VERSION "12.2.7"

NS_ :

BS_:

BU_: BMS_Tester EDS_F EDS_R EPS2 FCAM_PT GS IDB_PT POD RCU_PT VCU_PT XGW_PT

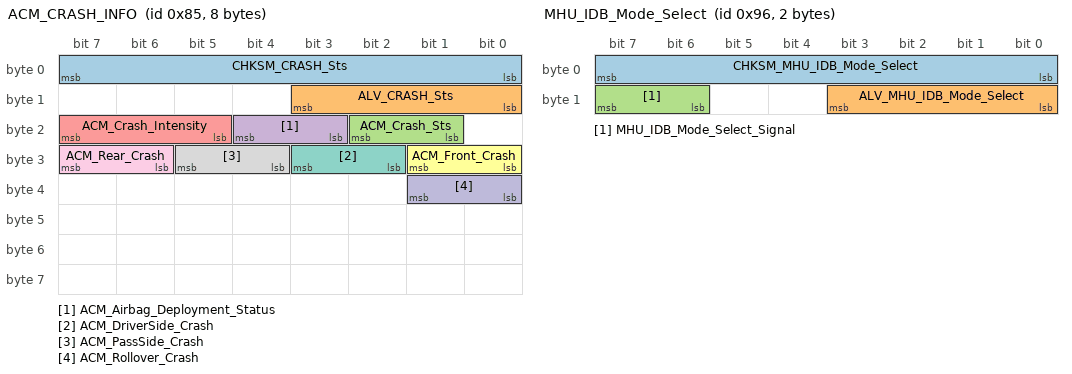
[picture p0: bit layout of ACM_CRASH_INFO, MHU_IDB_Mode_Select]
BO_ 133 ACM_CRASH_INFO: 8 XGW_PT
 SG_ CHKSM_CRASH_Sts : 7|8@0+ (1,0) [0|255] ""  EDS_F,EDS_R,IDB_PT,VCU_PT
 SG_ ALV_CRASH_Sts : 11|4@0+ (1,0) [0|14] ""  EDS_F,EDS_R,IDB_PT,VCU_PT
 SG_ ACM_Crash_Sts : 18|2@0+ (1,0) [0|3] ""  EDS_F,EDS_R,IDB_PT,VCU_PT
 SG_ ACM_Airbag_Deployment_Status : 20|2@0+ (1,0) [0|3] "-"  IDB_PT,VCU_PT
 SG_ ACM_Crash_Intensity : 23|3@0+ (1,0) [0|7] ""  IDB_PT,VCU_PT
 SG_ ACM_Front_Crash : 25|2@0+ (1,0) [0|3] "-"  IDB_PT,VCU_PT
 SG_ ACM_DriverSide_Crash : 27|2@0+ (1,0) [0|3] ""  IDB_PT,VCU_PT
 SG_ ACM_PassSide_Crash : 29|2@0+ (1,0) [0|3] "-"  IDB_PT,VCU_PT
 SG_ ACM_Rear_Crash : 31|2@0+ (1,0) [0|3] "-"  IDB_PT,VCU_PT
 SG_ ACM_Rollover_Crash : 33|2@0+ (1,0) [0|3] "-"  IDB_PT,VCU_PT

BO_ 147 IDB_MILEAGE: 4 IDB_PT
 SG_ CHKSM_MILEAGE : 7|8@0+ (1,0) [0|255] ""  FCAM_PT,XGW_PT
 SG_ ALIVE_MILEAGE : 11|4@0+ (1,0) [0|14] ""  FCAM_PT,XGW_PT
 SG_ Mileage : 23|16@0+ (1,0) [0|65535] "cm"  FCAM_PT,XGW_PT

BO_ 148 VCU_PUMP_STATUS: 8 VCU_PT
 SG_ VCU_Pump_3_Stt : 7|3@0+ (1,0) [0|3] ""  POD
 SG_ VCU_Pump_3_Flowrate : 15|8@0+ (0.1,0) [0|25.4] "l/min"  POD

BO_ 149 IDB_FUNCTION: 8 IDB_PT
 SG_ CHKSM_IDB_FUNCTION : 7|8@0+ (1,0) [0|255] ""  EDS_F,EDS_R,FCAM_PT,VCU_PT,XGW_PT
 SG_ ALV_IDB_FUNCTION : 11|4@0+ (1,0) [0|14] ""  EDS_F,EDS_R,FCAM_PT,VCU_PT,XGW_PT
 SG_ STAT_ABS : 13|2@0+ (1,0) [0|3] ""  VCU_PT,XGW_PT
 SG_ ABS_Active : 15|2@0+ (1,0) [0|3] ""  EDS_F,EDS_R,FCAM_PT,VCU_PT,XGW_PT
 SG_ AYC_Active : 17|2@0+ (1,0) [0|3] "Bit"  FCAM_PT,VCU_PT,XGW_PT
 SG_ ASR_Active : 19|2@0+ (1,0) [0|3] "-"  EDS_F,EDS_R,FCAM_PT,VCU_PT,XGW_PT
 SG_ STAT_DSC : 21|2@0+ (1,0) [0|3] "-"  FCAM_PT,VCU_PT,XGW_PT
 SG_ DSC_Active : 23|2@0+ (1,0) [0|3] ""  FCAM_PT,VCU_PT,XGW_PT
 SG_ HBA_ActiveSignal : 25|2@0+ (1,0) [0|3] ""  FCAM_PT,VCU_PT,XGW_PT
 SG_ ARM_ActiveSignal : 27|2@0+ (1,0) [0|3] "-"  VCU_PT,XGW_PT
 SG_ STAT_AutoHazardBlinking : 29|2@0+ (1,0) [0|3] "Bit"  VCU_PT,XGW_PT
 SG_ MSR_Active : 31|2@0+ (1,0) [0|3] "-"  FCAM_PT,VCU_PT,XGW_PT
 SG_ HSA_ActiveSignal : 33|2@0+ (1,0) [0|3] ""  FCAM_PT,VCU_PT,XGW_PT
 SG_ EPBi_ECD_ActiveSignal : 35|2@0+ (1,0) [0|3] ""  FCAM_PT,VCU_PT,XGW_PT
 SG_ TSM_Active : 37|2@0+ (1,0) [0|3] "-"  FCAM_PT,VCU_PT,XGW_PT
 SG_ HAS_Available : 41|2@0+ (1,0) [0|3] ""  FCAM_PT,VCU_PT,XGW_PT
 SG_ STAT_EBD : 43|2@0+ (1,0) [0|3] ""  VCU_PT,XGW_PT
 SG_ EBD_Active : 45|2@0+ (1,0) [0|3] ""  FCAM_PT,VCU_PT,XGW_PT
 SG_ ST_BRG_MSA : 55|4@0+ (1,0) [0|15] ""  VCU_PT,XGW_PT

BO_ 150 MHU_IDB_Mode_Select: 2 XGW_PT
 SG_ CHKSM_MHU_IDB_Mode_Select : 7|8@0+ (1,0) [0|255] ""  IDB_PT
 SG_ ALV_MHU_IDB_Mode_Select : 11|4@0+ (1,0) [0|14] ""  IDB_PT
 SG_ MHU_IDB_Mode_Select_Signal : 15|2@0+ (1,0) [0|3] ""  IDB_PT

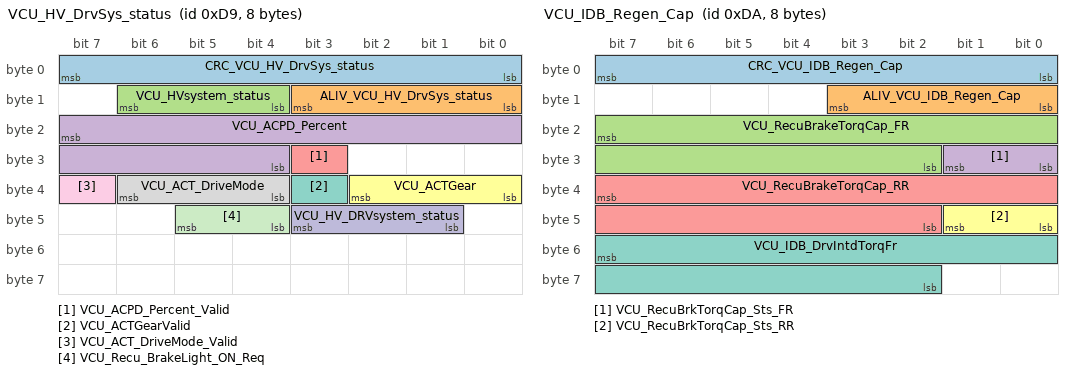
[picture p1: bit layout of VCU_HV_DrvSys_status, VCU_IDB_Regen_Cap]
BO_ 217 VCU_HV_DrvSys_status: 8 VCU_PT
 SG_ CRC_VCU_HV_DrvSys_status : 7|8@0+ (1,0) [0|255] ""  EDS_F,EDS_R,EPS2,FCAM_PT,GS,IDB_PT,RCU_PT,XGW_PT
 SG_ ALIV_VCU_HV_DrvSys_status : 11|4@0+ (1,0) [0|14] ""  EDS_F,EDS_R,EPS2,FCAM_PT,GS,IDB_PT,RCU_PT,XGW_PT
 SG_ VCU_HVsystem_status : 14|3@0+ (1,0) [0|7] "-"  EDS_F,EDS_R,EPS2,FCAM_PT,IDB_PT,XGW_PT
 SG_ VCU_ACPD_Percent : 23|12@0+ (0.0625,0) [0|100] "%"  FCAM_PT,IDB_PT,RCU_PT,XGW_PT
 SG_ VCU_ACPD_Percent_Valid : 27|1@0+ (1,0) [0|1] ""  FCAM_PT,IDB_PT,RCU_PT,XGW_PT
 SG_ VCU_ACTGear : 34|3@0+ (1,0) [0|7] ""  FCAM_PT,EPS2,GS,IDB_PT,RCU_PT,XGW_PT
 SG_ VCU_ACTGearValid : 35|1@0+ (1,0) [0|1] ""  FCAM_PT,EPS2,GS,IDB_PT,XGW_PT
 SG_ VCU_ACT_DriveMode : 38|3@0+ (1,0) [0|7] ""  FCAM_PT,XGW_PT
 SG_ VCU_ACT_DriveMode_Valid : 39|1@0+ (1,0) [0|1] "-"  XGW_PT
 SG_ VCU_HV_DRVsystem_status : 43|3@0+ (1,0) [0|7] ""  FCAM_PT,XGW_PT
 SG_ VCU_Recu_BrakeLight_ON_Req : 45|2@0+ (1,0) [0|3] "-"  XGW_PT

BO_ 218 VCU_IDB_Regen_Cap: 8 VCU_PT
 SG_ CRC_VCU_IDB_Regen_Cap : 7|8@0+ (1,0) [0|255] ""  IDB_PT
 SG_ ALIV_VCU_IDB_Regen_Cap : 11|4@0+ (1,0) [0|14] ""  IDB_PT
 SG_ VCU_RecuBrakeTorqCap_FR : 23|14@0- (1,0) [-8000|8000] "Nm"  IDB_PT
 SG_ VCU_RecuBrkTorqCap_Sts_FR : 25|2@0+ (1,0) [0|3] ""  IDB_PT
 SG_ VCU_RecuBrakeTorqCap_RR : 39|14@0- (1,0) [-8000|8000] "Nm"  IDB_PT
 SG_ VCU_RecuBrkTorqCap_Sts_RR : 41|2@0+ (1,0) [0|3] ""  IDB_PT
 SG_ VCU_IDB_DrvIntdTorqFr : 55|14@0- (1,0) [-8000|8000] "Nm"  IDB_PT

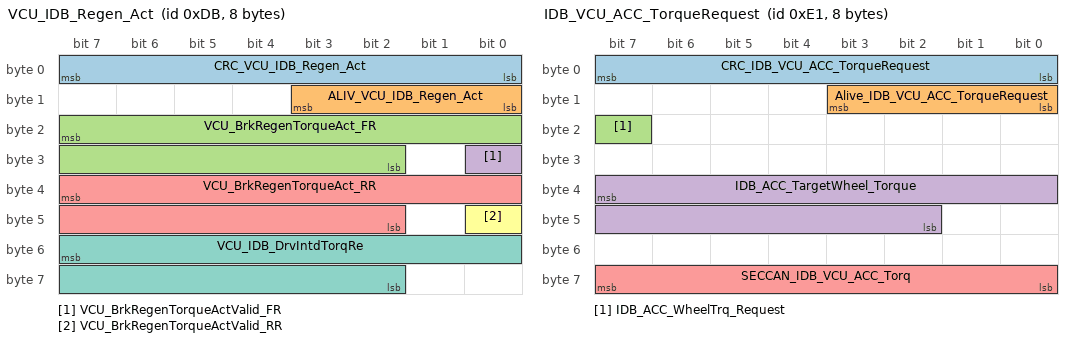
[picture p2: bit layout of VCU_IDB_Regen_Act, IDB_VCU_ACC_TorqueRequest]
BO_ 219 VCU_IDB_Regen_Act: 8 VCU_PT
 SG_ CRC_VCU_IDB_Regen_Act : 7|8@0+ (1,0) [0|255] ""  IDB_PT
 SG_ ALIV_VCU_IDB_Regen_Act : 11|4@0+ (1,0) [0|14] ""  IDB_PT
 SG_ VCU_BrkRegenTorqueAct_FR : 23|14@0- (1,0) [-8000|8000] "Nm"  IDB_PT
 SG_ VCU_BrkRegenTorqueActValid_FR : 24|1@0+ (1,0) [0|1] ""  IDB_PT
 SG_ VCU_BrkRegenTorqueAct_RR : 39|14@0- (1,0) [-8000|8000] "Nm"  IDB_PT
 SG_ VCU_BrkRegenTorqueActValid_RR : 40|1@0+ (1,0) [0|1] ""  IDB_PT
 SG_ VCU_IDB_DrvIntdTorqRe : 55|14@0- (1,0) [-8000|8000] "Nm"  IDB_PT

BO_ 225 IDB_VCU_ACC_TorqueRequest: 8 IDB_PT
 SG_ CRC_IDB_VCU_ACC_TorqueRequest : 7|8@0+ (1,0) [0|255] ""  VCU_PT
 SG_ Alive_IDB_VCU_ACC_TorqueRequest : 11|4@0+ (1,0) [0|14] ""  VCU_PT
 SG_ IDB_ACC_WheelTrq_Request : 23|1@0+ (1,0) [0|1] ""  VCU_PT
 SG_ IDB_ACC_TargetWheel_Torque : 39|14@0- (1,0) [-8000|8000] "Nm"  VCU_PT
 SG_ SECCAN_IDB_VCU_ACC_Torq : 63|8@0+ (1,0) [0|255] ""  VCU_PT

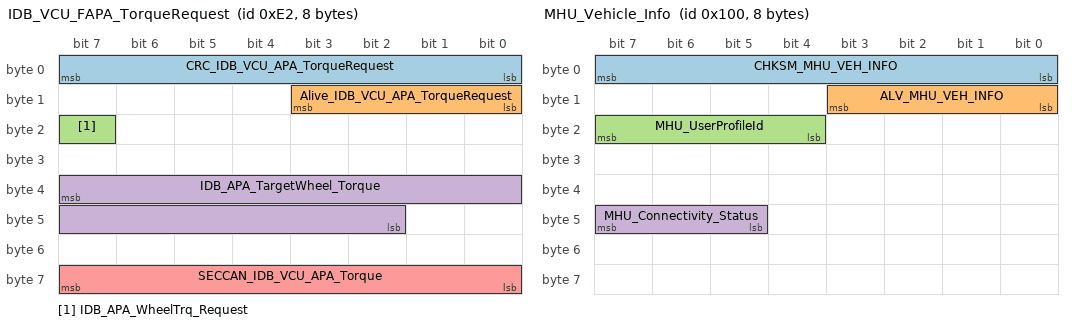
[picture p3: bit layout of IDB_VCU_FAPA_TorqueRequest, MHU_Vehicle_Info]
BO_ 226 IDB_VCU_FAPA_TorqueRequest: 8 IDB_PT
 SG_ CRC_IDB_VCU_APA_TorqueRequest : 7|8@0+ (1,0) [0|255] ""  VCU_PT
 SG_ Alive_IDB_VCU_APA_TorqueRequest : 11|4@0+ (1,0) [0|14] ""  VCU_PT
 SG_ IDB_APA_WheelTrq_Request : 23|1@0+ (1,0) [0|1] ""  VCU_PT
 SG_ IDB_APA_TargetWheel_Torque : 39|14@0- (1,0) [-8000|8000] "Nm"  VCU_PT
 SG_ SECCAN_IDB_VCU_APA_Torque : 63|8@0+ (1,0) [0|255] ""  VCU_PT

BO_ 256 MHU_Vehicle_Info: 8 XGW_PT
 SG_ CHKSM_MHU_VEH_INFO : 7|8@0+ (1,0) [0|255] ""  VCU_PT
 SG_ ALV_MHU_VEH_INFO : 11|4@0+ (1,0) [0|14] ""  VCU_PT
 SG_ MHU_UserProfileId : 23|4@0+ (1,0) [0|15] "-"  VCU_PT
 SG_ MHU_Connectivity_Status : 47|3@0+ (1,0) [0|7] ""  VCU_PT

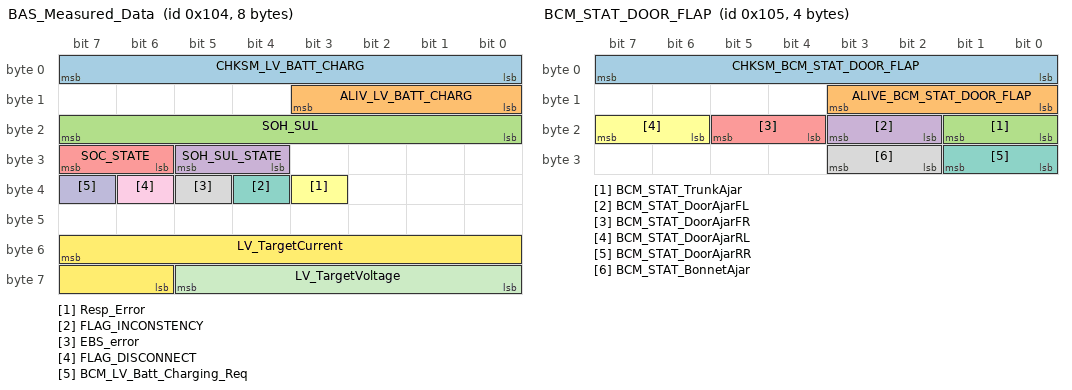
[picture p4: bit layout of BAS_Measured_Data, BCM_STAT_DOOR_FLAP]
BO_ 260 BAS_Measured_Data: 8 XGW_PT
 SG_ CHKSM_LV_BATT_CHARG : 7|8@0+ (1,0) [0|255] ""  VCU_PT
 SG_ ALIV_LV_BATT_CHARG : 11|4@0+ (1,0) [0|14] ""  VCU_PT
 SG_ SOH_SUL : 23|8@0+ (1,0) [0|100] "%"  VCU_PT
 SG_ SOH_SUL_STATE : 29|2@0+ (1,0) [0|3] ""  VCU_PT
 SG_ SOC_STATE : 31|2@0+ (1,0) [0|3] "%"  VCU_PT
 SG_ Resp_Error : 35|1@0+ (1,0) [0|1] ""  VCU_PT
 SG_ FLAG_INCONSTENCY : 36|1@0+ (1,0) [0|1] "%"  VCU_PT
 SG_ EBS_error : 37|1@0+ (1,0) [0|1] ""  VCU_PT
 SG_ FLAG_DISCONNECT : 38|1@0+ (1,0) [0|1] ""  VCU_PT
 SG_ BCM_LV_Batt_Charging_Req : 39|1@0+ (1,0) [0|1] ""  VCU_PT
 SG_ LV_TargetVoltage : 61|6@0+ (0.112903,9) [9|16] "V"  VCU_PT
 SG_ LV_TargetCurrent : 55|10@0+ (0.25,-128) [-128|127] "A"  VCU_PT

BO_ 261 BCM_STAT_DOOR_FLAP: 4 XGW_PT
 SG_ CHKSM_BCM_STAT_DOOR_FLAP : 7|8@0+ (1,0) [0|255] ""  IDB_PT,RCU_PT,VCU_PT
 SG_ ALIVE_BCM_STAT_DOOR_FLAP : 11|4@0+ (1,0) [0|14] ""  IDB_PT,RCU_PT,VCU_PT
 SG_ BCM_STAT_TrunkAjar : 17|2@0+ (1,0) [0|3] "Bit"  IDB_PT,VCU_PT
 SG_ BCM_STAT_DoorAjarFL : 19|2@0+ (1,0) [0|3] "Bit"  IDB_PT,RCU_PT,VCU_PT
 SG_ BCM_STAT_DoorAjarFR : 21|2@0+ (1,0) [0|3] "Bit"  IDB_PT,VCU_PT
 SG_ BCM_STAT_DoorAjarRL : 23|2@0+ (1,0) [0|3] "Bit"  IDB_PT,VCU_PT
 SG_ BCM_STAT_DoorAjarRR : 25|2@0+ (1,0) [0|3] "Bit"  IDB_PT,VCU_PT
 SG_ BCM_STAT_BonnetAjar : 27|2@0+ (1,0) [0|3] "Bit"  IDB_PT,VCU_PT

BO_ 264 GS_DriveReq: 3 GS
 SG_ CHKSM_GS_DriveReq : 7|8@0+ (1,0) [0|255] ""  VCU_PT
 SG_ ALIVE_GS_DriveReq : 11|4@0+ (1,0) [0|14] ""  VCU_PT
 SG_ GS_TargetGearReq : 23|3@0+ (1,0) [0|7] ""  VCU_PT

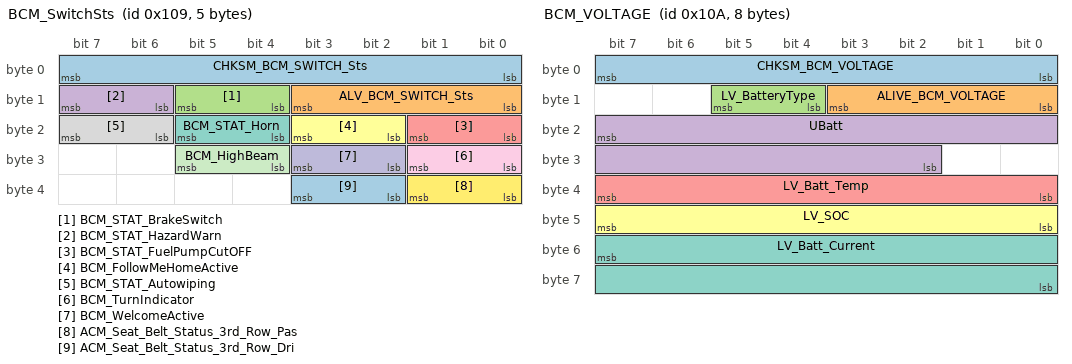
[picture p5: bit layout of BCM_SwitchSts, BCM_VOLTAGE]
BO_ 265 BCM_SwitchSts: 5 XGW_PT
 SG_ CHKSM_BCM_SWITCH_Sts : 7|8@0+ (1,0) [0|255] ""  IDB_PT,RCU_PT,VCU_PT
 SG_ ALV_BCM_SWITCH_Sts : 11|4@0+ (1,0) [0|14] ""  IDB_PT,RCU_PT,VCU_PT
 SG_ BCM_STAT_BrakeSwitch : 13|2@0+ (1,0) [0|3] ""  IDB_PT,RCU_PT,VCU_PT
 SG_ BCM_STAT_HazardWarn : 15|2@0+ (1,0) [0|3] "-"  VCU_PT
 SG_ BCM_STAT_FuelPumpCutOFF : 17|2@0+ (1,0) [0|3] ""  VCU_PT
 SG_ BCM_FollowMeHomeActive : 19|2@0+ (1,0) [0|3] ""  VCU_PT
 SG_ BCM_STAT_Horn : 21|2@0+ (1,0) [0|3] "-"  VCU_PT
 SG_ BCM_STAT_Autowiping : 23|2@0+ (1,0) [0|3] ""  IDB_PT,VCU_PT
 SG_ BCM_TurnIndicator : 25|2@0+ (1,0) [0|3] ""  VCU_PT
 SG_ BCM_WelcomeActive : 27|2@0+ (1,0) [0|3] "-"  VCU_PT
 SG_ BCM_HighBeam : 29|2@0+ (1,0) [0|3] ""  VCU_PT
 SG_ ACM_Seat_Belt_Status_3rd_Row_Pas : 33|2@0+ (1,0) [0|3] ""  VCU_PT
 SG_ ACM_Seat_Belt_Status_3rd_Row_Dri : 35|2@0+ (1,0) [0|3] "-"  VCU_PT

BO_ 266 BCM_VOLTAGE: 8 XGW_PT
 SG_ CHKSM_BCM_VOLTAGE : 7|8@0+ (1,0) [0|255] ""  EDS_F,EDS_R,EPS2,GS,IDB_PT,POD,RCU_PT,VCU_PT
 SG_ ALIVE_BCM_VOLTAGE : 11|4@0+ (1,0) [0|14] ""  EDS_F,EDS_R,EPS2,GS,IDB_PT,POD,RCU_PT,VCU_PT
 SG_ LV_BatteryType : 13|2@0+ (1,0) [0|3] "Number"  VCU_PT
 SG_ UBatt : 23|14@0+ (0.0009777,3) [3|18] "V"  EDS_F,EDS_R,EPS2,GS,IDB_PT,POD,RCU_PT,VCU_PT
 SG_ LV_Batt_Temp : 39|8@0+ (1,-40) [-40|105] "Degree C"  EDS_F,EDS_R,EPS2,GS,IDB_PT,POD,RCU_PT,VCU_PT
 SG_ LV_SOC : 47|8@0+ (1,0) [0|100] "%"  EDS_F,EDS_R,EPS2,GS,IDB_PT,POD,RCU_PT,VCU_PT
 SG_ LV_Batt_Current : 55|16@0+ (0.03125,-1536) [-1536|511.90625] "A"  EDS_F,EDS_R,EPS2,GS,IDB_PT,POD,RCU_PT,VCU_PT

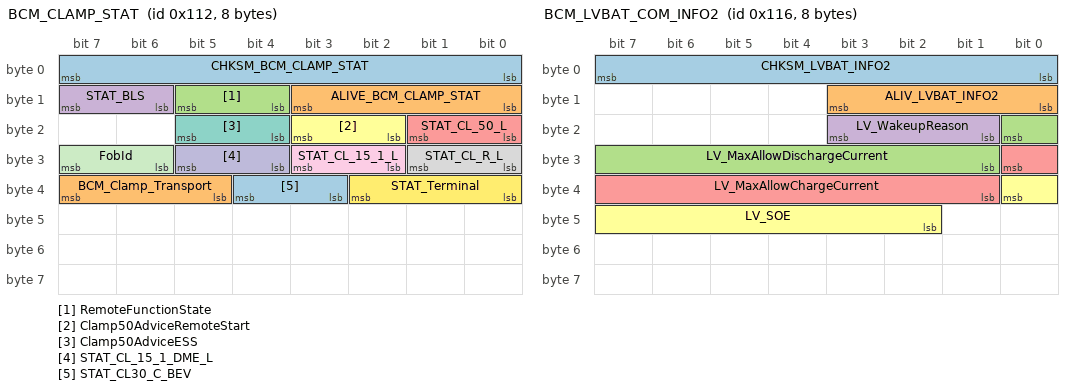
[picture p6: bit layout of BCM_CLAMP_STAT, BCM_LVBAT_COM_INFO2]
BO_ 274 BCM_CLAMP_STAT: 8 XGW_PT
 SG_ CHKSM_BCM_CLAMP_STAT : 7|8@0+ (1,0) [0|255] ""  EDS_F,EDS_R,EPS2,FCAM_PT,GS,IDB_PT,POD,RCU_PT,VCU_PT
 SG_ ALIVE_BCM_CLAMP_STAT : 11|4@0+ (1,0) [0|14] ""  EDS_F,EDS_R,EPS2,FCAM_PT,GS,IDB_PT,POD,RCU_PT,VCU_PT
 SG_ RemoteFunctionState : 13|2@0+ (1,0) [0|3] ""  EDS_F,EDS_R,EPS2,FCAM_PT,GS,IDB_PT,POD,RCU_PT,VCU_PT
 SG_ STAT_BLS : 15|2@0+ (1,0) [0|3] "-"  EDS_F,EDS_R,EPS2,FCAM_PT,GS,IDB_PT,POD,RCU_PT,VCU_PT
 SG_ STAT_CL_50_L : 17|2@0+ (1,0) [0|3] ""  EDS_F,EDS_R,EPS2,FCAM_PT,GS,IDB_PT,POD,RCU_PT,VCU_PT
 SG_ Clamp50AdviceRemoteStart : 19|2@0+ (1,0) [0|3] "-"  EDS_F,EDS_R,EPS2,FCAM_PT,GS,IDB_PT,POD,RCU_PT,VCU_PT
 SG_ Clamp50AdviceESS : 21|2@0+ (1,0) [0|3] "-"  EDS_F,EDS_R,EPS2,FCAM_PT,GS,IDB_PT,POD,RCU_PT,VCU_PT
 SG_ STAT_CL_R_L : 25|2@0+ (1,0) [0|3] ""  EDS_F,EDS_R,EPS2,FCAM_PT,GS,IDB_PT,POD,RCU_PT,VCU_PT
 SG_ STAT_CL_15_1_L : 27|2@0+ (1,0) [0|3] "-"  EDS_F,EDS_R,EPS2,FCAM_PT,GS,IDB_PT,POD,RCU_PT,VCU_PT
 SG_ STAT_CL_15_1_DME_L : 29|2@0+ (1,0) [0|3] ""  EDS_F,EDS_R,EPS2,FCAM_PT,GS,IDB_PT,POD,RCU_PT,VCU_PT
 SG_ FobId : 31|2@0+ (1,0) [0|3] "Bit"  EDS_F,EDS_R,FCAM_PT,EPS2,GS,IDB_PT,POD,RCU_PT,VCU_PT
 SG_ STAT_Terminal : 34|3@0+ (1,0) [0|7] "Bit"  EDS_F,EDS_R,EPS2,FCAM_PT,GS,IDB_PT,POD,RCU_PT,VCU_PT
 SG_ STAT_CL30_C_BEV : 36|2@0+ (1,0) [0|3] "Bit"  EDS_F,EDS_R,EPS2,FCAM_PT,GS,IDB_PT,POD,RCU_PT,VCU_PT
 SG_ BCM_Clamp_Transport : 39|3@0+ (1,0) [0|7] ""  EDS_F,EDS_R,EPS2,FCAM_PT,GS,IDB_PT,POD,RCU_PT,VCU_PT

BO_ 278 BCM_LVBAT_COM_INFO2: 8 XGW_PT
 SG_ CHKSM_LVBAT_INFO2 : 7|8@0+ (1,0) [0|255] ""  VCU_PT
 SG_ ALIV_LVBAT_INFO2 : 11|4@0+ (1,0) [0|14] ""  VCU_PT
 SG_ LV_MaxAllowDischargeCurrent : 16|8@0+ (1,0) [0|253] "A"  VCU_PT
 SG_ LV_WakeupReason : 19|3@0+ (1,0) [0|7] "" Vector__XXX
 SG_ LV_MaxAllowChargeCurrent : 24|8@0+ (1,0) [0|253] "A"  VCU_PT
 SG_ LV_SOE : 32|7@0+ (1,0) [0|100] "%"  VCU_PT

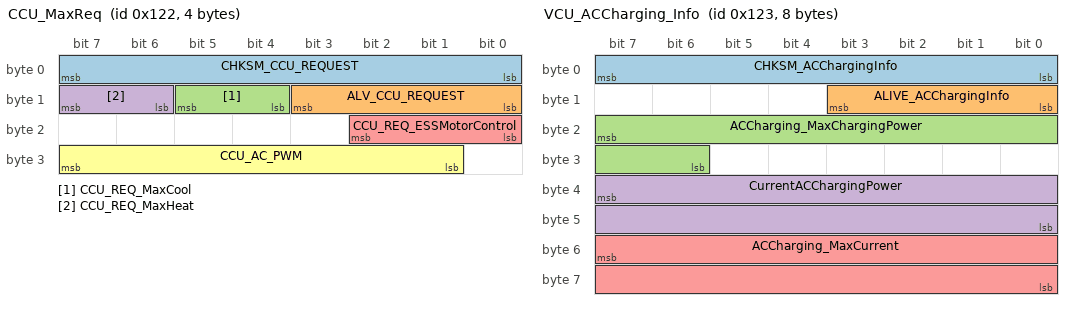
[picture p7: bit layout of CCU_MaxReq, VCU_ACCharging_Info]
BO_ 290 CCU_MaxReq: 4 XGW_PT
 SG_ CHKSM_CCU_REQUEST : 7|8@0+ (1,0) [0|255] ""  VCU_PT
 SG_ ALV_CCU_REQUEST : 11|4@0+ (1,0) [0|14] ""  VCU_PT
 SG_ CCU_REQ_MaxCool : 13|2@0+ (1,0) [0|3] ""  VCU_PT
 SG_ CCU_REQ_MaxHeat : 15|2@0+ (1,0) [0|3] ""  VCU_PT
 SG_ CCU_REQ_ESSMotorControl : 18|3@0+ (1,0) [0|7] "Bit"  VCU_PT
 SG_ CCU_AC_PWM : 31|7@0+ (1,0) [0|100] "%"  VCU_PT

BO_ 291 VCU_ACCharging_Info: 8 VCU_PT
 SG_ CHKSM_ACChargingInfo : 7|8@0+ (1,0) [0|255] ""  XGW_PT
 SG_ ALIVE_ACChargingInfo : 11|4@0+ (1,0) [0|14] ""  XGW_PT
 SG_ ACCharging_MaxChargingPower : 23|10@0+ (0.1,0) [0|102.2] "kW"  XGW_PT
 SG_ CurrentACChargingPower : 39|16@0+ (0.1,0) [0|6553.5] "kW"  XGW_PT
 SG_ ACCharging_MaxCurrent : 55|16@0+ (0.1,0) [0|3276.7] "A"  XGW_PT

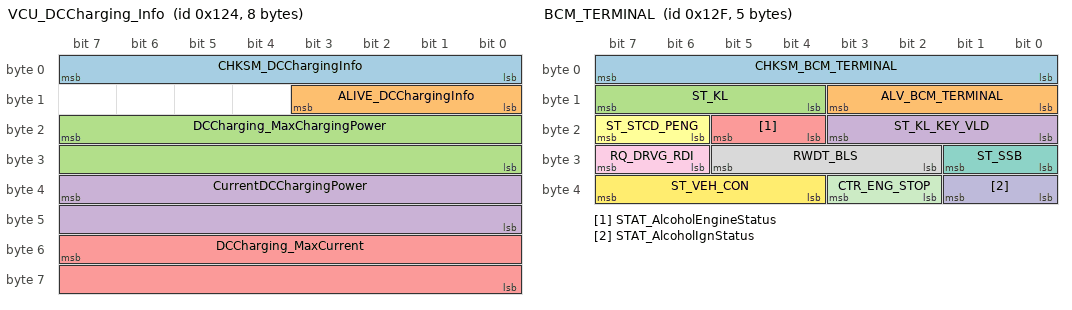
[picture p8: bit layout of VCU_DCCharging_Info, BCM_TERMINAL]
BO_ 292 VCU_DCCharging_Info: 8 VCU_PT
 SG_ CHKSM_DCChargingInfo : 7|8@0+ (1,0) [0|255] ""  XGW_PT
 SG_ ALIVE_DCChargingInfo : 11|4@0+ (1,0) [0|14] ""  XGW_PT
 SG_ DCCharging_MaxChargingPower : 23|16@0+ (0.1,0) [0|6553.5] "kW"  XGW_PT
 SG_ CurrentDCChargingPower : 39|16@0+ (0.1,0) [0|6553.5] "kW"  XGW_PT
 SG_ DCCharging_MaxCurrent : 55|16@0+ (0.1,0) [0|3276.7] "A"  XGW_PT

BO_ 303 BCM_TERMINAL: 5 XGW_PT
 SG_ CHKSM_BCM_TERMINAL : 7|8@0+ (1,0) [0|255] ""  GS,IDB_PT,POD,VCU_PT
 SG_ ALV_BCM_TERMINAL : 11|4@0+ (1,0) [0|14] ""  GS,IDB_PT,POD,VCU_PT
 SG_ ST_KL : 15|4@0+ (1,0) [0|15] "-"  GS,IDB_PT,POD,VCU_PT
 SG_ ST_KL_KEY_VLD : 19|4@0+ (1,0) [0|15] ""  POD,VCU_PT
 SG_ STAT_AlcoholEngineStatus : 21|2@0+ (1,0) [0|3] "" Vector__XXX
 SG_ ST_STCD_PENG : 23|2@0+ (1,0) [0|3] ""  POD,VCU_PT
 SG_ ST_SSB : 25|2@0+ (1,0) [0|3] "-"  POD,VCU_PT
 SG_ RWDT_BLS : 29|4@0+ (1,0) [0|15] "-"  IDB_PT,POD,VCU_PT
 SG_ RQ_DRVG_RDI : 31|2@0+ (1,0) [0|3] ""  POD,VCU_PT
 SG_ STAT_AlcoholIgnStatus : 33|2@0+ (1,0) [0|3] ""  VCU_PT
 SG_ CTR_ENG_STOP : 35|2@0+ (1,0) [0|3] "Bit"  GS,IDB_PT,POD,VCU_PT
 SG_ ST_VEH_CON : 39|4@0+ (1,0) [0|15] "-"  GS

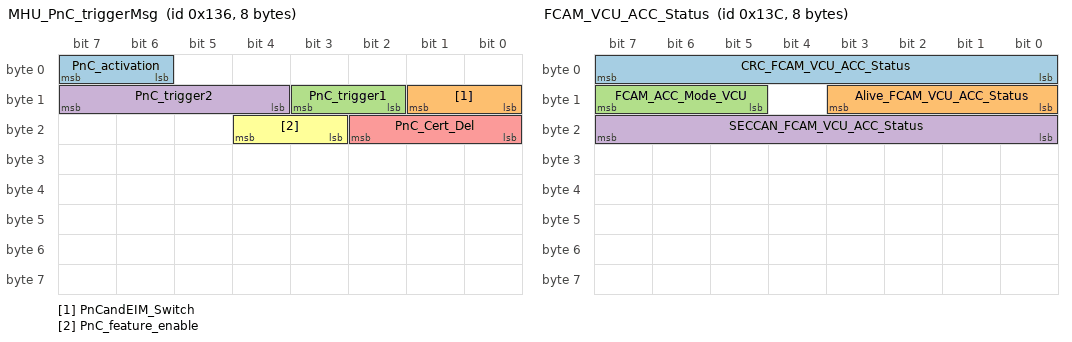
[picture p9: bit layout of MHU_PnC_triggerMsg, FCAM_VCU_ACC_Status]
BO_ 310 MHU_PnC_triggerMsg: 8 XGW_PT
 SG_ PnC_activation : 7|2@0+ (1,0) [0|3] ""  VCU_PT
 SG_ PnCandEIM_Switch : 9|2@0+ (1,0) [0|3] ""  VCU_PT
 SG_ PnC_trigger1 : 11|2@0+ (1,0) [0|3] ""  VCU_PT
 SG_ PnC_trigger2 : 15|4@0+ (1,0) [0|15] ""  VCU_PT
 SG_ PnC_Cert_Del : 18|3@0+ (1,0) [0|7] ""  VCU_PT
 SG_ PnC_feature_enable : 20|2@0+ (1,0) [0|3] ""  VCU_PT

BO_ 311 VCU_PnC_ErrorMsg: 8 VCU_PT
 SG_ OK_OldSessionJoined : 1|2@0+ (1,0) [0|3] ""  XGW_PT
 SG_ OK_NewSessionEstablished : 3|2@0+ (1,0) [0|3] ""  XGW_PT
 SG_ OK_CertificateExpireSoon : 5|2@0+ (1,0) [0|3] ""  XGW_PT
 SG_ PnC_OK : 7|2@0+ (1,0) [0|3] ""  XGW_PT
 SG_ Failed_CertificateNoAllowAtEVSE : 9|2@0+ (1,0) [0|3] ""  XGW_PT
 SG_ Failed_ContactorError : 11|2@0+ (1,0) [0|3] ""  XGW_PT
 SG_ Failed_NoChargeServiceSelectd : 13|2@0+ (1,0) [0|3] ""  XGW_PT
 SG_ PnC_Failed : 15|2@0+ (1,0) [0|3] ""  XGW_PT
 SG_ Failed_ServiceIDInvalid : 17|2@0+ (1,0) [0|3] ""  XGW_PT
 SG_ Falied_UnknownSession : 19|2@0+ (1,0) [0|3] ""  XGW_PT
 SG_ Failed_SignatureError : 21|2@0+ (1,0) [0|3] ""  XGW_PT
 SG_ Failed_SequenceError : 23|2@0+ (1,0) [0|3] ""  XGW_PT
 SG_ Failed_CertChainError : 25|2@0+ (1,0) [0|3] ""  XGW_PT
 SG_ Failed_NoCertificateAvailable : 27|2@0+ (1,0) [0|3] ""  XGW_PT
 SG_ Failed_CertificateRevoked : 29|2@0+ (1,0) [0|3] ""  XGW_PT
 SG_ Failed_PaymentSelectionInvalid : 31|2@0+ (1,0) [0|3] ""  XGW_PT
 SG_ Failed_WrongChargeParameter : 33|2@0+ (1,0) [0|3] ""  XGW_PT
 SG_ Failed_WrongEnergyTranferMode : 35|2@0+ (1,0) [0|3] ""  XGW_PT
 SG_ Failed_ChallengeInvalid : 37|2@0+ (1,0) [0|3] ""  XGW_PT
 SG_ Failed_ContractCancelled : 39|2@0+ (1,0) [0|3] ""  XGW_PT
 SG_ Failed_MeteringSignatureNotValid : 41|2@0+ (1,0) [0|3] ""  XGW_PT
 SG_ Failed_PowerDeliverNotApplied : 43|2@0+ (1,0) [0|3] ""  XGW_PT
 SG_ Failed_TarrifSelectionInvalid : 45|2@0+ (1,0) [0|3] ""  XGW_PT
 SG_ Failed_ChargingProfileInvalid : 47|2@0+ (1,0) [0|3] ""  XGW_PT
 SG_ Error_message_4 : 49|2@0+ (1,0) [0|3] ""  XGW_PT
 SG_ Error_message_3 : 51|2@0+ (1,0) [0|3] ""  XGW_PT
 SG_ Error_message_1 : 53|2@0+ (1,0) [0|3] ""  XGW_PT
 SG_ Error_message_2 : 55|2@0+ (1,0) [0|3] ""  XGW_PT
 SG_ PnC_ChargeSessionEnded : 57|2@0+ (1,0) [0|3] ""  XGW_PT
 SG_ PnC_Status : 59|2@0+ (1,0) [0|3] ""  XGW_PT
 SG_ PnC_Contract_Status : 61|2@0+ (1,0) [0|3] ""  XGW_PT
 SG_ Error_message_5 : 63|2@0+ (1,0) [0|3] ""  XGW_PT

BO_ 316 FCAM_VCU_ACC_Status: 8 FCAM_PT
 SG_ CRC_FCAM_VCU_ACC_Status : 7|8@0+ (1,0) [0|255] ""  VCU_PT
 SG_ Alive_FCAM_VCU_ACC_Status : 11|4@0+ (1,0) [0|14] ""  VCU_PT
 SG_ FCAM_ACC_Mode_VCU : 15|3@0+ (1,0) [0|7] ""  VCU_PT
 SG_ SECCAN_FCAM_VCU_ACC_Status : 23|8@0+ (1,0) [0|255] ""  VCU_PT

BO_ 317 VCU_PnC_ErrorMsg_2: 8 VCU_PT
 SG_ SessionPaymentType : 7|2@0+ (1,0) [0|3] ""  XGW_PT

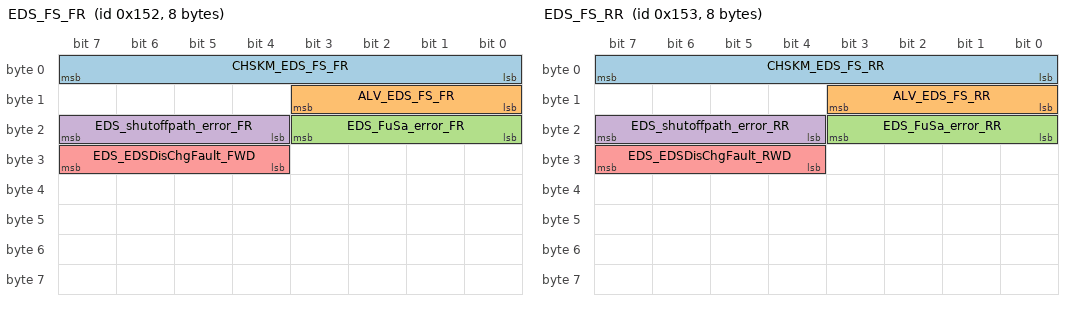
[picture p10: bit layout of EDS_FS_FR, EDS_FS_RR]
BO_ 338 EDS_FS_FR: 8 EDS_F
 SG_ CHSKM_EDS_FS_FR : 7|8@0+ (1,0) [0|255] ""  VCU_PT
 SG_ ALV_EDS_FS_FR : 11|4@0+ (1,0) [0|14] ""  VCU_PT
 SG_ EDS_FuSa_error_FR : 19|4@0+ (1,0) [0|15] ""  VCU_PT
 SG_ EDS_shutoffpath_error_FR : 23|4@0+ (1,0) [0|15] ""  VCU_PT
 SG_ EDS_EDSDisChgFault_FWD : 31|4@0+ (1,0) [0|15] ""  VCU_PT

BO_ 339 EDS_FS_RR: 8 EDS_R
 SG_ CHSKM_EDS_FS_RR : 7|8@0+ (1,0) [0|255] ""  VCU_PT
 SG_ ALV_EDS_FS_RR : 11|4@0+ (1,0) [0|14] ""  VCU_PT
 SG_ EDS_FuSa_error_RR : 19|4@0+ (1,0) [0|15] ""  VCU_PT
 SG_ EDS_shutoffpath_error_RR : 23|4@0+ (1,0) [0|15] ""  VCU_PT
 SG_ EDS_EDSDisChgFault_RWD : 31|4@0+ (1,0) [0|15] ""  VCU_PT

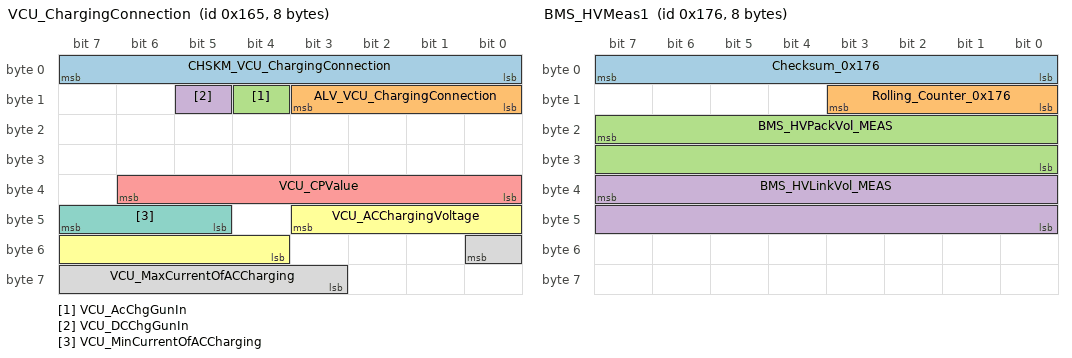
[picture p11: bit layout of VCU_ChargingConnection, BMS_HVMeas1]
BO_ 357 VCU_ChargingConnection: 8 VCU_PT
 SG_ CHSKM_VCU_ChargingConnection : 7|8@0+ (1,0) [0|255] ""  POD,XGW_PT
 SG_ ALV_VCU_ChargingConnection : 11|4@0+ (1,0) [0|14] ""  POD,XGW_PT
 SG_ VCU_AcChgGunIn : 12|1@0+ (1,0) [0|1] "-"  POD,XGW_PT
 SG_ VCU_DCChgGunIn : 13|1@0+ (1,0) [0|1] "-"  POD,XGW_PT
 SG_ VCU_CPValue : 38|7@0+ (1,0) [0|100] "%"  POD,XGW_PT
 SG_ VCU_ACChargingVoltage : 43|8@0+ (1,0) [0|255] "V"  POD,XGW_PT
 SG_ VCU_MinCurrentOfACCharging : 47|3@0+ (1,0) [0|7] "A"  POD,XGW_PT
 SG_ VCU_MaxCurrentOfACCharging : 48|6@0+ (1,0) [0|63] "A"  POD,XGW_PT

BO_ 359 VCU_TWV1_Frm: 8 VCU_PT
 SG_ TWV1_N_Position : 7|16@0+ (0.1,0) [0|100] "%"  XGW_PT
 SG_ TWV1_St_Feedback : 23|16@0+ (1,0) [0|15] ""  XGW_PT
 SG_ TWV1_Frm_Error : 39|1@0+ (1,0) [0|1] ""  XGW_PT

BO_ 372 BMS_CurMeas: 8 XGW_PT
 SG_ CHSKM_BMS_CurMeas : 7|8@0+ (1,0) [0|255] ""  POD,VCU_PT
 SG_ ALV_BMS_CurMeas : 11|4@0+ (1,0) [0|14] ""  POD,VCU_PT
 SG_ BMS_PackCur_MEAS : 23|16@0+ (0.1,-3276.8) [-3276.8|3276.7] "A"  POD,VCU_PT

BO_ 374 BMS_HVMeas1: 8 XGW_PT
 SG_ Checksum_0x176 : 7|8@0+ (1,0) [0|255] ""  EDS_F,EDS_R,VCU_PT
 SG_ Rolling_Counter_0x176 : 11|4@0+ (1,0) [0|14] ""  EDS_F,EDS_R,VCU_PT
 SG_ BMS_HVPackVol_MEAS : 23|16@0+ (0.1,0) [0|800] "V"  EDS_F,EDS_R,VCU_PT
 SG_ BMS_HVLinkVol_MEAS : 39|16@0+ (0.1,0) [0|800] "V"  VCU_PT

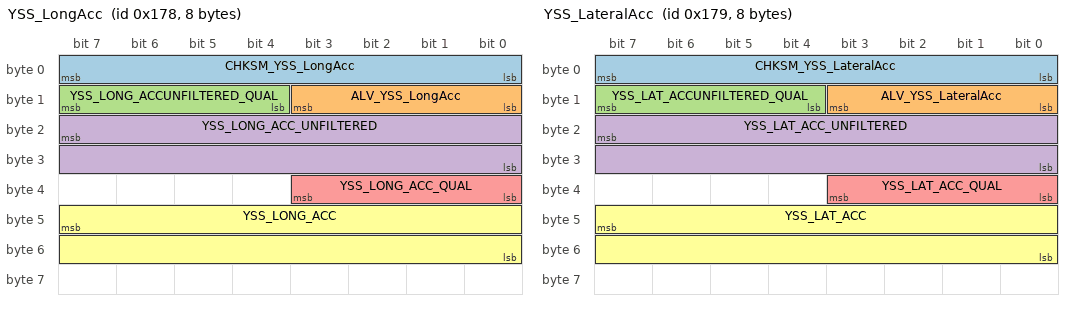
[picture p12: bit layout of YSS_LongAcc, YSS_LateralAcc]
BO_ 376 YSS_LongAcc: 8 XGW_PT
 SG_ CHKSM_YSS_LongAcc : 7|8@0+ (1,0) [0|255] ""  EPS2
 SG_ ALV_YSS_LongAcc : 11|4@0+ (1,0) [0|14] ""  EPS2
 SG_ YSS_LONG_ACCUNFILTERED_QUAL : 15|4@0+ (1,0) [0|15] ""  EPS2
 SG_ YSS_LONG_ACC_UNFILTERED : 23|16@0+ (0.002,-65.532) [-65.532|65.532] "m/s2"  EPS2
 SG_ YSS_LONG_ACC_QUAL : 35|4@0+ (1,0) [0|15] ""  EPS2
 SG_ YSS_LONG_ACC : 47|16@0+ (0.002,-65.532) [-65.532|65.532] "m/s2"  EPS2

BO_ 377 YSS_LateralAcc: 8 XGW_PT
 SG_ CHKSM_YSS_LateralAcc : 7|8@0+ (1,0) [0|255] ""  EPS2
 SG_ ALV_YSS_LateralAcc : 11|4@0+ (1,0) [0|14] ""  EPS2
 SG_ YSS_LAT_ACCUNFILTERED_QUAL : 15|4@0+ (1,0) [0|15] ""  EPS2
 SG_ YSS_LAT_ACC_UNFILTERED : 23|16@0+ (0.002,-65.532) [-65.532|65.532] "m/s2"  EPS2
 SG_ YSS_LAT_ACC_QUAL : 35|4@0+ (1,0) [0|15] ""  EPS2
 SG_ YSS_LAT_ACC : 47|16@0+ (0.002,-65.532) [-65.532|65.532] "m/s2"  EPS2

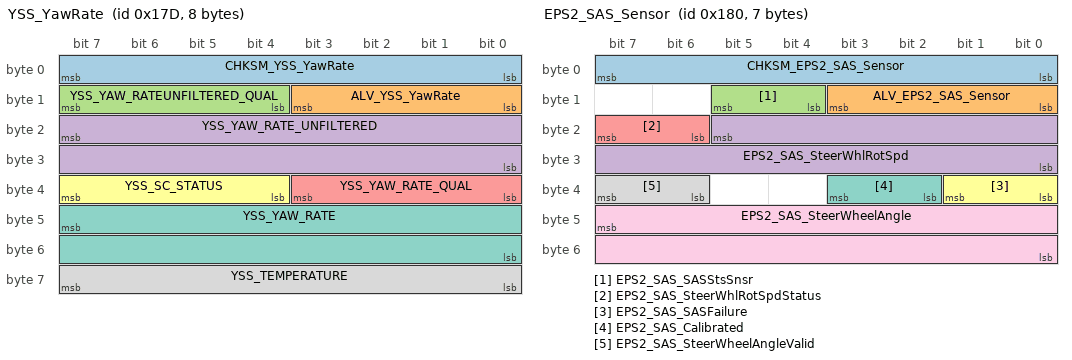
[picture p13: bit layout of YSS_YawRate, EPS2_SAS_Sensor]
BO_ 381 YSS_YawRate: 8 XGW_PT
 SG_ CHKSM_YSS_YawRate : 7|8@0+ (1,0) [0|255] ""  EPS2
 SG_ ALV_YSS_YawRate : 11|4@0+ (1,0) [0|14] ""  EPS2
 SG_ YSS_YAW_RATEUNFILTERED_QUAL : 15|4@0+ (1,0) [0|15] ""  EPS2
 SG_ YSS_YAW_RATE_UNFILTERED : 23|16@0+ (0.005,-163.83) [-163.83|163.83] "°/s"  EPS2
 SG_ YSS_YAW_RATE_QUAL : 35|4@0+ (1,0) [0|15] ""  EPS2
 SG_ YSS_SC_STATUS : 39|4@0+ (1,0) [0|15] ""  EPS2
 SG_ YSS_YAW_RATE : 47|16@0+ (0.005,-163.83) [-163.83|163.83] "°/s"  EPS2
 SG_ YSS_TEMPERATURE : 63|8@0+ (1,-40) [-40|115] "°C"  EPS2

BO_ 384 EPS2_SAS_Sensor: 7 EPS2
 SG_ CHKSM_EPS2_SAS_Sensor : 7|8@0+ (1,0) [0|255] ""  IDB_PT,RCU_PT,VCU_PT,XGW_PT
 SG_ ALV_EPS2_SAS_Sensor : 11|4@0+ (1,0) [0|14] ""  IDB_PT,RCU_PT,VCU_PT,XGW_PT
 SG_ EPS2_SAS_SASStsSnsr : 13|2@0+ (1,0) [0|1] ""  IDB_PT,RCU_PT,VCU_PT,XGW_PT
 SG_ EPS2_SAS_SteerWhlRotSpd : 21|14@0+ (0.125,-1024) [-1024|1023.75] "degree/s"  IDB_PT,RCU_PT,VCU_PT,XGW_PT
 SG_ EPS2_SAS_SteerWhlRotSpdStatus : 23|2@0+ (1,0) [0|1] ""  IDB_PT,RCU_PT,VCU_PT,XGW_PT
 SG_ EPS2_SAS_SASFailure : 33|2@0+ (1,0) [0|1] ""  IDB_PT,RCU_PT,VCU_PT,XGW_PT
 SG_ EPS2_SAS_Calibrated : 35|2@0+ (1,0) [0|1] ""  IDB_PT,RCU_PT,VCU_PT,XGW_PT
 SG_ EPS2_SAS_SteerWheelAngleValid : 39|2@0+ (1,0) [0|1] ""  IDB_PT,RCU_PT,VCU_PT,XGW_PT
 SG_ EPS2_SAS_SteerWheelAngle : 47|16@0+ (0.0238,-780) [-780|779.7] "deg"  IDB_PT,RCU_PT,VCU_PT,XGW_PT

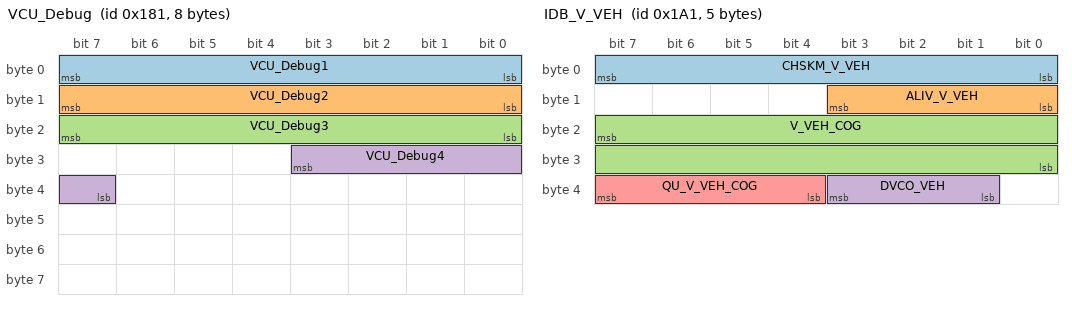
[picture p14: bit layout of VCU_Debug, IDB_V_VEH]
BO_ 385 VCU_Debug: 8 VCU_PT
 SG_ VCU_Debug1 : 7|8@0+ (1,0) [0|255] ""  XGW_PT
 SG_ VCU_Debug2 : 15|8@0+ (1,0) [0|255] ""  XGW_PT
 SG_ VCU_Debug3 : 23|8@0+ (1,0) [0|255] ""  XGW_PT
 SG_ VCU_Debug4 : 27|5@0+ (1,0) [0|31] ""  XGW_PT

BO_ 386 VCU_FS_A: 8 VCU_PT
 SG_ VCU_FS_A_1 : 0|1@0+ (1,0) [0|1] ""  XGW_PT
 SG_ VCU_FS_A_2 : 1|1@0+ (1,0) [0|1] ""  XGW_PT
 SG_ VCU_FS_A_3 : 2|1@0+ (1,0) [0|1] ""  XGW_PT
 SG_ VCU_FS_A_4 : 3|1@0+ (1,0) [0|1] ""  XGW_PT
 SG_ VCU_FS_A_5 : 4|1@0+ (1,0) [0|1] ""  XGW_PT
 SG_ VCU_FS_A_6 : 5|1@0+ (1,0) [0|1] ""  XGW_PT
 SG_ VCU_FS_A_7 : 6|1@0+ (1,0) [0|1] ""  XGW_PT
 SG_ VCU_FS_A_8 : 7|1@0+ (1,0) [0|1] ""  XGW_PT
 SG_ VCU_FS_A_9 : 8|1@0+ (1,0) [0|1] ""  XGW_PT
 SG_ VCU_FS_A_10 : 9|1@0+ (1,0) [0|1] ""  XGW_PT
 SG_ VCU_FS_A_11 : 10|1@0+ (1,0) [0|1] ""  XGW_PT
 SG_ VCU_FS_A_12 : 11|1@0+ (1,0) [0|1] ""  XGW_PT
 SG_ VCU_FS_A_13 : 12|1@0+ (1,0) [0|1] ""  XGW_PT
 SG_ VCU_FS_A_14 : 13|1@0+ (1,0) [0|1] ""  XGW_PT
 SG_ VCU_FS_A_15 : 14|1@0+ (1,0) [0|1] ""  XGW_PT
 SG_ VCU_FS_A_16 : 15|1@0+ (1,0) [0|1] ""  XGW_PT
 SG_ VCU_FS_A_17 : 16|1@0+ (1,0) [0|1] ""  XGW_PT
 SG_ VCU_FS_A_18 : 17|1@0+ (1,0) [0|1] ""  XGW_PT
 SG_ VCU_FS_A_19 : 18|1@0+ (1,0) [0|1] ""  XGW_PT
 SG_ VCU_FS_A_20 : 19|1@0+ (1,0) [0|1] ""  XGW_PT
 SG_ VCU_FS_A_21 : 20|1@0+ (1,0) [0|1] ""  XGW_PT
 SG_ VCU_FS_A_22 : 21|1@0+ (1,0) [0|1] ""  XGW_PT
 SG_ VCU_FS_A_23 : 22|1@0+ (1,0) [0|1] ""  XGW_PT
 SG_ VCU_FS_A_24 : 23|1@0+ (1,0) [0|1] ""  XGW_PT
 SG_ VCU_FS_A_25 : 24|1@0+ (1,0) [0|1] ""  XGW_PT
 SG_ VCU_FS_A_26 : 25|1@0+ (1,0) [0|1] ""  XGW_PT
 SG_ VCU_FS_A_27 : 26|1@0+ (1,0) [0|1] ""  XGW_PT
 SG_ VCU_FS_A_28 : 27|1@0+ (1,0) [0|1] ""  XGW_PT
 SG_ VCU_FS_A_29 : 28|1@0+ (1,0) [0|1] ""  XGW_PT
 SG_ VCU_FS_A_30 : 29|1@0+ (1,0) [0|1] ""  XGW_PT
 SG_ VCU_FS_A_31 : 30|1@0+ (1,0) [0|1] ""  XGW_PT
 SG_ VCU_FS_A_32 : 31|1@0+ (1,0) [0|1] ""  XGW_PT
 SG_ VCU_FS_A_33 : 32|1@0+ (1,0) [0|1] ""  XGW_PT
 SG_ VCU_FS_A_34 : 33|1@0+ (1,0) [0|1] ""  XGW_PT
 SG_ VCU_FS_A_35 : 34|1@0+ (1,0) [0|1] ""  XGW_PT
 SG_ VCU_FS_A_36 : 35|1@0+ (1,0) [0|1] ""  XGW_PT
 SG_ VCU_FS_A_37 : 36|1@0+ (1,0) [0|1] ""  XGW_PT
 SG_ VCU_FS_A_38 : 37|1@0+ (1,0) [0|1] ""  XGW_PT
 SG_ VCU_FS_A_39 : 38|1@0+ (1,0) [0|1] ""  XGW_PT
 SG_ VCU_FS_A_40 : 39|1@0+ (1,0) [0|1] ""  XGW_PT
 SG_ VCU_FS_A_41 : 40|1@0+ (1,0) [0|1] ""  XGW_PT
 SG_ VCU_FS_A_42 : 41|1@0+ (1,0) [0|1] ""  XGW_PT
 SG_ VCU_FS_A_43 : 42|1@0+ (1,0) [0|1] ""  XGW_PT
 SG_ VCU_FS_A_44 : 43|1@0+ (1,0) [0|1] ""  XGW_PT
 SG_ VCU_FS_A_45 : 44|1@0+ (1,0) [0|1] ""  XGW_PT
 SG_ VCU_FS_A_46 : 45|1@0+ (1,0) [0|1] ""  XGW_PT
 SG_ VCU_FS_A_47 : 46|1@0+ (1,0) [0|1] ""  XGW_PT
 SG_ VCU_FS_A_48 : 47|1@0+ (1,0) [0|1] ""  XGW_PT
 SG_ VCU_FS_A_49 : 48|1@0+ (1,0) [0|1] ""  XGW_PT
 SG_ VCU_FS_A_50 : 49|1@0+ (1,0) [0|1] ""  XGW_PT
 SG_ VCU_FS_A_51 : 50|1@0+ (1,0) [0|1] ""  XGW_PT
 SG_ VCU_FS_A_52 : 51|1@0+ (1,0) [0|1] ""  XGW_PT
 SG_ VCU_FS_A_53 : 52|1@0+ (1,0) [0|1] ""  XGW_PT
 SG_ VCU_FS_A_54 : 53|1@0+ (1,0) [0|1] ""  XGW_PT
 SG_ VCU_FS_A_55 : 54|1@0+ (1,0) [0|1] ""  XGW_PT
 SG_ VCU_FS_A_56 : 55|1@0+ (1,0) [0|1] ""  XGW_PT
 SG_ VCU_FS_A_57 : 56|1@0+ (1,0) [0|1] ""  XGW_PT
 SG_ VCU_FS_A_58 : 57|1@0+ (1,0) [0|1] ""  XGW_PT
 SG_ VCU_FS_A_59 : 58|1@0+ (1,0) [0|1] ""  XGW_PT
 SG_ VCU_FS_A_60 : 59|1@0+ (1,0) [0|1] ""  XGW_PT
 SG_ VCU_FS_A_61 : 60|1@0+ (1,0) [0|1] ""  XGW_PT
 SG_ VCU_FS_A_62 : 61|1@0+ (1,0) [0|1] ""  XGW_PT
 SG_ VCU_FS_A_63 : 62|1@0+ (1,0) [0|1] ""  XGW_PT
 SG_ VCU_FS_A_64 : 63|1@0+ (1,0) [0|1] ""  XGW_PT

BO_ 387 VCU_FS_B: 8 VCU_PT
 SG_ VCU_FS_B_1 : 0|1@0+ (1,0) [0|1] ""  XGW_PT
 SG_ VCU_FS_B_2 : 1|1@0+ (1,0) [0|1] ""  XGW_PT
 SG_ VCU_FS_B_3 : 2|1@0+ (1,0) [0|1] ""  XGW_PT
 SG_ VCU_FS_B_4 : 3|1@0+ (1,0) [0|1] ""  XGW_PT
 SG_ VCU_FS_B_5 : 4|1@0+ (1,0) [0|1] ""  XGW_PT
 SG_ VCU_FS_B_6 : 5|1@0+ (1,0) [0|1] ""  XGW_PT
 SG_ VCU_FS_B_7 : 6|1@0+ (1,0) [0|1] ""  XGW_PT
 SG_ VCU_FS_B_8 : 7|1@0+ (1,0) [0|1] ""  XGW_PT
 SG_ VCU_FS_B_9 : 8|1@0+ (1,0) [0|1] ""  XGW_PT
 SG_ VCU_FS_B_10 : 9|1@0+ (1,0) [0|1] ""  XGW_PT
 SG_ VCU_FS_B_11 : 10|1@0+ (1,0) [0|1] ""  XGW_PT
 SG_ VCU_FS_B_12 : 11|1@0+ (1,0) [0|1] ""  XGW_PT
 SG_ VCU_FS_B_13 : 12|1@0+ (1,0) [0|1] ""  XGW_PT
 SG_ VCU_FS_B_14 : 13|1@0+ (1,0) [0|1] ""  XGW_PT
 SG_ VCU_FS_B_15 : 14|1@0+ (1,0) [0|1] ""  XGW_PT
 SG_ VCU_FS_B_16 : 15|1@0+ (1,0) [0|1] ""  XGW_PT
 SG_ VCU_FS_B_17 : 16|1@0+ (1,0) [0|1] ""  XGW_PT
 SG_ VCU_FS_B_18 : 17|1@0+ (1,0) [0|1] ""  XGW_PT
 SG_ VCU_FS_B_19 : 18|1@0+ (1,0) [0|1] ""  XGW_PT
 SG_ VCU_FS_B_20 : 19|1@0+ (1,0) [0|1] ""  XGW_PT
 SG_ VCU_FS_B_21 : 20|1@0+ (1,0) [0|1] ""  XGW_PT
 SG_ VCU_FS_B_22 : 21|1@0+ (1,0) [0|1] ""  XGW_PT
 SG_ VCU_FS_B_23 : 22|1@0+ (1,0) [0|1] ""  XGW_PT
 SG_ VCU_FS_B_24 : 23|1@0+ (1,0) [0|1] ""  XGW_PT
 SG_ VCU_FS_B_25 : 24|1@0+ (1,0) [0|1] ""  XGW_PT
 SG_ VCU_FS_B_26 : 25|1@0+ (1,0) [0|1] ""  XGW_PT
 SG_ VCU_FS_B_27 : 26|1@0+ (1,0) [0|1] ""  XGW_PT
 SG_ VCU_FS_B_28 : 27|1@0+ (1,0) [0|1] ""  XGW_PT
 SG_ VCU_FS_B_29 : 28|1@0+ (1,0) [0|1] ""  XGW_PT
 SG_ VCU_FS_B_30 : 29|1@0+ (1,0) [0|1] ""  XGW_PT
 SG_ VCU_FS_B_31 : 30|1@0+ (1,0) [0|1] ""  XGW_PT
 SG_ VCU_FS_B_32 : 31|1@0+ (1,0) [0|1] ""  XGW_PT
 SG_ VCU_FS_B_33 : 32|1@0+ (1,0) [0|1] ""  XGW_PT
 SG_ VCU_FS_B_34 : 33|1@0+ (1,0) [0|1] ""  XGW_PT
 SG_ VCU_FS_B_35 : 34|1@0+ (1,0) [0|1] ""  XGW_PT
 SG_ VCU_FS_B_36 : 35|1@0+ (1,0) [0|1] ""  XGW_PT
 SG_ VCU_FS_B_37 : 36|1@0+ (1,0) [0|1] ""  XGW_PT
 SG_ VCU_FS_B_38 : 37|1@0+ (1,0) [0|1] ""  XGW_PT
 SG_ VCU_FS_B_39 : 38|1@0+ (1,0) [0|1] ""  XGW_PT
 SG_ VCU_FS_B_40 : 39|1@0+ (1,0) [0|1] ""  XGW_PT
 SG_ VCU_FS_B_41 : 40|1@0+ (1,0) [0|1] ""  XGW_PT
 SG_ VCU_FS_B_42 : 41|1@0+ (1,0) [0|1] ""  XGW_PT
 SG_ VCU_FS_B_43 : 42|1@0+ (1,0) [0|1] ""  XGW_PT
 SG_ VCU_FS_B_44 : 43|1@0+ (1,0) [0|1] ""  XGW_PT
 SG_ VCU_FS_B_45 : 44|1@0+ (1,0) [0|1] ""  XGW_PT
 SG_ VCU_FS_B_46 : 45|1@0+ (1,0) [0|1] ""  XGW_PT
 SG_ VCU_FS_B_47 : 46|1@0+ (1,0) [0|1] ""  XGW_PT
 SG_ VCU_FS_B_48 : 47|1@0+ (1,0) [0|1] ""  XGW_PT
 SG_ VCU_FS_B_49 : 48|1@0+ (1,0) [0|1] ""  XGW_PT
 SG_ VCU_FS_B_50 : 49|1@0+ (1,0) [0|1] ""  XGW_PT
 SG_ VCU_FS_B_51 : 50|1@0+ (1,0) [0|1] ""  XGW_PT
 SG_ VCU_FS_B_52 : 51|1@0+ (1,0) [0|1] ""  XGW_PT
 SG_ VCU_FS_B_53 : 52|1@0+ (1,0) [0|1] ""  XGW_PT
 SG_ VCU_FS_B_54 : 53|1@0+ (1,0) [0|1] ""  XGW_PT
 SG_ VCU_FS_B_55 : 54|1@0+ (1,0) [0|1] ""  XGW_PT
 SG_ VCU_FS_B_56 : 55|1@0+ (1,0) [0|1] ""  XGW_PT
 SG_ VCU_FS_B_57 : 56|1@0+ (1,0) [0|1] ""  XGW_PT
 SG_ VCU_FS_B_58 : 57|1@0+ (1,0) [0|1] ""  XGW_PT
 SG_ VCU_FS_B_59 : 58|1@0+ (1,0) [0|1] ""  XGW_PT
 SG_ VCU_FS_B_60 : 59|1@0+ (1,0) [0|1] ""  XGW_PT
 SG_ VCU_FS_B_61 : 60|1@0+ (1,0) [0|1] ""  XGW_PT
 SG_ VCU_FS_B_62 : 61|1@0+ (1,0) [0|1] ""  XGW_PT
 SG_ VCU_FS_B_63 : 62|1@0+ (1,0) [0|1] ""  XGW_PT
 SG_ VCU_FS_B_64 : 63|1@0+ (1,0) [0|1] ""  XGW_PT

BO_ 389 VCU_FS_C: 8 VCU_PT
 SG_ VCU_FS_C_1 : 0|1@0+ (1,0) [0|1] ""  XGW_PT
 SG_ VCU_FS_C_2 : 1|1@0+ (1,0) [0|1] ""  XGW_PT
 SG_ VCU_FS_C_3 : 2|1@0+ (1,0) [0|1] ""  XGW_PT
 SG_ VCU_FS_C_4 : 3|1@0+ (1,0) [0|1] ""  XGW_PT
 SG_ VCU_FS_C_5 : 4|1@0+ (1,0) [0|1] ""  XGW_PT
 SG_ VCU_FS_C_6 : 5|1@0+ (1,0) [0|1] ""  XGW_PT
 SG_ VCU_FS_C_7 : 6|1@0+ (1,0) [0|1] ""  XGW_PT
 SG_ VCU_FS_C_8 : 7|1@0+ (1,0) [0|1] ""  XGW_PT
 SG_ VCU_FS_C_9 : 8|1@0+ (1,0) [0|1] ""  XGW_PT
 SG_ VCU_FS_C_10 : 9|1@0+ (1,0) [0|1] ""  XGW_PT
 SG_ VCU_FS_C_11 : 10|1@0+ (1,0) [0|1] ""  XGW_PT
 SG_ VCU_FS_C_12 : 11|1@0+ (1,0) [0|1] ""  XGW_PT
 SG_ VCU_FS_C_13 : 12|1@0+ (1,0) [0|1] ""  XGW_PT
 SG_ VCU_FS_C_14 : 13|1@0+ (1,0) [0|1] ""  XGW_PT
 SG_ VCU_FS_C_15 : 14|1@0+ (1,0) [0|1] ""  XGW_PT
 SG_ VCU_FS_C_16 : 15|1@0+ (1,0) [0|1] ""  XGW_PT
 SG_ VCU_FS_C_17 : 16|1@0+ (1,0) [0|1] ""  XGW_PT
 SG_ VCU_FS_C_18 : 17|1@0+ (1,0) [0|1] ""  XGW_PT
 SG_ VCU_FS_C_19 : 18|1@0+ (1,0) [0|1] ""  XGW_PT
 SG_ VCU_FS_C_20 : 19|1@0+ (1,0) [0|1] ""  XGW_PT
 SG_ VCU_FS_C_21 : 20|1@0+ (1,0) [0|1] ""  XGW_PT
 SG_ VCU_FS_C_22 : 21|1@0+ (1,0) [0|1] ""  XGW_PT
 SG_ VCU_FS_C_23 : 22|1@0+ (1,0) [0|1] ""  XGW_PT
 SG_ VCU_FS_C_24 : 23|1@0+ (1,0) [0|1] ""  XGW_PT
 SG_ VCU_FS_C_25 : 24|1@0+ (1,0) [0|1] ""  XGW_PT
 SG_ VCU_FS_C_26 : 25|1@0+ (1,0) [0|1] ""  XGW_PT
 SG_ VCU_FS_C_27 : 26|1@0+ (1,0) [0|1] ""  XGW_PT
 SG_ VCU_FS_C_28 : 27|1@0+ (1,0) [0|1] ""  XGW_PT
 SG_ VCU_FS_C_29 : 28|1@0+ (1,0) [0|1] ""  XGW_PT
 SG_ VCU_FS_C_30 : 29|1@0+ (1,0) [0|1] ""  XGW_PT
 SG_ VCU_FS_C_31 : 30|1@0+ (1,0) [0|1] ""  XGW_PT
 SG_ VCU_FS_C_32 : 31|1@0+ (1,0) [0|1] ""  XGW_PT
 SG_ VCU_FS_C_33 : 32|1@0+ (1,0) [0|1] ""  XGW_PT
 SG_ VCU_FS_C_34 : 33|1@0+ (1,0) [0|1] ""  XGW_PT
 SG_ VCU_FS_C_35 : 34|1@0+ (1,0) [0|1] ""  XGW_PT
 SG_ VCU_FS_C_36 : 35|1@0+ (1,0) [0|1] ""  XGW_PT
 SG_ VCU_FS_C_37 : 36|1@0+ (1,0) [0|1] ""  XGW_PT
 SG_ VCU_FS_C_38 : 37|1@0+ (1,0) [0|1] ""  XGW_PT
 SG_ VCU_FS_C_39 : 38|1@0+ (1,0) [0|1] ""  XGW_PT
 SG_ VCU_FS_C_40 : 39|1@0+ (1,0) [0|1] ""  XGW_PT
 SG_ VCU_FS_C_41 : 40|1@0+ (1,0) [0|1] ""  XGW_PT
 SG_ VCU_FS_C_42 : 41|1@0+ (1,0) [0|1] ""  XGW_PT
 SG_ VCU_FS_C_43 : 42|1@0+ (1,0) [0|1] ""  XGW_PT
 SG_ VCU_FS_C_44 : 43|1@0+ (1,0) [0|1] ""  XGW_PT
 SG_ VCU_FS_C_45 : 44|1@0+ (1,0) [0|1] ""  XGW_PT
 SG_ VCU_FS_C_46 : 45|1@0+ (1,0) [0|1] ""  XGW_PT
 SG_ VCU_FS_C_47 : 46|1@0+ (1,0) [0|1] ""  XGW_PT
 SG_ VCU_FS_C_48 : 47|1@0+ (1,0) [0|1] ""  XGW_PT
 SG_ VCU_FS_C_49 : 48|1@0+ (1,0) [0|1] ""  XGW_PT
 SG_ VCU_FS_C_50 : 49|1@0+ (1,0) [0|1] ""  XGW_PT
 SG_ VCU_FS_C_51 : 50|1@0+ (1,0) [0|1] ""  XGW_PT
 SG_ VCU_FS_C_52 : 51|1@0+ (1,0) [0|1] ""  XGW_PT
 SG_ VCU_FS_C_53 : 52|1@0+ (1,0) [0|1] ""  XGW_PT
 SG_ VCU_FS_C_54 : 53|1@0+ (1,0) [0|1] ""  XGW_PT
 SG_ VCU_FS_C_55 : 54|1@0+ (1,0) [0|1] ""  XGW_PT
 SG_ VCU_FS_C_56 : 55|1@0+ (1,0) [0|1] ""  XGW_PT
 SG_ VCU_FS_C_57 : 56|1@0+ (1,0) [0|1] ""  XGW_PT
 SG_ VCU_FS_C_58 : 57|1@0+ (1,0) [0|1] ""  XGW_PT
 SG_ VCU_FS_C_59 : 58|1@0+ (1,0) [0|1] ""  XGW_PT
 SG_ VCU_FS_C_60 : 59|1@0+ (1,0) [0|1] ""  XGW_PT
 SG_ VCU_FS_C_61 : 60|1@0+ (1,0) [0|1] ""  XGW_PT
 SG_ VCU_FS_C_62 : 61|1@0+ (1,0) [0|1] ""  XGW_PT
 SG_ VCU_FS_C_63 : 62|1@0+ (1,0) [0|1] ""  XGW_PT
 SG_ VCU_FS_C_64 : 63|1@0+ (1,0) [0|1] ""  XGW_PT

BO_ 417 IDB_V_VEH: 5 IDB_PT
 SG_ CHSKM_V_VEH : 7|8@0+ (1,0) [0|255] ""  EDS_F,EDS_R,EPS2,FCAM_PT,GS,POD,RCU_PT,VCU_PT,XGW_PT
 SG_ ALIV_V_VEH : 11|4@0+ (1,0) [0|14] ""  EDS_F,EDS_R,EPS2,FCAM_PT,GS,POD,RCU_PT,VCU_PT,XGW_PT
 SG_ V_VEH_COG : 23|16@0+ (0.015625,0) [0|350] "km/h"  EDS_F,EDS_R,EPS2,GS,POD,RCU_PT,VCU_PT,XGW_PT
 SG_ DVCO_VEH : 35|3@0+ (1,0) [0|7] ""  EDS_F,EDS_R,EPS2,FCAM_PT,GS,POD,RCU_PT,VCU_PT,XGW_PT
 SG_ QU_V_VEH_COG : 39|4@0+ (1,0) [0|15] ""  EDS_F,EDS_R,EPS2,GS,POD,RCU_PT,VCU_PT,XGW_PT

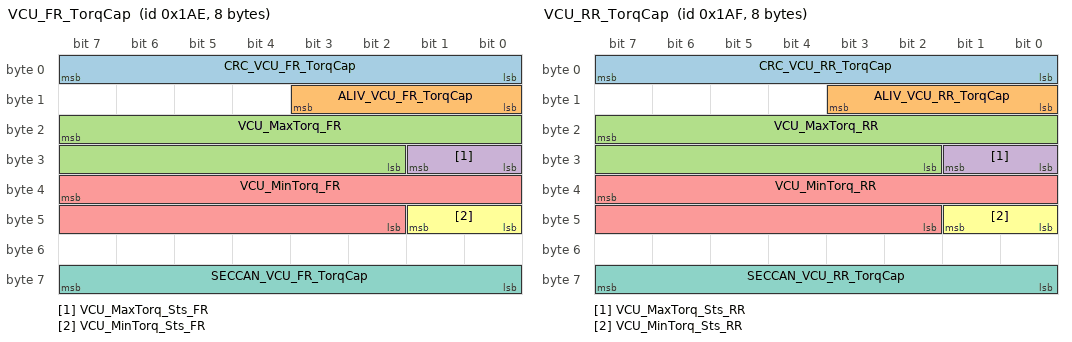
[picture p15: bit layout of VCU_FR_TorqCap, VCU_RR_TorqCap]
BO_ 430 VCU_FR_TorqCap: 8 VCU_PT
 SG_ CRC_VCU_FR_TorqCap : 7|8@0+ (1,0) [0|255] ""  IDB_PT
 SG_ ALIV_VCU_FR_TorqCap : 11|4@0+ (1,0) [0|14] ""  IDB_PT
 SG_ VCU_MaxTorq_FR : 23|14@0- (1,0) [-8000|8000] "Nm"  IDB_PT
 SG_ VCU_MaxTorq_Sts_FR : 25|2@0+ (1,0) [0|3] ""  IDB_PT
 SG_ VCU_MinTorq_FR : 39|14@0- (1,0) [-8000|8000] "Nm"  IDB_PT
 SG_ VCU_MinTorq_Sts_FR : 41|2@0+ (1,0) [0|3] ""  IDB_PT
 SG_ SECCAN_VCU_FR_TorqCap : 63|8@0+ (1,0) [0|255] ""  IDB_PT

BO_ 431 VCU_RR_TorqCap: 8 VCU_PT
 SG_ CRC_VCU_RR_TorqCap : 7|8@0+ (1,0) [0|255] ""  IDB_PT
 SG_ ALIV_VCU_RR_TorqCap : 11|4@0+ (1,0) [0|14] ""  IDB_PT
 SG_ VCU_MaxTorq_RR : 23|14@0- (1,0) [-8000|8000] "Nm"  IDB_PT
 SG_ VCU_MaxTorq_Sts_RR : 25|2@0+ (1,0) [0|3] ""  IDB_PT
 SG_ VCU_MinTorq_RR : 39|14@0- (1,0) [-8000|8000] "Nm"  IDB_PT
 SG_ VCU_MinTorq_Sts_RR : 41|2@0+ (1,0) [0|3] ""  IDB_PT
 SG_ SECCAN_VCU_RR_TorqCap : 63|8@0+ (1,0) [0|255] ""  IDB_PT

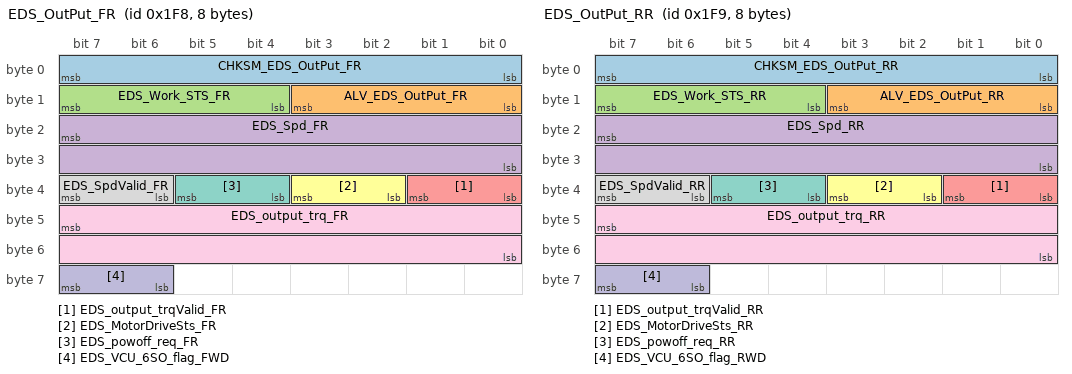
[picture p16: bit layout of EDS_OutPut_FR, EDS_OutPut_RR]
BO_ 504 EDS_OutPut_FR: 8 EDS_F
 SG_ CHKSM_EDS_OutPut_FR : 7|8@0+ (1,0) [0|255] ""  FCAM_PT,GS,IDB_PT,POD,RCU_PT,VCU_PT,XGW_PT
 SG_ ALV_EDS_OutPut_FR : 11|4@0+ (1,0) [0|14] ""  FCAM_PT,GS,IDB_PT,POD,RCU_PT,VCU_PT,XGW_PT
 SG_ EDS_Work_STS_FR : 15|4@0+ (1,0) [0|15] "-"  FCAM_PT,GS,IDB_PT,VCU_PT,XGW_PT
 SG_ EDS_Spd_FR : 23|16@0+ (1,-20000) [-20000|20000] "rpm"  FCAM_PT,GS,IDB_PT,POD,RCU_PT,VCU_PT,XGW_PT
 SG_ EDS_output_trqValid_FR : 33|2@0+ (1,0) [0|1] ""  FCAM_PT,GS,IDB_PT,RCU_PT,VCU_PT,XGW_PT
 SG_ EDS_MotorDriveSts_FR : 35|2@0+ (1,0) [0|3] ""  FCAM_PT,GS,IDB_PT,VCU_PT,XGW_PT
 SG_ EDS_powoff_req_FR : 37|2@0+ (1,0) [0|1] ""  FCAM_PT,GS,IDB_PT,VCU_PT,XGW_PT
 SG_ EDS_SpdValid_FR : 39|2@0+ (1,0) [0|1] ""  FCAM_PT,GS,IDB_PT,VCU_PT,XGW_PT
 SG_ EDS_output_trq_FR : 47|16@0+ (1,-2000) [-2000|2000] "Nm"  FCAM_PT,GS,IDB_PT,RCU_PT,VCU_PT,XGW_PT
 SG_ EDS_VCU_6SO_flag_FWD : 63|2@0+ (1,0) [0|1] ""  FCAM_PT,GS,IDB_PT,VCU_PT,XGW_PT

BO_ 505 EDS_OutPut_RR: 8 EDS_R
 SG_ CHKSM_EDS_OutPut_RR : 7|8@0+ (1,0) [0|255] ""  FCAM_PT,GS,IDB_PT,POD,RCU_PT,VCU_PT,XGW_PT
 SG_ ALV_EDS_OutPut_RR : 11|4@0+ (1,0) [0|14] ""  FCAM_PT,GS,IDB_PT,POD,RCU_PT,VCU_PT,XGW_PT
 SG_ EDS_Work_STS_RR : 15|4@0+ (1,0) [0|15] "-"  FCAM_PT,GS,IDB_PT,VCU_PT,XGW_PT
 SG_ EDS_Spd_RR : 23|16@0+ (1,-20000) [-20000|20000] "rpm"  FCAM_PT,GS,IDB_PT,POD,RCU_PT,VCU_PT,XGW_PT
 SG_ EDS_output_trqValid_RR : 33|2@0+ (1,0) [0|1] ""  FCAM_PT,GS,IDB_PT,VCU_PT,XGW_PT
 SG_ EDS_MotorDriveSts_RR : 35|2@0+ (1,0) [0|3] ""  FCAM_PT,GS,IDB_PT,VCU_PT,XGW_PT
 SG_ EDS_powoff_req_RR : 37|2@0+ (1,0) [0|1] ""  FCAM_PT,GS,IDB_PT,VCU_PT,XGW_PT
 SG_ EDS_SpdValid_RR : 39|2@0+ (1,0) [0|1] ""  FCAM_PT,GS,IDB_PT,VCU_PT,XGW_PT
 SG_ EDS_output_trq_RR : 47|16@0+ (1,-2000) [-2000|2000] "Nm"  FCAM_PT,GS,IDB_PT,RCU_PT,VCU_PT,XGW_PT
 SG_ EDS_VCU_6SO_flag_RWD : 63|2@0+ (1,0) [0|1] "-"  FCAM_PT,GS,IDB_PT,VCU_PT,XGW_PT

BO_ 524 IC_ODO: 8 XGW_PT
 SG_ CHKSM_IC_ODO : 7|8@0+ (1,0) [0|255] ""  EDS_F,EDS_R,IDB_PT,POD,RCU_PT,VCU_PT
 SG_ ALIV_IC_ODO : 11|4@0+ (1,0) [0|14] ""  EDS_F,EDS_R,IDB_PT,POD,RCU_PT,VCU_PT
 SG_ MHU_Odometer_IC : 23|20@0+ (1,0) [0|999999] "km"  EDS_F,EDS_R,IDB_PT,POD,RCU_PT,VCU_PT

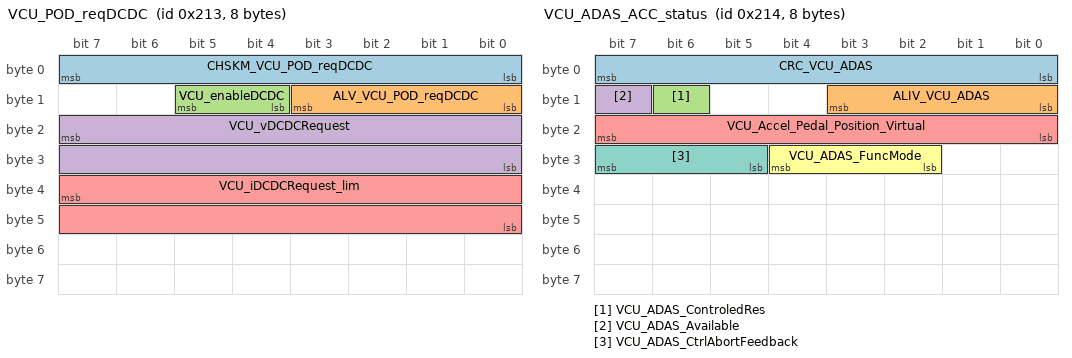
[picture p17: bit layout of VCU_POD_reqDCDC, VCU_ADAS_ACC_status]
BO_ 531 VCU_POD_reqDCDC: 8 VCU_PT
 SG_ CHSKM_VCU_POD_reqDCDC : 7|8@0+ (1,0) [0|255] ""  POD,XGW_PT
 SG_ ALV_VCU_POD_reqDCDC : 11|4@0+ (1,0) [0|14] ""  POD,XGW_PT
 SG_ VCU_enableDCDC : 13|2@0+ (1,0) [0|3] ""  POD,XGW_PT
 SG_ VCU_vDCDCRequest : 23|16@0+ (0.0625,0) [9|16] "V"  POD,XGW_PT
 SG_ VCU_iDCDCRequest_lim : 39|16@0+ (0.0625,0) [0|300] "A"  POD,XGW_PT

BO_ 532 VCU_ADAS_ACC_status: 8 VCU_PT
 SG_ CRC_VCU_ADAS : 7|8@0+ (1,0) [0|255] ""  FCAM_PT,IDB_PT
 SG_ ALIV_VCU_ADAS : 11|4@0+ (1,0) [0|14] ""  FCAM_PT,IDB_PT
 SG_ VCU_ADAS_ControledRes : 14|1@0+ (1,0) [0|1] ""  FCAM_PT,IDB_PT
 SG_ VCU_ADAS_Available : 15|1@0+ (1,0) [0|1] ""  FCAM_PT,IDB_PT
 SG_ VCU_Accel_Pedal_Position_Virtual : 23|8@0+ (0.4,0) [0|100] "%"  FCAM_PT,IDB_PT
 SG_ VCU_ADAS_FuncMode : 28|3@0+ (1,0) [0|7] ""  FCAM_PT,IDB_PT
 SG_ VCU_ADAS_CtrlAbortFeedback : 31|3@0+ (1,0) [0|7] ""  FCAM_PT,IDB_PT

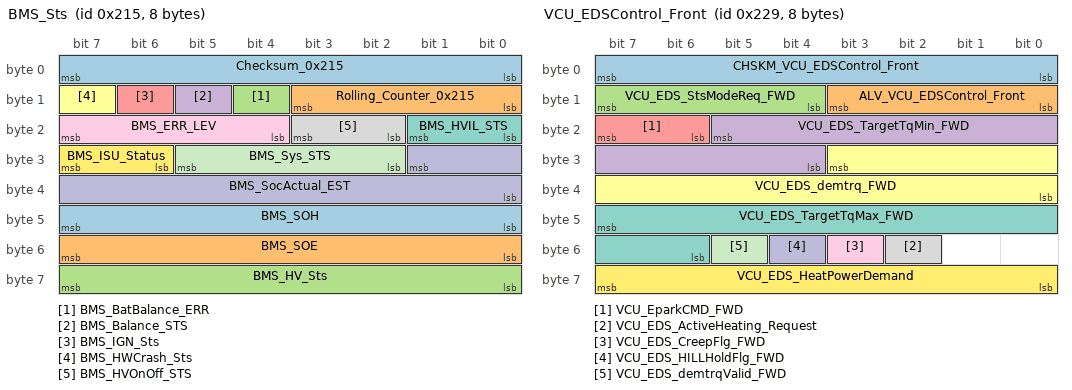
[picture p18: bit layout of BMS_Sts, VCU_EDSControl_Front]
BO_ 533 BMS_Sts: 8 XGW_PT
 SG_ Checksum_0x215 : 7|8@0+ (1,0) [0|255] ""  EDS_F,EDS_R,FCAM_PT,POD,VCU_PT
 SG_ Rolling_Counter_0x215 : 11|4@0+ (1,0) [0|14] ""  EDS_F,EDS_R,FCAM_PT,POD,VCU_PT
 SG_ BMS_BatBalance_ERR : 12|1@0+ (1,0) [0|1] ""  POD,VCU_PT
 SG_ BMS_Balance_STS : 13|1@0+ (1,0) [0|1] ""  POD,VCU_PT
 SG_ BMS_IGN_Sts : 14|1@0+ (1,0) [0|1] ""  FCAM_PT,POD,VCU_PT
 SG_ BMS_HWCrash_Sts : 15|1@0+ (1,0) [0|1] ""  POD,VCU_PT
 SG_ BMS_HVIL_STS : 17|2@0+ (1,0) [0|3] ""  POD,VCU_PT
 SG_ BMS_HVOnOff_STS : 19|2@0+ (1,0) [0|3] ""  POD,VCU_PT
 SG_ BMS_ERR_LEV : 23|4@0+ (1,0) [0|7] "-"  POD,VCU_PT
 SG_ BMS_SocActual_EST : 25|10@0+ (0.1,0) [0|100] "%"  POD,VCU_PT
 SG_ BMS_Sys_STS : 29|4@0+ (1,0) [0|15] ""  EDS_F,EDS_R,POD,VCU_PT
 SG_ BMS_ISU_Status : 31|2@0+ (1,0) [0|3] ""  POD,VCU_PT
 SG_ BMS_SOH : 47|8@0+ (0.5,0) [0|100] "%"  POD,VCU_PT
 SG_ BMS_SOE : 55|8@0+ (0.5,0) [0|100] "%"  POD,VCU_PT
 SG_ BMS_HV_Sts : 63|8@0+ (1,0) [0|255] ""  POD

BO_ 545 CCUR_ClimateSetting: 8 XGW_PT
 SG_ CCUR_Req_AirCondition : 1|2@0+ (1,0) [0|3] ""  VCU_PT
 SG_ SECCAN_CCUR : 63|8@0+ (1,0) [0|255] ""  VCU_PT

BO_ 546 CCUF_ClimateSetting: 8 XGW_PT
 SG_ FRONT_SET_Rear_AirCondition : 1|2@0+ (1,0) [0|3] ""  VCU_PT
 SG_ SECCAN_CCUF : 63|8@0+ (1,0) [0|255] ""  VCU_PT

BO_ 553 VCU_EDSControl_Front: 8 VCU_PT
 SG_ CHSKM_VCU_EDSControl_Front : 7|8@0+ (1,0) [0|255] ""  EDS_F,IDB_PT
 SG_ ALV_VCU_EDSControl_Front : 11|4@0+ (1,0) [0|14] ""  EDS_F,IDB_PT
 SG_ VCU_EDS_StsModeReq_FWD : 15|4@0+ (1,0) [0|15] ""  EDS_F
 SG_ VCU_EDS_TargetTqMin_FWD : 21|10@0+ (1,-500) [-500|0] "Nm"  EDS_F
 SG_ VCU_EparkCMD_FWD : 23|2@0+ (1,0) [0|3] ""  EDS_F
 SG_ VCU_EDS_demtrq_FWD : 27|12@0+ (0.5,-500) [-500|500] "Nm"  EDS_F,IDB_PT
 SG_ VCU_EDS_TargetTqMax_FWD : 47|10@0+ (1,0) [0|500] "Nm"  EDS_F
 SG_ VCU_EDS_ActiveHeating_Request : 50|1@0+ (1,0) [0|1] ""  EDS_F
 SG_ VCU_EDS_CreepFlg_FWD : 51|1@0+ (1,0) [0|1] ""  EDS_F
 SG_ VCU_EDS_HILLHoldFlg_FWD : 52|1@0+ (1,0) [0|1] ""  EDS_F
 SG_ VCU_EDS_demtrqValid_FWD : 53|1@0+ (1,0) [0|1] ""  EDS_F,IDB_PT
 SG_ VCU_EDS_HeatPowerDemand : 63|8@0+ (0.1,0) [0|10] "kW"  EDS_F

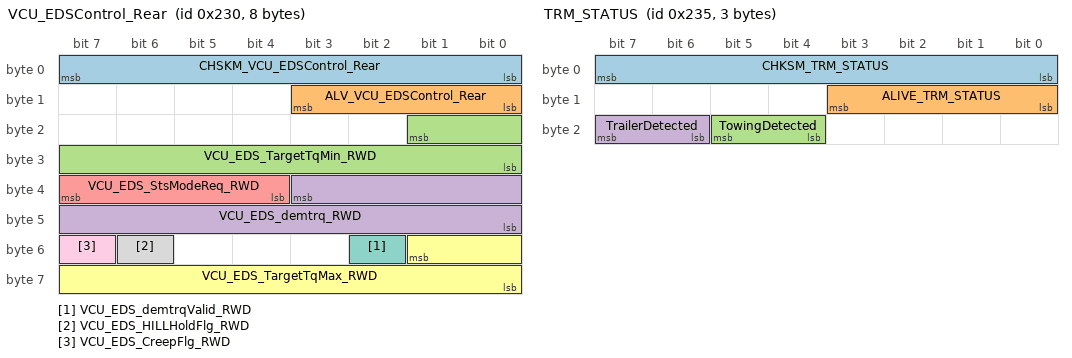
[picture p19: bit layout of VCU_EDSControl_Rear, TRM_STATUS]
BO_ 560 VCU_EDSControl_Rear: 8 VCU_PT
 SG_ CHSKM_VCU_EDSControl_Rear : 7|8@0+ (1,0) [0|255] ""  EDS_R,IDB_PT
 SG_ ALV_VCU_EDSControl_Rear : 11|4@0+ (1,0) [0|14] ""  EDS_R,IDB_PT
 SG_ VCU_EDS_TargetTqMin_RWD : 17|10@0+ (1,-500) [-500|0] "Nm"  EDS_R
 SG_ VCU_EDS_demtrq_RWD : 35|12@0+ (0.5,-500) [-500|500] "Nm"  EDS_R,IDB_PT
 SG_ VCU_EDS_StsModeReq_RWD : 39|4@0+ (1,0) [0|15] ""  EDS_R
 SG_ VCU_EDS_TargetTqMax_RWD : 49|10@0+ (1,0) [0|500] "Nm"  EDS_R
 SG_ VCU_EDS_demtrqValid_RWD : 50|1@0+ (1,0) [0|1] ""  EDS_R,IDB_PT
 SG_ VCU_EDS_HILLHoldFlg_RWD : 54|1@0+ (1,0) [0|1] ""  EDS_R
 SG_ VCU_EDS_CreepFlg_RWD : 55|1@0+ (1,0) [0|1] ""  EDS_R

BO_ 565 TRM_STATUS: 3 XGW_PT
 SG_ CHKSM_TRM_STATUS : 7|8@0+ (1,0) [0|255] ""  IDB_PT,VCU_PT
 SG_ ALIVE_TRM_STATUS : 11|4@0+ (1,0) [0|14] ""  IDB_PT,VCU_PT
 SG_ TowingDetected : 21|2@0+ (1,0) [0|3] ""  VCU_PT
 SG_ TrailerDetected : 23|2@0+ (1,0) [0|3] ""  IDB_PT,VCU_PT

CM_ "This dbc file for FRS build";
CM_ BU_ BMS_Tester "BMS Test Message";
CM_ BU_ EDS_F "Electric Drive System Front";
CM_ BU_ EDS_R "Electric Drive System Rear";
CM_ BU_ EPS2 "Redundant Electric power steering";
CM_ BU_ FCAM_PT "Front Camera ADAS Module";
CM_ BU_ GS "Gear Shifter";
CM_ BU_ IDB_PT "Intelligent Distribution Brake";
CM_ BU_ POD "Power Distribution Unit + OBC + DCDC";
CM_ BU_ RCU_PT "Redudant Control Unit";
CM_ BU_ VCU_PT "Vehicle Control Unit";
CM_ BU_ XGW_PT "Gateway";
CM_ BO_ 133 "ACM Message for crash details";
CM_ BO_ 147 "Mileage information ";
CM_ BO_ 148 "VCU pump status";
CM_ BO_ 149 "EPBi Function";
CM_ BO_ 150 "IDB select mode from MHU";
CM_ BO_ 217 "High Voltage Drive System Status";
CM_ BO_ 218 "Regeneration Capability";
CM_ BO_ 219 "Actual regen torque";
CM_ BO_ 225 "IDB_VCU_ACC_TorqueRequest";
CM_ BO_ 256 "MHU_Vehicle_Info";
CM_ BO_ 260 "Actual name BCM_LVBAT_COM_INFO";
CM_ BO_ 261 "BCM door flap state";
CM_ BO_ 264 "GS Drive request";
CM_ BO_ 265 "BCM switches status";
CM_ BO_ 266 "Low Voltage Battery";
CM_ BO_ 274 "Clamp status for BEV vehicle";
CM_ BO_ 278  "BCM_LVBAT_COM_INFO2";
CM_ BO_ 290 "CCU maximum request";
CM_ BO_ 291 "VCU ACCharging Info.";
CM_ BO_ 292 "VCU DCCharging Info.";
CM_ BO_ 303 "BCM Terminal for vehicle";
CM_ BO_ 310 "MHU_PnC_trigger";
CM_ BO_ 311 "VCU_PnC_Error";
CM_ BO_ 317 "VCU_PnC_Error";
CM_ BO_ 338 "EDS_FS_FR";
CM_ BO_ 339 "EDS_FS_FR";
CM_ BO_ 357 "Charging connection ";
CM_ BO_ 359 "VCU_TWV1_FRM";
CM_ BO_ 372 "BMS CurMeas";
CM_ BO_ 374 "BMS high voltage measurement";
CM_ BO_ 376 "YSS_LongAcc";
CM_ BO_ 377 "YSS_LateralAcc";
CM_ BO_ 381 "YSS_YawRate";
CM_ BO_ 384 "Steering angle sensor 2 in PT-CAN";
CM_ BO_ 385 "VCU_Debug";
CM_ BO_ 417 "Vehicle speed";
CM_ BO_ 430 "VCU Front torque Capability";
CM_ BO_ 431 "VCU Rear torque Capability";
CM_ BO_ 504 "MCU OutPut FR";
CM_ BO_ 505 "MCU OutPut RR";
CM_ BO_ 524 "IC ODO";
CM_ BO_ 531 "VCU Command";
CM_ BO_ 532 "VCU_ADAS_ACC_status";
CM_ BO_ 533 "BMS status";
CM_ BO_ 545 "CCUR_ClimateSetting";
CM_ BO_ 546 "CCUF_ClimateSetting";
CM_ BO_ 553 "VCU MCU Control Front";
CM_ BO_ 560 "VCU MCUControl Rear";
CM_ BO_ 565 "Trailer Status";
CM_ SG_ 133 CHKSM_CRASH_Sts "Checksum";
CM_ SG_ 133 ALV_CRASH_Sts "Alive Counter";
CM_ SG_ 133 ACM_Crash_Sts "Crash status";
CM_ SG_ 133 ACM_Airbag_Deployment_Status "Signal to indicate if airbag pretensioner pyrofuse is deployed";
CM_ SG_ 133 ACM_Crash_Intensity "Indicate crash intensity level";
CM_ SG_ 133 ACM_Front_Crash "Output information for direction of crash";
CM_ SG_ 133 ACM_DriverSide_Crash "Output information for direction of crash";
CM_ SG_ 133 ACM_PassSide_Crash "Output information for direction of crash";
CM_ SG_ 133 ACM_Rear_Crash "Output information for direction of crash";
CM_ SG_ 133 ACM_Rollover_Crash "Output information for direction of crash";
CM_ SG_ 147 CHKSM_MILEAGE "Checksum";
CM_ SG_ 147 ALIVE_MILEAGE "Alive counter";
CM_ SG_ 147 Mileage "Mileage";
CM_ SG_ 148 VCU_Pump_3_Stt "Cooling pump 3 status (HV Battery loop)
";
CM_ SG_ 148 VCU_Pump_3_Flowrate "Cooling pump 3 flow rate  (HV Battery loop)
";
CM_ SG_ 149 CHKSM_IDB_FUNCTION "Checksum";
CM_ SG_ 149 ALV_IDB_FUNCTION "Alive counter";
CM_ SG_ 149 STAT_ABS "ABS Status";
CM_ SG_ 149 ABS_Active "ABS function active.";
CM_ SG_ 149 AYC_Active "Active yaw control";
CM_ SG_ 149 ASR_Active "ASR Traction Control active";
CM_ SG_ 149 STAT_DSC "Dynamic Stability Control status";
CM_ SG_ 149 DSC_Active "DSC function active.";
CM_ SG_ 149 HBA_ActiveSignal "HBA active signal";
CM_ SG_ 149 ARM_ActiveSignal "ARM active signal";
CM_ SG_ 149 STAT_AutoHazardBlinking "Indicates IDB/ABS emergency brake";
CM_ SG_ 149 MSR_Active "engine drag torque control active";
CM_ SG_ 149 HSA_ActiveSignal "HSA active signal, It will set to 0x1: Active when HHC activated, it will set back to 0x0:Inactive when HHC not active or deactivated.";
CM_ SG_ 149 EPBi_ECD_ActiveSignal "this signal indicates EPBi active or not after EPBi receives ECD request";
CM_ SG_ 149 TSM_Active "TSM Active";
CM_ SG_ 149 HAS_Available "HAS Hill Hold Available";
CM_ SG_ 149 STAT_EBD "EBD Electronic Brake Distribution Status";
CM_ SG_ 149 EBD_Active "EBD function active.";
CM_ SG_ 149 ST_BRG_MSA "Prediction of whether the vehicle is held by the DSC at v = 0 km/h. (Receiver: EMS)";
CM_ SG_ 150 CHKSM_MHU_IDB_Mode_Select "Checksum";
CM_ SG_ 150 ALV_MHU_IDB_Mode_Select "Alive counter";
CM_ SG_ 150 MHU_IDB_Mode_Select_Signal "Select mode for IDB";
CM_ SG_ 217 CRC_VCU_HV_DrvSys_status "Checksum";
CM_ SG_ 217 ALIV_VCU_HV_DrvSys_status "Alive counter";
CM_ SG_ 217 VCU_HVsystem_status "High Voltage system status";
CM_ SG_ 217 VCU_ACPD_Percent "The signal contains the actual angle of the acceleration pedal100% acceleration pedal position shall only provided in case of kick down.Without kickdown the maximum value shall be 99.";
CM_ SG_ 217 VCU_ACPD_Percent_Valid "Qualifier for corresponding signal.  In value table not defined values are reserved";
CM_ SG_ 217 VCU_ACTGear "actual gear,Provide gear shift signal";
CM_ SG_ 217 VCU_ACTGearValid "Indicate the current gear position
";
CM_ SG_ 217 VCU_ACT_DriveMode "Vehicle drive mode";
CM_ SG_ 217 VCU_ACT_DriveMode_Valid "Vehicle drive mode status";
CM_ SG_ 217 VCU_HV_DRVsystem_status "Status of driving system ( Highvoltage )";
CM_ SG_ 217 VCU_Recu_BrakeLight_ON_Req "VCU request brake light ON when regen";
CM_ SG_ 218 CRC_VCU_IDB_Regen_Cap "Checksum";
CM_ SG_ 218 ALIV_VCU_IDB_Regen_Cap "Alive counter";
CM_ SG_ 218 VCU_RecuBrakeTorqCap_FR "The signal shows the available torque of the electrical machine, which the power train can make available to create an equivalent braking torque.(FR)";
CM_ SG_ 218 VCU_RecuBrkTorqCap_Sts_FR "Indicate status of Regen Torque Capability signal (FR)";
CM_ SG_ 218 VCU_RecuBrakeTorqCap_RR "The signal shows the available torque of the electrical machine, which the power train can make available to create an equivalent braking torque.(RWD)";
CM_ SG_ 218 VCU_RecuBrkTorqCap_Sts_RR "Indicate status of Regen Torque Capability signal (RR)";
CM_ SG_ 218 VCU_IDB_DrvIntdTorqFr "Driver intended Torque";
CM_ SG_ 219 CRC_VCU_IDB_Regen_Act "Checksum";
CM_ SG_ 219 ALIV_VCU_IDB_Regen_Act "Alive counter";
CM_ SG_ 219 VCU_BrkRegenTorqueAct_FR "Actual Braking Regenerative torque performed by E-motor FWD";
CM_ SG_ 219 VCU_BrkRegenTorqueActValid_FR "Qualifier of Actual Braking Regenerative torque status performed by E-motor FWD";
CM_ SG_ 219 VCU_BrkRegenTorqueAct_RR "Actual Braking Regenerative torque performed by E-motor RWD";
CM_ SG_ 219 VCU_BrkRegenTorqueActValid_RR "Qualifier of Actual Braking Regenerative torque status performed by E-motor RWD";
CM_ SG_ 219 VCU_IDB_DrvIntdTorqRe "Driver intended torque";
CM_ SG_ 225 CRC_IDB_VCU_ACC_TorqueRequest "Checksum";
CM_ SG_ 225 Alive_IDB_VCU_ACC_TorqueRequest "Alive Counter";
CM_ SG_ 225 IDB_ACC_WheelTrq_Request "IDB ACC Wheel Torque Request Flag";
CM_ SG_ 225 IDB_ACC_TargetWheel_Torque "IDB ACC Control Target Wheel Torque Request Signal";
CM_ SG_ 225 SECCAN_IDB_VCU_ACC_Torq "Seed generated from Secure CAN algorithm";
CM_ SG_ 226 CRC_IDB_VCU_APA_TorqueRequest "Checksum";
CM_ SG_ 226 Alive_IDB_VCU_APA_TorqueRequest "Alive Counter";
CM_ SG_ 226 IDB_APA_WheelTrq_Request "IDB to VCU Handshake Request";
CM_ SG_ 226 IDB_APA_TargetWheel_Torque "IDB request VCU wheel torque value";
CM_ SG_ 226 SECCAN_IDB_VCU_APA_Torque "Seed generated from Secure CAN algorithm";
CM_ SG_ 256 CHKSM_MHU_VEH_INFO "Checksum";
CM_ SG_ 256 ALV_MHU_VEH_INFO "Alive Counter";
CM_ SG_ 256 MHU_UserProfileId "User profile ID, support 10 user profiles in maxinum, 0xF is invalid signal";
CM_ SG_ 256 MHU_Connectivity_Status "Internet Connection Connectivity Status";
CM_ SG_ 260 CHKSM_LV_BATT_CHARG "Checksum
";
CM_ SG_ 260 ALIV_LV_BATT_CHARG "Alive counter
";
CM_ SG_ 260 SOH_SUL "Actual name LV_SOH (State of Health)";
CM_ SG_ 260 SOH_SUL_STATE "Actual name LV_SOH_Sts (SOH Status)
";
CM_ SG_ 260 SOC_STATE "SOC Status";
CM_ SG_ 260 Resp_Error "Resp_Error";
CM_ SG_ 260 FLAG_INCONSTENCY "Battery inconsistency flag
";
CM_ SG_ 260 EBS_error "EBS error
";
CM_ SG_ 260 FLAG_DISCONNECT "Battery disconnection flag

";
CM_ SG_ 260 BCM_LV_Batt_Charging_Req "BCM_LV_REQ";
CM_ SG_ 260 LV_TargetVoltage "LV BMS sends out expected target voltage";
CM_ SG_ 260 LV_TargetCurrent "Target battery current from LV BMS";
CM_ SG_ 261 CHKSM_BCM_STAT_DOOR_FLAP "Checksum";
CM_ SG_ 261 ALIVE_BCM_STAT_DOOR_FLAP "Alive counter";
CM_ SG_ 261 BCM_STAT_TrunkAjar "Trunk Ajar Door Status";
CM_ SG_ 261 BCM_STAT_DoorAjarFL "Ajar Door Front Left Status";
CM_ SG_ 261 BCM_STAT_DoorAjarFR "Ajar Door Front Right Status";
CM_ SG_ 261 BCM_STAT_DoorAjarRL "Ajar Door Rear Left Status";
CM_ SG_ 261 BCM_STAT_DoorAjarRR "Ajar Door Rear Right Status";
CM_ SG_ 261 BCM_STAT_BonnetAjar "Ajar Bonnet Status";
CM_ SG_ 264 CHKSM_GS_DriveReq "Checksum";
CM_ SG_ 264 ALIVE_GS_DriveReq "Alive counter";
CM_ SG_ 264 GS_TargetGearReq "Target gear request";
CM_ SG_ 265 CHKSM_BCM_SWITCH_Sts "Checksum";
CM_ SG_ 265 ALV_BCM_SWITCH_Sts "Alive counter";
CM_ SG_ 265 BCM_STAT_BrakeSwitch "Brake pedal switch BCM pressed (only for brake light)";
CM_ SG_ 265 BCM_STAT_HazardWarn "Hazard Warning switch activation";
CM_ SG_ 265 BCM_STAT_FuelPumpCutOFF "Status Fuel Pump cut off by crash";
CM_ SG_ 265 BCM_FollowMeHomeActive "BCM_FollowMeHomeActive";
CM_ SG_ 265 BCM_STAT_Horn "Status switch horn";
CM_ SG_ 265 BCM_STAT_Autowiping "Status for Autowiping ON /OFF";
CM_ SG_ 265 BCM_TurnIndicator "BCM_TurnIndicator";
CM_ SG_ 265 BCM_WelcomeActive "BCM Welcome Active";
CM_ SG_ 265 BCM_HighBeam "BCM_High beam ";
CM_ SG_ 265 ACM_Seat_Belt_Status_3rd_Row_Pas "Seatbelt status for seatbelt reminder function for 3rd Row Pass";
CM_ SG_ 265 ACM_Seat_Belt_Status_3rd_Row_Dri "Seatbelt status for seatbelt reminder function for 3rd Row Driver";
CM_ SG_ 266 CHKSM_BCM_VOLTAGE "Checksum";
CM_ SG_ 266 ALIVE_BCM_VOLTAGE "Alive counter";
CM_ SG_ 266 UBatt "Battery Voltage";
CM_ SG_ 266 LV_Batt_Temp "Low voltage Battery Temperature";
CM_ SG_ 266 LV_SOC "State Of charge for Low Voltage Battery";
CM_ SG_ 266 LV_Batt_Current "Current of Low Voltage Battery";
CM_ SG_ 266 LV_BatteryType "LV Battery Type (Lead Acid or Lithium)";
CM_ SG_ 274 CHKSM_BCM_CLAMP_STAT "Checksum";
CM_ SG_ 274 ALIVE_BCM_CLAMP_STAT "Alive counter";
CM_ SG_ 274 RemoteFunctionState "0x1(remote function) will be sent after PreRemoteStart=0x1 first time in ignition OFF state, and this signal will be kept 0x1 until SESAM exit remote state.";
CM_ SG_ 274 STAT_BLS "Signal represent plausibility of both HW Inputs for brake light switch.";
CM_ SG_ 274 STAT_CL_50_L "Logical clamp status";
CM_ SG_ 274 Clamp50AdviceRemoteStart "Engine Start announcement (Clamp 50) for remote start";
CM_ SG_ 274 Clamp50AdviceESS "Engine Start announcement (Clamp 50) for ESS";
CM_ SG_ 274 STAT_CL_R_L "Logical clamp status";
CM_ SG_ 274 STAT_CL_15_1_L "Logical clamp status";
CM_ SG_ 274 STAT_CL_15_1_DME_L "Logical clamp status";
CM_ SG_ 274 FobId "Information of FOB ID.";
CM_ SG_ 274 STAT_Terminal "Represent the status of physical terminal";
CM_ SG_ 274 STAT_CL30_C_BEV "Logical clamp status";
CM_ SG_ 274 BCM_Clamp_Transport "BCM_Clamp_Transport";
CM_ SG_ 278 CHKSM_LVBAT_INFO2 "Checksum";
CM_ SG_ 278 ALIV_LVBAT_INFO2 "Alive counter";
CM_ SG_ 278 LV_MaxAllowDischargeCurrent "Maximum discharge current that is allowed by LV BMS (Li-ion LV battery)";
CM_ SG_ 278 LV_WakeupReason "LV Wakeup Reason";
CM_ SG_ 278 LV_MaxAllowChargeCurrent "Maximum charge current that is allowed by LV BMS (Li-ion LV battery)";
CM_ SG_ 278 LV_SOE "State of Energy  (Li-ion LV battery)";
CM_ SG_ 290 CHKSM_CCU_REQUEST "Checksum";
CM_ SG_ 290 ALV_CCU_REQUEST "Alive Counter";
CM_ SG_ 290 CCU_REQ_MaxCool "Request for maximal cool down minimum level temp";
CM_ SG_ 290 CCU_REQ_MaxHeat "Request for maximal heat up maximum level temp";
CM_ SG_ 290 CCU_REQ_ESSMotorControl "This signal provides the status, to prevent the motorstop, or to request the motorstart.Invalid value = 7";
CM_ SG_ 290 CCU_AC_PWM "Compressor pwm value. 65h to 7Fh are invalid values. ";
CM_ SG_ 291 CHKSM_ACChargingInfo "Checksum";
CM_ SG_ 291 ALIVE_ACChargingInfo "Alive counter";
CM_ SG_ 291 ACCharging_MaxChargingPower "Max  Power of AC Charging gun.";
CM_ SG_ 291 CurrentACChargingPower "Nominal power from AC charnge gun";
CM_ SG_ 291 ACCharging_MaxCurrent "Max current of AC Charging gun";
CM_ SG_ 292 CHKSM_DCChargingInfo "Checksum";
CM_ SG_ 292 ALIVE_DCChargingInfo "Alive counter";
CM_ SG_ 292 DCCharging_MaxChargingPower "Max power from the DC charging gun";
CM_ SG_ 292 CurrentDCChargingPower "Nominal power output from DC charge gun";
CM_ SG_ 292 DCCharging_MaxCurrent "Max current from the DC charging gun";
CM_ SG_ 303 CHKSM_BCM_TERMINAL "Checksum";
CM_ SG_ 303 ALV_BCM_TERMINAL "Alive counter";
CM_ SG_ 303 STAT_AlcoholEngineStatus "AlcoholEngineStatus ON/OFF ";
CM_ SG_ 303 STAT_AlcoholIgnStatus "AlcoholIgnStatus ON/OFF ";
CM_ SG_ 303 ST_KL "Clamp status";
CM_ SG_ 303 ST_KL_KEY_VLD "Key valid";
CM_ SG_ 303 ST_STCD_PENG "Plausibility signal for starter release";
CM_ SG_ 303 ST_SSB "Status of Start Stop Button";
CM_ SG_ 303 RWDT_BLS "Raw data Brake light switch";
CM_ SG_ 303 RQ_DRVG_RDI "Engine start advice (will be send out before the engine start)";
CM_ SG_ 303 CTR_ENG_STOP "This signal allows the engine to be switched off without removing the ignition (KL15). ";
CM_ SG_ 303 ST_VEH_CON "The signal is formed from the current klemme state, the engine running status and the vehicle movement. It also shows whether the vehicle is in washline mode. Attention: This signal only evaluates the condition of the internal combustion engine.";
CM_ SG_ 310 PnC_activation "To activate and deactivate the PnC from MHU";
CM_ SG_ 310 PnCandEIM_Switch "To switch between EIM and PNC from MHU";
CM_ SG_ 310 PnC_trigger1 "Reserved trigger 1";
CM_ SG_ 310 PnC_trigger2 "Reserved trigger 2";
CM_ SG_ 310 PnC_Cert_Del "To delete the stored certificates in the VCU ";
CM_ SG_ 310 PnC_feature_enable "To enable and disable the feature";
CM_ SG_ 311 OK_OldSessionJoined "To inform about the old session when Session request is successful and same session id as used in the request message is contained in the response message";
CM_ SG_ 311 OK_NewSessionEstablished "To inform about the new session when Session request is successful and different session id is contained in the response message than the session id in request message";
CM_ SG_ 311 OK_CertificateExpireSoon "Your contract certificate is about to expire, you can extend your contract on the PnC Menu.";
CM_ SG_ 311 PnC_OK "PnC connection successful ";
CM_ SG_ 311 Failed_CertificateNoAllowAtEVSE "To activate and deactivate the PnC from MHU.";
CM_ SG_ 311 Failed_ContactorError "To activate and deactivate the PnC from MHU";
CM_ SG_ 311 Failed_NoChargeServiceSelectd "To inform about requested service with service ID value equal to one which was not in PaymentService SelectionReq and was offered by SECC";
CM_ SG_ 311 PnC_Failed "PnC connection unsuccessful. Please try again.";
CM_ SG_ 311 Failed_ServiceIDInvalid "if service id is not part of the offered service list during service directory";
CM_ SG_ 311 Falied_UnknownSession "To describe the Session ID is not equal to Session ID stored for the currently active V2G comm session ";
CM_ SG_ 311 Failed_SignatureError "The security element validation failure in message header";
CM_ SG_ 311 Failed_SequenceError "To inform that the SECC has received an unexpected request message";
CM_ SG_ 311 Failed_CertChainError "To inform that the ContractSignatureCertChain contained in the CertificateInstallation request message is not Valid";
CM_ SG_ 311 Failed_NoCertificateAvailable "To inform that new certificate can not be retrieved from secondary actor within V2G_SECC_Msg_Performance_Time according to table 109 of ISO standard";
CM_ SG_ 311 Failed_CertificateRevoked "To activate and deactivate the PnC from MHU";
CM_ SG_ 311 Failed_PaymentSelectionInvalid "If the selected payment option contained in the PaymentServiceSelectionRequest message wa not part of the offered paymentOption list ";
CM_ SG_ 311 Failed_WrongChargeParameter "To inform that the content of attribute 'EVChargeParameter in the ChargeParameterDiscoveryReq message is not valid, e.g. wrong parameter set is provided, one or multiple parameters cannot be interpreted. ";
CM_ SG_ 311 Failed_WrongEnergyTranferMode "To inform that the content of";
CM_ SG_ 311 Failed_ChallengeInvalid "To inform that the challenge response contained in the AuthorizationReq message in attribute GenChallenge";
CM_ SG_ 311 Failed_ContractCancelled "To inform that EMAID provided by EVCC during certificateUpdateReq is not accepted by secondary actor.";
CM_ SG_ 311 Failed_MeteringSignatureNotValid "To inform when the SECC is not able to validate the signature, or the contained meter reading does not fit to the provided meter reading during 'ChargingStatusRes' and the SECC requires that the signature is valid";
CM_ SG_ 311 Failed_PowerDeliverNotApplied "To inform when the EVSE is not able to deliver energy";
CM_ SG_ 311 Failed_TarrifSelectionInvalid "To inform that the the content of attribute 'ChargingProfile' in the PowerDeliveryReq message contains a SAtuplelD which was not contained in the 'SASchedules' attribute provided in 'ChargeParameterDiscoveryReS";
CM_ SG_ 311 Failed_ChargingProfileInvalid "To inform that the content of attribute 'ChargingProfile' in the PowerDeliveryReq message violates a power limitation provided in 'ChargeParameterDiscoveryRes'";
CM_ SG_ 311 Error_message_4 "Reserved message 4";
CM_ SG_ 311 Error_message_3 "Reserved message 3";
CM_ SG_ 311 Error_message_1 "Reserved message 1 ";
CM_ SG_ 311 Error_message_2 "Reserved message 2";
CM_ SG_ 311 PnC_ChargeSessionEnded "To inform the User about charging session ended";
CM_ SG_ 311 PnC_Status "To inform that PnC is enabled or disabled to user";
CM_ SG_ 311 PnC_Contract_Status "Reserved message 6";
CM_ SG_ 311 Error_message_5 "Reserved message 5";
CM_ SG_ 316 CRC_FCAM_VCU_ACC_Status "Checksum";
CM_ SG_ 316 Alive_FCAM_VCU_ACC_Status "Alive counter";
CM_ SG_ 316 FCAM_ACC_Mode_VCU "ACC control state for VCU";
CM_ SG_ 316 SECCAN_FCAM_VCU_ACC_Status "Seed generated from Secure CAN algorithm";
CM_ SG_ 317 SessionPaymentType "To inform the MHU whether the PnC or EIM is active";
CM_ SG_ 338 CHSKM_EDS_FS_FR "Checksum";
CM_ SG_ 338 ALV_EDS_FS_FR "Alive Counter";
CM_ SG_ 338 EDS_FuSa_error_FR "EDS safety path error";
CM_ SG_ 338 EDS_shutoffpath_error_FR "EDS Shut off path error";
CM_ SG_ 338 EDS_EDSDisChgFault_FWD "EDS Active Discharge error";
CM_ SG_ 339 CHSKM_EDS_FS_RR "Checksum";
CM_ SG_ 339 ALV_EDS_FS_RR "Alive Counter";
CM_ SG_ 339 EDS_FuSa_error_RR "EDS safety path error";
CM_ SG_ 339 EDS_shutoffpath_error_RR "EDS Shut off path error";
CM_ SG_ 339 EDS_EDSDisChgFault_RWD "EDS Active Discharge error";
CM_ SG_ 357 CHSKM_VCU_ChargingConnection "Checksum";
CM_ SG_ 357 ALV_VCU_ChargingConnection "Alive Counter";
CM_ SG_ 357 VCU_AcChgGunIn "Slow Charge Gun Insert Status ";
CM_ SG_ 357 VCU_DCChgGunIn "Connection status of DC Fast charging Gun";
CM_ SG_ 357 VCU_CPValue "Charging port duty Cycle value (PWM)";
CM_ SG_ 357 VCU_ACChargingVoltage "The Power of this AC charging connection in KW";
CM_ SG_ 357 VCU_MinCurrentOfACCharging "Minium Charging current of this AC Charging connection";
CM_ SG_ 357 VCU_MaxCurrentOfACCharging "Maximum Charging current of AC Charging";
CM_ SG_ 359 TWV1_N_Position "TWV1_N_Position";
CM_ SG_ 359 TWV1_St_Feedback "TWV1_St_Feedback";
CM_ SG_ 359 TWV1_Frm_Error "TWV1_Frm_Error";
CM_ SG_ 372 CHSKM_BMS_CurMeas "Checksum";
CM_ SG_ 372 ALV_BMS_CurMeas "Alive Counter";
CM_ SG_ 372 BMS_PackCur_MEAS "Battery Pack Total Current";
CM_ SG_ 374 Checksum_0x176 "Checksum";
CM_ SG_ 374 Rolling_Counter_0x176 "Rolling Counter";
CM_ SG_ 374 BMS_HVPackVol_MEAS "Pack Voltage";
CM_ SG_ 374 BMS_HVLinkVol_MEAS "Link Voltage";
CM_ SG_ 376 CHKSM_YSS_LongAcc "Checksum";
CM_ SG_ 376 ALV_YSS_LongAcc "Alive Counter";
CM_ SG_ 376 YSS_LONG_ACCUNFILTERED_QUAL "This signal contains the physical value of the Longitudinal acceleration with 0.002m/s2 LSB.";
CM_ SG_ 376 YSS_LONG_ACC_UNFILTERED "This signal contains the physical value of the Longitudinal acceleration with 0.002m/s2 LSB.";
CM_ SG_ 376 YSS_LONG_ACC_QUAL "This signal contains the qualifier of the Longitudinal acceleration.";
CM_ SG_ 376 YSS_LONG_ACC "This signal contains the physical value of the Longitudinal acceleration with 0.002m/s2 LSB.";
CM_ SG_ 377 CHKSM_YSS_LateralAcc "Checksum";
CM_ SG_ 377 ALV_YSS_LateralAcc "Alive Counter";
CM_ SG_ 377 YSS_LAT_ACCUNFILTERED_QUAL "This signal contains the qualifier of the Lateral acceleration.";
CM_ SG_ 377 YSS_LAT_ACC_UNFILTERED "This signal contains the physical value of the Lateral acceleration with 0.002m/s2 LSB.";
CM_ SG_ 377 YSS_LAT_ACC_QUAL "This signal contains the qualifier of the Lateral acceleration.";
CM_ SG_ 377 YSS_LAT_ACC "This signal contains the physical value of the Lateral acceleration with 0.002m/s2 LSB.";
CM_ SG_ 381 CHKSM_YSS_YawRate "Checksum";
CM_ SG_ 381 ALV_YSS_YawRate "Alive Counter";
CM_ SG_ 381 YSS_YAW_RATEUNFILTERED_QUAL "This signal contains the qualifier of the Yaw rate. ";
CM_ SG_ 381 YSS_YAW_RATE_UNFILTERED "This signal contains the physical value of the Yaw rate with 0.005°/s LSB.";
CM_ SG_ 381 YSS_YAW_RATE_QUAL "This signal contains the qualifier of the Yaw rate. ";
CM_ SG_ 381 YSS_SC_STATUS "This signal contains the state information for the SC. Each state has different priority, therefore the SC can have only one state at the same time.";
CM_ SG_ 381 YSS_YAW_RATE "This signal contains the physical value of the Yaw rate with 0.005°/s LSB. Table 2 contains some hexadecimal values with special meaning (e.g. initialization). The Yaw rate signal can have values from -163.830°/s (0x0000) to +163.830°/s (0xFFFC). The 0°/s value is assigned to (0x7FFE).";
CM_ SG_ 381 YSS_TEMPERATURE "This signal contains the physical value of the Temperature with 1°C LSB. Table 2 contains hexadecimal values with special meaning (e.g. initialization). The TEMPERATURE signal has no separate qualifier signal.";
CM_ SG_ 384 CHKSM_EPS2_SAS_Sensor "Checksum";
CM_ SG_ 384 ALV_EPS2_SAS_Sensor "Alive Counter";
CM_ SG_ 384 EPS2_SAS_SASStsSnsr "The flag of  SAS status Punch Steering angle status";
CM_ SG_ 384 EPS2_SAS_SteerWhlRotSpd "The current rotation speed of the steering wheel.";
CM_ SG_ 384 EPS2_SAS_SteerWhlRotSpdStatus "The status of rotation speed of the steering wheel.";
CM_ SG_ 384 EPS2_SAS_SASFailure "Steering angle sensor has a failure within it which results in the steering angle sensor being unable to produce a signal.";
CM_ SG_ 384 EPS2_SAS_Calibrated "SAS calibration state";
CM_ SG_ 384 EPS2_SAS_SteerWheelAngleValid "Effective signal for steering angle";
CM_ SG_ 384 EPS2_SAS_SteerWheelAngle "The current angle of the steering wheel(Positive, to left; Negative, to right)";
CM_ SG_ 385 VCU_Debug1 "PUPD_state";
CM_ SG_ 385 VCU_Debug2 "Charging Status";
CM_ SG_ 385 VCU_Debug3 "Termal Status";
CM_ SG_ 385 VCU_Debug4 "VCU Diagnostic System Error Level";
CM_ SG_ 386 VCU_FS_A_1 "L2 Accelerator Pedal Sensor 1 Low Voltage Confirmed Error
";
CM_ SG_ 386 VCU_FS_A_2 "L2 Accelerator Pedal Sensor 1 High Voltage Confirmed Error
";
CM_ SG_ 386 VCU_FS_A_3 "L2 Accelerator Pedal Sensor 2 Low Voltage Confirmed Error
";
CM_ SG_ 386 VCU_FS_A_4 "L2 Accelerator Pedal Sensor 2 High Voltage Confirmed Error
";
CM_ SG_ 386 VCU_FS_A_5 "L2 Pedal Position Sensor Plausibility Failure
";
CM_ SG_ 386 VCU_FS_A_6 "L2 Brake Pedal Invalid
";
CM_ SG_ 386 VCU_FS_A_7 "L2 Powertrain Activation Comparison Confirmed Error
";
CM_ SG_ 386 VCU_FS_A_8 "L2 Crash Detection Confirmed Error
";
CM_ SG_ 386 VCU_FS_A_9 "L2 Park Lock Engagement Request After Crash
";
CM_ SG_ 386 VCU_FS_A_10 "L2 Actual Gear Comparison Confirmed Error
";
CM_ SG_ 386 VCU_FS_A_11 "L2 Target Gear Comparison Confirmed Error
";
CM_ SG_ 386 VCU_FS_A_12 "L2 Vehicle Moving Distance in Park Confirmed Error
";
CM_ SG_ 386 VCU_FS_A_13 "L2 Park Lock Request Comparison Confirmed Error
";
CM_ SG_ 386 VCU_FS_A_14 "L2 Park Lock Status Confirmed error
";
CM_ SG_ 386 VCU_FS_A_15 "L2 Rear EDS invalid active discharge confirmed error
";
CM_ SG_ 386 VCU_FS_A_16 "L2 Limphome Vehicle Speed Request
";
CM_ SG_ 386 VCU_FS_A_17 "L2 Front EDS failure status confirmed error
";
CM_ SG_ 386 VCU_FS_A_18 "L2 Rear EDS failure status confirmed error
";
CM_ SG_ 386 VCU_FS_A_19 "L2 Front EDS minimum available invalid torque confirmed error
";
CM_ SG_ 386 VCU_FS_A_20 "L2 ADAS function mode 1 High acceleration Confirmed Error
";
CM_ SG_ 386 VCU_FS_A_21 "L2 ADAS function mode 2 High acceleration Confirmed Error
";
CM_ SG_ 386 VCU_FS_A_22 "L2 Rear EDS minimum available invalid torque confirmed error
";
CM_ SG_ 386 VCU_FS_A_23 "L2 ADAS function mode 1 High Speed Confirmed Error
";
CM_ SG_ 386 VCU_FS_A_24 "L2 ADAS function mode 2 High Speed Confirmed Error
";
CM_ SG_ 386 VCU_FS_A_25 "L2 Front EDS invalid active discharge confirmed error
";
CM_ SG_ 386 VCU_FS_A_26 "L2 Sum Torque Request Comparison Confirmed Error during standstill
";
CM_ SG_ 386 VCU_FS_A_27 "L2 Sum Torque Request Comparison Confirmed Error during driving
";
CM_ SG_ 386 VCU_FS_A_28 "L2 Unintended Movement Comparison Confirmed Error during standstill
";
CM_ SG_ 386 VCU_FS_A_29 "L2 Unintended Torque At Neutral Comparison Confirmed Error during standstill
";
CM_ SG_ 386 VCU_FS_A_30 "L2 Unintended Torque At Neutral Comparison Confirmed Error during driving
";
CM_ SG_ 386 VCU_FS_A_31 "L2 Opposite Direction Sign Comparison Confirmed Error during standstill
";
CM_ SG_ 386 VCU_FS_A_32 "L2 Opposite Direction Sign Comparison Confirmed Error during driving
";
CM_ SG_ 386 VCU_FS_A_33 "L2 Front Torque Request Comparison Confirmed Error during standstill
";
CM_ SG_ 386 VCU_FS_A_34 "L2 Front Torque Request Comparison Confirmed Error during driving
";
CM_ SG_ 386 VCU_FS_A_35 "L2 Rear Torque Request Comparison Confirmed Error during standstill
";
CM_ SG_ 386 VCU_FS_A_36 "L2 Rear Torque Request Comparison Confirmed Error during driving
";
CM_ SG_ 386 VCU_FS_A_37 "L2 Request High Torque Change Rate Comparison Confirmed Error during standstill
";
CM_ SG_ 386 VCU_FS_A_38 "L2 Request High Torque Change Rate Comparison Confirmed Error during driving
";
CM_ SG_ 386 VCU_FS_A_39 "L2 Sum Torque Feedback Comparison Confirmed Error during standstill
";
CM_ SG_ 386 VCU_FS_A_40 "L2 Sum Torque Feedback Comparison Confirmed Error during driving
";
CM_ SG_ 386 VCU_FS_A_41 "L2 Torque Request Sign Comparison Confirmed Error during standstill
";
CM_ SG_ 386 VCU_FS_A_42 "L2 Torque Request Sign Comparison Confirmed Error during driving
";
CM_ SG_ 386 VCU_FS_A_43 "L2 Proximity Pilot Volatge Failure during AC charging
";
CM_ SG_ 386 VCU_FS_A_44 "L2 Proximity Pilot Volatge Failure during DC charging
";
CM_ SG_ 386 VCU_FS_A_45 "L2 DC Contactor Open Status Confirmed Error
";
CM_ SG_ 386 VCU_FS_A_46 "L2 DC Contactor Closed Status Confirmed Error
";
CM_ SG_ 386 VCU_FS_A_47 "L2 12V Power Supply in Functional Range Error
";
CM_ SG_ 386 VCU_FS_A_48 "L2 12V Power Supply Out of Range Error
";
CM_ SG_ 386 VCU_FS_A_49 "L2 Vehicle Speed Invalid
";
CM_ SG_ 386 VCU_FS_A_50 "L2 Front EDS Output Torque Invalid for FWD or AWD
";
CM_ SG_ 386 VCU_FS_A_51 "L2 Rear EDS Output Torque Invalid for RWD or AWD
";
CM_ SG_ 386 VCU_FS_A_52 "L2 BMS Error Level 2 OR 3 Confirmed Error
";
CM_ SG_ 386 VCU_FS_A_53 "L2 BMS Error Level 4 Confirmed Error
";
CM_ SG_ 386 VCU_FS_A_54 "L2 BMS Error Level 5, 6, OR 7 Confirmed Error
";
CM_ SG_ 386 VCU_FS_A_55 "L2 BMS Error Level 5, 6, OR 7 during charging Confirmed Error
";
CM_ SG_ 386 VCU_FS_A_56 "L2 Active BMS ISU Confirmed Error during driving
";
CM_ SG_ 386 VCU_FS_A_57 "L2 Active BMS ISU Confirmed Error during charging
";
CM_ SG_ 386 VCU_FS_A_58 "L2 Active BMS ISU Confirmed Error during stationary
";
CM_ SG_ 386 VCU_FS_A_59 "L2 BMS HVIL Status Confirmed Error during stationary
";
CM_ SG_ 386 VCU_FS_A_60 "L2 BMS HVIL Status Confirmed Error during charging
";
CM_ SG_ 386 VCU_FS_A_61 "L2 BMS HVIL Status Confirmed Error during driving
";
CM_ SG_ 386 VCU_FS_A_62 "L2 Front EDS Shut Off Path & Discharge Confirmed Error
";
CM_ SG_ 386 VCU_FS_A_63 "L2 Rear EDS Shut Off Path & Discharge Confirmed Error
";
CM_ SG_ 386 VCU_FS_A_64 "L2 Front EDS power off request Confirmed Error
";
CM_ SG_ 387 VCU_FS_B_1 "L2 Rear EDS power off request Confirmed Error
";
CM_ SG_ 387 VCU_FS_B_2 "L2 Front EDS HVIL Status Confirmed Error during driving
";
CM_ SG_ 387 VCU_FS_B_3 "L2 Front EDS HVIL Status Confirmed Error during charging

";
CM_ SG_ 387 VCU_FS_B_4 "L2 Front EDS HVIL Status Confirmed Error during standstill

";
CM_ SG_ 387 VCU_FS_B_5 "L2 Rear EDS HVIL Status Confirmed Error during driving

";
CM_ SG_ 387 VCU_FS_B_6 "L2 Rear EDS HVIL Status Confirmed Error during charging

";
CM_ SG_ 387 VCU_FS_B_7 "L2 Rear EDS HVIL Status Confirmed Error during standstill

";
CM_ SG_ 387 VCU_FS_B_8 "L2 Front EDS Discharge Status Confirmed Error

";
CM_ SG_ 387 VCU_FS_B_9 "L2 Rear EDS Discharge Status Confirmed Error

";
CM_ SG_ 387 VCU_FS_B_10 "L2 Front EDS FuSa and Epark Status Confirmed Error
";
CM_ SG_ 387 VCU_FS_B_11 "L2 Rear EDS FuSa and Epark Status Confirmed Error

";
CM_ SG_ 387 VCU_FS_B_12 "L2 Front EDS FuSa and Epark Confirmed Error

";
CM_ SG_ 387 VCU_FS_B_13 "L2 Rear EDS FuSa and Epark Confirmed Error

";
CM_ SG_ 387 VCU_FS_B_14 "L2 Front EDS Epark confirmed error

";
CM_ SG_ 387 VCU_FS_B_15 "L2 Rear EDS Epark confirmed error

";
CM_ SG_ 387 VCU_FS_B_16 "L2 DCDC Output Voltage Confirmed Error

";
CM_ SG_ 387 VCU_FS_B_17 "L2 DCDC Output Current Confirmed Error
";
CM_ SG_ 387 VCU_FS_B_18 "L2 BMS Battery Voltage or Current Request Error During AC Charging Confirmed Error
";
CM_ SG_ 387 VCU_FS_B_19 "L2 BMS Battery Voltage or Current Request Error During DC Charging Confirmed Error
";
CM_ SG_ 387 VCU_FS_B_20 "L2 Front EDS Fail Grade Error 5 confirmed error

";
CM_ SG_ 387 VCU_FS_B_21 "L2 Rear EDS Fail Grade Error 5 confirmed error

";
CM_ SG_ 387 VCU_FS_B_22 "L2 AWD - Front EDS Fail Grade Error 4 confirmed error

";
CM_ SG_ 387 VCU_FS_B_23 "L2 AWD - Rear EDS Fail Grade Error 4 confirmed error

";
CM_ SG_ 387 VCU_FS_B_24 "L2 FWD EDS Fail Grade Error 4 confirmed error

";
CM_ SG_ 387 VCU_FS_B_25 "L2 RWD EDS Fail Grade Error 4 confirmed error

";
CM_ SG_ 387 VCU_FS_B_26 "L2 Front EDS Fail Grade Error 4 with ASC confirmed error
";
CM_ SG_ 387 VCU_FS_B_27 "L2 Rear EDS Fail Grade Error 4 with ASC confirmed error

";
CM_ SG_ 387 VCU_FS_B_28 "L2 Front EDS Fail Grade Error 4 confirmed error

";
CM_ SG_ 387 VCU_FS_B_29 "L2 Rear EDS Fail Grade Error 4 confirmed error

";
CM_ SG_ 387 VCU_FS_B_30 "L2 Front EDS Fail Grade or FuSa Error  confirmed error
";
CM_ SG_ 387 VCU_FS_B_31 "L2 Rear EDS Fail Grade or FuSa Error  confirmed error
";
CM_ SG_ 387 VCU_FS_B_32 "L2 BMS status confirmed error
";
CM_ SG_ 387 VCU_FS_B_33 "L2 HV Power Monitoring confirmed error

";
CM_ SG_ 387 VCU_FS_B_34 "L2 OBC Status confirmed error
";
CM_ SG_ 387 VCU_FS_B_35 "L2 DCDC Fault confirmed error
";
CM_ SG_ 387 VCU_FS_B_36 "L2 Invalid OBC status confirmed error
";
CM_ SG_ 387 VCU_FS_B_37 "L2 Invalid OBC charger values confirmed error
";
CM_ SG_ 387 VCU_FS_B_38 "L2 OBC Error level 3 charging confirmed error
";
CM_ SG_ 387 VCU_FS_B_39 "L2 OBC Error level 4 charging confirmed error
";
CM_ SG_ 387 VCU_FS_B_40 "L2 OBC Error level 5 charging confirmed error
";
CM_ SG_ 387 VCU_FS_B_41 "L2 DCDC Error level 4 charging confirmed error
";
CM_ SG_ 387 VCU_FS_B_42 "L2 DCDC Error level 5 charging confirmed error
";
CM_ SG_ 387 VCU_FS_B_43 "L2 Fast Charge Contactor Welded Status Confirmed Error
";
CM_ SG_ 387 VCU_FS_B_44 "L2 Fast Charge Contactor Not Available Status Confirmed Error

";
CM_ SG_ 387 VCU_FS_B_45 "L2 Invalid DC Contactor Status Confirmed Error
";
CM_ SG_ 387 VCU_FS_B_46 "L2 BMS maximum allowable charging current Confirmed Error during AC charging
";
CM_ SG_ 387 VCU_FS_B_47 "L2 BMS maximum allowable charging current Confirmed Error during DC charging
";
CM_ SG_ 387 VCU_FS_B_48 "L2 BMS maximum allowable charging current Confirmed Error during driving
";
CM_ SG_ 387 VCU_FS_B_49 "L2 BMS System Status Confirmed Error during stationary
";
CM_ SG_ 387 VCU_FS_B_50 "L2 BMS System Status Confirmed Error during driving
";
CM_ SG_ 387 VCU_FS_B_51 "L2 BMS Error Message Confirmed Error during stationary
";
CM_ SG_ 387 VCU_FS_B_52 "L2 BMS Error Message Confirmed Error during driving
";
CM_ SG_ 387 VCU_FS_B_53 "L2 BMS System Status Confirmed Error during AC charging

";
CM_ SG_ 387 VCU_FS_B_54 "L2 BMS System Status Confirmed Error during DC charging
";
CM_ SG_ 387 VCU_FS_B_55 "L2 BMS Error Message Confirmed Error during AC charging
";
CM_ SG_ 387 VCU_FS_B_56 "L2 BMS Error Message Confirmed Error during DC charging
";
CM_ SG_ 387 VCU_FS_B_57 "L2 BMS System Status and Error Message Confirmed Error
";
CM_ SG_ 387 VCU_FS_B_58 "L2 DCDC status 6 confirmed error
";
CM_ SG_ 387 VCU_FS_B_59 "L2 DCDC status 5 confirmed error
";
CM_ SG_ 387 VCU_FS_B_60 "L2 OBC status 6 confirmed error
";
CM_ SG_ 387 VCU_FS_B_61 "L2 OBC status 5 confirmed error
";
CM_ SG_ 387 VCU_FS_B_62 "L2 OBC status 4 confirmed error
";
CM_ SG_ 387 VCU_FS_B_63 "L2 Accelerator pedal sensor 1 and 2 ADC confirmed error
";
CM_ SG_ 387 VCU_FS_B_64 "L2 AC charge gun connection confirmed error
";
CM_ SG_ 389 VCU_FS_C_1 "L2 DC charge gun connection confirmed error";
CM_ SG_ 389 VCU_FS_C_2 "L2 Cruise control activation confirmed error";
CM_ SG_ 389 VCU_FS_C_3 "L2 BCM door status invalid confirmed error";
CM_ SG_ 389 VCU_FS_C_4 "L2 MHU EV Settings confirmed error during driving";
CM_ SG_ 389 VCU_FS_C_5 "L2 MHU EV Settings confirmed error during charging";
CM_ SG_ 389 VCU_FS_C_6 "L2 Key invalid status confirmed error";
CM_ SG_ 389 VCU_FS_C_7 "L2 ESC Longitudinal acceleration invalid confirmed error";
CM_ SG_ 389 VCU_FS_C_8 "L2 Accelerator pedal sensors creep confirmed error";
CM_ SG_ 389 VCU_FS_C_9 "L2 Invalid BCM battery voltage confirmed error";
CM_ SG_ 389 VCU_FS_C_10 "L2 Below threshold BCM battery voltage confirmed error";
CM_ SG_ 389 VCU_FS_C_11 "L2 Powertrain Activation Comparison Confirmed Error during driving";
CM_ SG_ 389 VCU_FS_C_12 "L2 Front EDS Invalid HVIL status Confirmed Error during driving";
CM_ SG_ 389 VCU_FS_C_13 "L2 Front EDS Invalid HVIL status Confirmed Error during charging";
CM_ SG_ 389 VCU_FS_C_14 "L2 Front EDS Invalid HVIL status Confirmed Error during stationary";
CM_ SG_ 389 VCU_FS_C_15 "L2 Rear EDS Invalid HVIL status Confirmed Error during driving";
CM_ SG_ 389 VCU_FS_C_16 "L2 Rear EDS Invalid HVIL status Confirmed Error during charging";
CM_ SG_ 389 VCU_FS_C_17 "L2 Rear EDS Invalid HVIL status Confirmed Error during stationary";
CM_ SG_ 389 VCU_FS_C_18 "L2 DCDC invalid output values confirmed error during driving";
CM_ SG_ 389 VCU_FS_C_19 "L2 DCDC invalid output status confirmed error during driving";
CM_ SG_ 389 VCU_FS_C_20 "L2 DCFC Error Level 2 confirmed error";
CM_ SG_ 389 VCU_FS_C_21 "L2 DCFC Error Level 3 confirmed error";
CM_ SG_ 389 VCU_FS_C_22 "L2 EPB Invalid confirmed error";
CM_ SG_ 389 VCU_FS_C_23 "L2 EPB Parking Status Invalid";
CM_ SG_ 389 VCU_FS_C_24 "L2 EDS IGBT Invalid Driving confirmed error";
CM_ SG_ 389 VCU_FS_C_25 "L2 EDS IGBT Invalid confirmed error";
CM_ SG_ 389 VCU_FS_C_26 "L2 Vehicle Speed Invalid confirmed error";
CM_ SG_ 389 VCU_FS_C_27 "L2 Regen brake Invalid confirmed error";
CM_ SG_ 389 VCU_FS_C_28 "L2 Regen brake torque request confirmed error";
CM_ SG_ 389 VCU_FS_C_29 "L2 DCDC disable request comparison confirmed error";
CM_ SG_ 389 VCU_FS_C_30 "L2 DCDC not available status confirmed error";
CM_ SG_ 389 VCU_FS_C_31 "L2 DCDC enable request comparison confirmed error";
CM_ SG_ 389 VCU_FS_C_32 "L2 ESC torque intervention increase confirmed error";
CM_ SG_ 389 VCU_FS_C_33 "L2 ESC torque intervention decrease confirmed error";
CM_ SG_ 389 VCU_FS_C_34 "L2 IDB torque request increase stat confirmed error";
CM_ SG_ 389 VCU_FS_C_35 "L2 IDB torque request decrease drv confirmed error";
CM_ SG_ 389 VCU_FS_C_36 "L2 accelerator pedal sensor 1 intermittent confirmed error";
CM_ SG_ 389 VCU_FS_C_37 "L2 accelerator pedal sensor 2 intermittent confirmed error";
CM_ SG_ 389 VCU_FS_C_38 "L2 DCDC status comparison confirmed error";
CM_ SG_ 389 VCU_FS_C_39 "L2 ADAS - RP mode invalid message confirmed error";
CM_ SG_ 389 VCU_FS_C_40 "L2 Front EDS motor status confirmed error";
CM_ SG_ 389 VCU_FS_C_41 "L2 Rear EDS motor status confirmed error";
CM_ SG_ 389 VCU_FS_C_42 "L2 crash detection confirmed error during charging";
CM_ SG_ 389 VCU_FS_C_43 "L2 crash invalid status confirmed error";
CM_ SG_ 389 VCU_FS_C_44 "L2 DCDC error level failed confirmed error";
CM_ SG_ 389 VCU_FS_C_45 "L2 OBC error level failed confirmed error";
CM_ SG_ 389 VCU_FS_C_46 "L2 DCFC error level failed confirmed error";
CM_ SG_ 389 VCU_FS_C_47 "L2 Spare 1";
CM_ SG_ 389 VCU_FS_C_48 "L2 Spare 2";
CM_ SG_ 389 VCU_FS_C_49 "L2 Spare 3";
CM_ SG_ 389 VCU_FS_C_50 "L2 Spare 4";
CM_ SG_ 389 VCU_FS_C_51 "L2 Spare 5";
CM_ SG_ 389 VCU_FS_C_52 "L2 Spare 6";
CM_ SG_ 389 VCU_FS_C_53 "L2 Spare 7";
CM_ SG_ 389 VCU_FS_C_54 "L2 Spare 8";
CM_ SG_ 389 VCU_FS_C_55 "L2 Spare 9";
CM_ SG_ 389 VCU_FS_C_56 "L2 Spare 10";
CM_ SG_ 389 VCU_FS_C_57 "L2 Spare 11";
CM_ SG_ 389 VCU_FS_C_58 "L2 Spare 12";
CM_ SG_ 389 VCU_FS_C_59 "L2 Spare 13";
CM_ SG_ 389 VCU_FS_C_60 "L2 Spare 14";
CM_ SG_ 389 VCU_FS_C_61 "L2 Spare 15";
CM_ SG_ 389 VCU_FS_C_62 "L2 Spare 16";
CM_ SG_ 389 VCU_FS_C_63 "L2 Spare 17";
CM_ SG_ 389 VCU_FS_C_64 "L2 Spare 18";
CM_ SG_ 417 CHSKM_V_VEH "Checksum";
CM_ SG_ 417 ALIV_V_VEH "Alive counter";
CM_ SG_ 417 V_VEH_COG "Vehicle speed for powertrain";
CM_ SG_ 417 DVCO_VEH "Driving condition";
CM_ SG_ 417 QU_V_VEH_COG "Vehicle speed valid";
CM_ SG_ 430 CRC_VCU_FR_TorqCap "Checksum";
CM_ SG_ 430 ALIV_VCU_FR_TorqCap "Alive counter";
CM_ SG_ 430 VCU_MaxTorq_FR "FR Max Driving Torque ( instant value, wheel level, considered system status )";
CM_ SG_ 430 VCU_MaxTorq_Sts_FR "Indicate status of FR Max Driving Torque";
CM_ SG_ 430 VCU_MinTorq_FR "FR Min Driving Torque ( instant value, wheel level, considered system status )";
CM_ SG_ 430 VCU_MinTorq_Sts_FR "Indicate status of FR Min Driving Torque";
CM_ SG_ 430 SECCAN_VCU_FR_TorqCap "Seed generated from Secure CAN algorithm
";
CM_ SG_ 431 CRC_VCU_RR_TorqCap "Checksum";
CM_ SG_ 431 ALIV_VCU_RR_TorqCap "Alive counter";
CM_ SG_ 431 VCU_MaxTorq_RR "RR Max Driving Torque ( instant value, wheel level, considered system status )";
CM_ SG_ 431 VCU_MaxTorq_Sts_RR "Indicate status of RR Max Driving Torque";
CM_ SG_ 431 VCU_MinTorq_RR "RR Min Driving Torque ( instant value, wheel level, considered system status )";
CM_ SG_ 431 VCU_MinTorq_Sts_RR "Indicate status of RR Min Driving Torque";
CM_ SG_ 431 SECCAN_VCU_RR_TorqCap "Seed generated from Secure CAN algorithm
";
CM_ SG_ 504 CHKSM_EDS_OutPut_FR "Check sum";
CM_ SG_ 504 ALV_EDS_OutPut_FR "Alive Counter";
CM_ SG_ 504 EDS_Work_STS_FR "EDS Work status ";
CM_ SG_ 504 EDS_Spd_FR "Current motor speed";
CM_ SG_ 504 EDS_output_trqValid_FR "Indicate the valid flag of current motor torque";
CM_ SG_ 504 EDS_MotorDriveSts_FR "The drive state of EDS";
CM_ SG_ 504 EDS_powoff_req_FR "If there is a serious failure in the running process of EDS, the high voltage of VCU will be requested ";
CM_ SG_ 504 EDS_SpdValid_FR "Indicate the valid flag of current motor speed";
CM_ SG_ 504 EDS_output_trq_FR "Actual output torque of current EDS";
CM_ SG_ 504 EDS_VCU_6SO_flag_FWD "Indicate the valid flag of current front motor 6SO possible";
CM_ SG_ 505 CHKSM_EDS_OutPut_RR "Check sum";
CM_ SG_ 505 ALV_EDS_OutPut_RR "Alive Counter";
CM_ SG_ 505 EDS_Work_STS_RR "Rear EDS Work status ";
CM_ SG_ 505 EDS_Spd_RR "current rear motor speed";
CM_ SG_ 505 EDS_output_trqValid_RR "Indicate the valid flag of current rear motor torque";
CM_ SG_ 505 EDS_MotorDriveSts_RR "The drive state of rear EDS";
CM_ SG_ 505 EDS_powoff_req_RR " If there is a serious failure in the running process of rear EDS, the high voltage of VCU will be requested ";
CM_ SG_ 505 EDS_SpdValid_RR "Indicate the valid flag of current rear motor speed";
CM_ SG_ 505 EDS_output_trq_RR "Actual output torque of current Rear motor ";
CM_ SG_ 505 EDS_VCU_6SO_flag_RWD "Indicate the valid flag of current rear motor 6SO possible";
CM_ SG_ 524 CHKSM_IC_ODO "Checksum";
CM_ SG_ 524 ALIV_IC_ODO "Alive Counter";
CM_ SG_ 524 MHU_Odometer_IC "Odometer information.";
CM_ SG_ 531 CHSKM_VCU_POD_reqDCDC "Check sum";
CM_ SG_ 531 ALV_VCU_POD_reqDCDC "Alive counter";
CM_ SG_ 531 VCU_enableDCDC "Requests DCDC to turn on";
CM_ SG_ 531 VCU_vDCDCRequest "voltage output request for DCDC";
CM_ SG_ 531 VCU_iDCDCRequest_lim "This signal indicates limit value for output current, calculated basing on 12V power management strategy and limitted by POD_DCDC_Max_Current_Out.";
CM_ SG_ 532 CRC_VCU_ADAS "Checksum
";
CM_ SG_ 532 ALIV_VCU_ADAS "Alive counter
";
CM_ SG_ 532 VCU_ADAS_ControledRes "VCU Handshake Request Feedback ";
CM_ SG_ 532 VCU_ADAS_Available "VCU Availability for APA Control ";
CM_ SG_ 532 VCU_Accel_Pedal_Position_Virtual "Virtual Accel Pedal Position
";
CM_ SG_ 532 VCU_ADAS_FuncMode "VCU & APA Function Mode";
CM_ SG_ 532 VCU_ADAS_CtrlAbortFeedback "VCU Active Abort Feedback ";
CM_ SG_ 533 Checksum_0x215 "Checksum";
CM_ SG_ 533 Rolling_Counter_0x215 "Rolling Counter";
CM_ SG_ 533 BMS_BatBalance_ERR "Battery Balance Error indicates Balancing switch is short or open";
CM_ SG_ 533 BMS_Balance_STS "BMS Balance Status ";
CM_ SG_ 533 BMS_IGN_Sts "the ignition signal status (on/off)";
CM_ SG_ 533 BMS_HWCrash_Sts "Battery Pack Hardware Crash signal Status";
CM_ SG_ 533 BMS_HVIL_STS "The HVIL state of BMS";
CM_ SG_ 533 BMS_HVOnOff_STS "Status of the High Voltage";
CM_ SG_ 533 BMS_ERR_LEV "BMS requesting VCU to operate at the limited operating strategy (LOS)";
CM_ SG_ 533 BMS_SocActual_EST "Actual SOC ";
CM_ SG_ 533 BMS_Sys_STS "BMS_Status(Self-test after BMS wake-up) BMS VCU";
CM_ SG_ 533 BMS_ISU_Status "Pack Insulation Status";
CM_ SG_ 533 BMS_SOH "BMS State Of Health ";
CM_ SG_ 533 BMS_SOE "BMS State Of Enegy ";
CM_ SG_ 533 BMS_HV_Sts "HV Status";
CM_ SG_ 545 CCUR_Req_AirCondition "On Off Air Condition to CCUF";
CM_ SG_ 545 SECCAN_CCUR "Seed generated from Secure CAN algorithm";
CM_ SG_ 546 FRONT_SET_Rear_AirCondition "On Off Air Condition of Rear";
CM_ SG_ 546 SECCAN_CCUF "Seed generated from Secure CAN algorithm";
CM_ SG_ 553 CHSKM_VCU_EDSControl_Front "Checksum";
CM_ SG_ 553 ALV_VCU_EDSControl_Front "Alive Counter";
CM_ SG_ 553 VCU_EDS_StsModeReq_FWD "EDS Status Request ";
CM_ SG_ 553 VCU_EDS_TargetTqMin_FWD "Min Target torque";
CM_ SG_ 553 VCU_EparkCMD_FWD "Epark command from VCU";
CM_ SG_ 553 VCU_EDS_demtrq_FWD "Driving Requirements Torque from VCU to EDS";
CM_ SG_ 553 VCU_EDS_TargetTqMax_FWD "Max Target torque";
CM_ SG_ 553 VCU_EDS_ActiveHeating_Request "Active heating function request status";
CM_ SG_ 553 VCU_EDS_CreepFlg_FWD "Enable  or Disable  Front-Wheel Drive Creep Function";
CM_ SG_ 553 VCU_EDS_HILLHoldFlg_FWD "Enable  or Disable  Front-Wheel Drive HILL Hold Calibration";
CM_ SG_ 553 VCU_EDS_demtrqValid_FWD "Validity bit for the signal VCU_EDS_demtrq_FWD";
CM_ SG_ 553 VCU_EDS_HeatPowerDemand "VCU to EDS Heating Demand in kilowat";
CM_ SG_ 560 CHSKM_VCU_EDSControl_Rear "Checksum";
CM_ SG_ 560 ALV_VCU_EDSControl_Rear "Alive Counter";
CM_ SG_ 560 VCU_EDS_TargetTqMin_RWD "Min Target torque";
CM_ SG_ 560 VCU_EDS_demtrq_RWD "Driving Requirements Torque from VCU to EDS";
CM_ SG_ 560 VCU_EDS_StsModeReq_RWD "EDS Status Request ";
CM_ SG_ 560 VCU_EDS_TargetTqMax_RWD "Max Target torque";
CM_ SG_ 560 VCU_EDS_demtrqValid_RWD "Validity bit for the signal VCU_EDS_demtrq_RWD";
CM_ SG_ 560 VCU_EDS_HILLHoldFlg_RWD "Enable  or Disable  Front-Wheel Drive HILL Hold Calibration";
CM_ SG_ 560 VCU_EDS_CreepFlg_RWD "Enable  or Disable  Front-Wheel Drive Creep Function";
CM_ SG_ 565 CHKSM_TRM_STATUS "Checksum";
CM_ SG_ 565 ALIVE_TRM_STATUS "Alive counter";
CM_ SG_ 565 TowingDetected "Towing status ( reserved )";
CM_ SG_ 565 TrailerDetected "Trailer Detected status";

BA_DEF_ BO_  "GenMsgSendType" ENUM "Cyclic","NotUsed","NotUsed","NotUsed","NotUsed","NotUsed","NotUsed","IfActive","NoMsgSendType","NotUsed";
BA_DEF_ BO_  "GenMsgILSupport" ENUM "No","Yes";
BA_DEF_ BO_  "DiagResponse" ENUM "No","Yes";
BA_DEF_ BO_  "DiagRequest" ENUM "No","Yes";
BA_DEF_ BO_  "NmAsrMessage" ENUM "No","Yes";
BA_DEF_ BO_  "DiagState" ENUM "No","Yes";
BA_DEF_ BO_  "DiagUudtResponse" ENUM "False","True";
BA_DEF_ BO_  "GenMsgStartDelayTime" INT 0 65535;
BA_DEF_ BO_  "GenMsgDelayTime" INT 0 0;
BA_DEF_ BO_  "GenMsgNrOfRepetition" INT 0 0;
BA_DEF_ BO_  "GenMsgCycleTimeFast" INT 0 0;
BA_DEF_ BO_  "GenMsgCycleTime" INT 0 0;
BA_DEF_ BU_  "NmStationAddress" HEX 0 0;
BA_DEF_ BU_  "Address" HEX 0 255;
BA_DEF_ BU_  "TpSTMin" INT 0 255;
BA_DEF_ BU_  "ILUsed" ENUM "No","Yes";
BA_DEF_ BU_  "NmAsrNode" ENUM "No","Yes";
BA_DEF_ BU_  "NmAsrNodeIdentifier" HEX 0 255;
BA_DEF_ BU_  "NmAsrCanMsgCycleOffset" INT 0 65535;
BA_DEF_ BU_  "NmAsrCanMsgReducedTime" INT 320 640;
BA_DEF_ SG_  "GenSigSendType" ENUM "Cyclic","OnWrite","OnWriteWithRepetition","OnChange","OnChangeWithRepetition","IfActive","IfActiveWithRepetition","NoSigSendType","NotUsed","NotUsed","NotUsed","NotUsed","NotUsed";
BA_DEF_ SG_  "InvalidValue" STRING;
BA_DEF_ SG_  "GenSigStartValue" INT 0 0;
BA_DEF_ SG_  "GenSigTimeoutTime_ALL" INT 0 65535;
BA_DEF_  "DBName" STRING;
BA_DEF_  "NmAsrBaseAddress" HEX 0 2047;
BA_DEF_  "NmAsrMessageCount" INT 1 256;
BA_DEF_  "NmAsrTimeoutTime" INT 0 65535;
BA_DEF_  "NmAsrWaitBusSleepTime" INT 0 65535;
BA_DEF_  "NmAsrRepeatMessageTime" INT 0 65535;
BA_DEF_  "NmAsrCanMsgCycleTime" INT 0 65535;
BA_DEF_  "Baudrate" INT 0 1000000;
BA_DEF_  "BusType" STRING;
BA_DEF_  "NmType" STRING;
BA_DEF_  "Manufacturer" STRING;
BA_DEF_ BU_  "ECU" STRING;

BA_DEF_DEF_  "Address" 0;
BA_DEF_DEF_  "Baudrate" 500000;
BA_DEF_DEF_  "DiagRequest" "No";
BA_DEF_DEF_  "DiagResponse" "No";
BA_DEF_DEF_  "DiagState" "No";
BA_DEF_DEF_  "DiagUudtResponse" "False";
BA_DEF_DEF_  "GenMsgCycleTime" 0;
BA_DEF_DEF_  "GenMsgCycleTimeFast" 0;
BA_DEF_DEF_  "GenMsgDelayTime" 0;
BA_DEF_DEF_  "GenMsgILSupport" "Yes";
BA_DEF_DEF_  "GenMsgNrOfRepetition" 0;
BA_DEF_DEF_  "GenMsgSendType" "NoMsgSendType";
BA_DEF_DEF_  "GenMsgStartDelayTime" 0;
BA_DEF_DEF_  "GenSigSendType" "Cyclic";
BA_DEF_DEF_  "GenSigStartValue" 0;
BA_DEF_DEF_  "GenSigTimeoutTime_ALL" 0;
BA_DEF_DEF_  "ILUsed" "Yes";
BA_DEF_DEF_  "Manufacturer" "VinFast";
BA_DEF_DEF_  "NmAsrBaseAddress" 1280;
BA_DEF_DEF_  "NmAsrCanMsgCycleOffset" 0;
BA_DEF_DEF_  "NmAsrCanMsgCycleTime" 640;
BA_DEF_DEF_  "NmAsrCanMsgReducedTime" 320;
BA_DEF_DEF_  "NmAsrMessage" "No";
BA_DEF_DEF_  "NmAsrMessageCount" 128;
BA_DEF_DEF_  "NmAsrNode" "Yes";
BA_DEF_DEF_  "NmAsrNodeIdentifier" 0;
BA_DEF_DEF_  "NmAsrRepeatMessageTime" 3200;
BA_DEF_DEF_  "NmAsrTimeoutTime" 2000;
BA_DEF_DEF_  "NmAsrWaitBusSleepTime" 1500;
BA_DEF_DEF_  "NmStationAddress" 0;
BA_DEF_DEF_  "TpSTMin" 20;

BA_ "BusType" "CAN";
BA_ "DBName" "PT";
BA_ "NmType" "NmAsr";
BA_ "ECU" BU_ BMS_Tester "BMS_Tester";
BA_ "NmAsrCanMsgCycleOffset" BU_ BMS_Tester 480;
BA_ "NmAsrCanMsgReducedTime" BU_ BMS_Tester 560;
BA_ "NmAsrNodeIdentifier" BU_ BMS_Tester 96;
BA_ "NmStationAddress" BU_ BMS_Tester 96;
BA_ "Address" BU_ EDS_F 27;
BA_ "ECU" BU_ EDS_F "EDS_F";
BA_ "NmAsrCanMsgCycleOffset" BU_ EDS_F 135;
BA_ "NmAsrNodeIdentifier" BU_ EDS_F 27;
BA_ "NmStationAddress" BU_ EDS_F 27;
BA_ "Address" BU_ EDS_R 26;
BA_ "ECU" BU_ EDS_R "EDS_R";
BA_ "NmAsrCanMsgCycleOffset" BU_ EDS_R 130;
BA_ "NmAsrCanMsgReducedTime" BU_ EDS_R 385;
BA_ "NmAsrNodeIdentifier" BU_ EDS_R 26;
BA_ "NmStationAddress" BU_ EDS_R 26;
BA_ "Address" BU_ EPS2 43;
BA_ "ECU" BU_ EPS2 "EPS_PtCAN";
BA_ "NmAsrCanMsgCycleOffset" BU_ EPS2 215;
BA_ "NmAsrNodeIdentifier" BU_ EPS2 43;
BA_ "NmStationAddress" BU_ EPS2 43;
BA_ "NmAsrCanMsgCycleOffset" BU_ FCAM_PT 110;
BA_ "NmStationAddress" BU_ FCAM_PT 22;
BA_ "NmAsrNodeIdentifier" BU_ FCAM_PT 22;
BA_ "Address" BU_ FCAM_PT 22;
BA_ "ECU" BU_ FCAM_PT "XGW_PT_CAN";
BA_ "Address" BU_ GS 16;
BA_ "ECU" BU_ GS "PT_CAN_GS";
BA_ "NmAsrCanMsgCycleOffset" BU_ GS 80;
BA_ "NmAsrCanMsgReducedTime" BU_ GS 360;
BA_ "NmAsrNodeIdentifier" BU_ GS 16;
BA_ "NmStationAddress" BU_ GS 16;
BA_ "Address" BU_ IDB_PT 41;
BA_ "ECU" BU_ IDB_PT "PT_CAN_IDB";
BA_ "NmAsrCanMsgCycleOffset" BU_ IDB_PT 205;
BA_ "NmAsrNodeIdentifier" BU_ IDB_PT 41;
BA_ "NmStationAddress" BU_ IDB_PT 41;
BA_ "Address" BU_ POD 61;
BA_ "ECU" BU_ POD "POD";
BA_ "NmAsrCanMsgCycleOffset" BU_ POD 305;
BA_ "NmAsrNodeIdentifier" BU_ POD 61;
BA_ "NmStationAddress" BU_ POD 61;
BA_ "Address" BU_ RCU_PT 39;
BA_ "ECU" BU_ RCU_PT "PT_CAN_RCU";
BA_ "NmAsrCanMsgCycleOffset" BU_ RCU_PT 195;
BA_ "NmAsrNodeIdentifier" BU_ RCU_PT 39;
BA_ "NmStationAddress" BU_ RCU_PT 39;
BA_ "Address" BU_ VCU_PT 44;
BA_ "ECU" BU_ VCU_PT "PT_CAN_VCU";
BA_ "NmAsrCanMsgCycleOffset" BU_ VCU_PT 220;
BA_ "NmAsrCanMsgReducedTime" BU_ VCU_PT 430;
BA_ "NmAsrNodeIdentifier" BU_ VCU_PT 44;
BA_ "NmStationAddress" BU_ VCU_PT 44;
BA_ "Address" BU_ XGW_PT 2;
BA_ "ECU" BU_ XGW_PT "XGW_PtCAN";
BA_ "NmAsrCanMsgCycleOffset" BU_ XGW_PT 10;
BA_ "NmAsrCanMsgReducedTime" BU_ XGW_PT 325;
BA_ "NmAsrNodeIdentifier" BU_ XGW_PT 2;
BA_ "NmStationAddress" BU_ XGW_PT 2;
BA_ "GenMsgCycleTime" BO_ 133 20;
BA_ "GenMsgSendType" BO_ 133 0;
BA_ "GenMsgCycleTime" BO_ 147 100;
BA_ "GenMsgSendType" BO_ 147 0;
BA_ "GenMsgCycleTime" BO_ 148 100;
BA_ "GenMsgSendType" BO_ 148 0;
BA_ "GenMsgCycleTime" BO_ 149 100;
BA_ "GenMsgSendType" BO_ 149 0;
BA_ "GenMsgCycleTime" BO_ 150 100;
BA_ "GenMsgSendType" BO_ 150 0;
BA_ "GenMsgCycleTime" BO_ 217 20;
BA_ "GenMsgSendType" BO_ 217 0;
BA_ "GenMsgCycleTime" BO_ 218 20;
BA_ "GenMsgSendType" BO_ 218 0;
BA_ "GenMsgCycleTime" BO_ 219 20;
BA_ "GenMsgSendType" BO_ 219 0;
BA_ "GenMsgCycleTime" BO_ 225 20;
BA_ "GenMsgSendType" BO_ 225 0;
BA_ "GenMsgSendType" BO_ 226 0;
BA_ "GenMsgCycleTime" BO_ 226 20;
BA_ "GenMsgCycleTime" BO_ 256 1000;
BA_ "GenMsgSendType" BO_ 256 0;
BA_ "GenMsgCycleTime" BO_ 260 100;
BA_ "GenMsgSendType" BO_ 260 0;
BA_ "GenMsgCycleTime" BO_ 261 100;
BA_ "GenMsgSendType" BO_ 261 0;
BA_ "GenMsgCycleTime" BO_ 264 50;
BA_ "GenMsgSendType" BO_ 264 0;
BA_ "GenMsgCycleTime" BO_ 265 100;
BA_ "GenMsgCycleTimeFast" BO_ 265 30;
BA_ "GenMsgNrOfRepetition" BO_ 265 3;
BA_ "GenMsgSendType" BO_ 265 0;
BA_ "GenMsgCycleTime" BO_ 266 500;
BA_ "GenMsgSendType" BO_ 266 0;
BA_ "GenMsgCycleTime" BO_ 274 100;
BA_ "GenMsgCycleTimeFast" BO_ 274 20;
BA_ "GenMsgNrOfRepetition" BO_ 274 3;
BA_ "GenMsgSendType" BO_ 274 0;
BA_ "GenMsgCycleTime" BO_ 278 500;
BA_ "GenMsgSendType" BO_ 278 0;
BA_ "GenMsgCycleTime" BO_ 290 200;
BA_ "GenMsgSendType" BO_ 290 0;
BA_ "GenMsgCycleTime" BO_ 291 500;
BA_ "GenMsgSendType" BO_ 291 0;
BA_ "GenMsgCycleTime" BO_ 292 500;
BA_ "GenMsgSendType" BO_ 292 0;
BA_ "GenMsgCycleTime" BO_ 303 100;
BA_ "GenMsgSendType" BO_ 303 0;
BA_ "GenMsgCycleTime" BO_ 311 100;
BA_ "GenMsgSendType" BO_ 311 0;
BA_ "GenMsgSendType" BO_ 316 0;
BA_ "GenMsgCycleTime" BO_ 316 20;
BA_ "GenMsgCycleTime" BO_ 317 100;
BA_ "GenMsgSendType" BO_ 317 0;
BA_ "GenMsgCycleTime" BO_ 338 20;
BA_ "GenMsgSendType" BO_ 338 0;
BA_ "GenMsgCycleTime" BO_ 339 20;
BA_ "GenMsgSendType" BO_ 339 0;
BA_ "GenMsgCycleTime" BO_ 357 50;
BA_ "GenMsgSendType" BO_ 357 0;
BA_ "GenMsgCycleTime" BO_ 372 1000;
BA_ "GenMsgSendType" BO_ 372 0;
BA_ "GenMsgCycleTime" BO_ 374 1000;
BA_ "GenMsgSendType" BO_ 374 0;
BA_ "GenMsgCycleTime" BO_ 376 10;
BA_ "GenMsgSendType" BO_ 376 0;
BA_ "GenMsgCycleTime" BO_ 377 10;
BA_ "GenMsgSendType" BO_ 377 0;
BA_ "GenMsgCycleTime" BO_ 381 10;
BA_ "GenMsgSendType" BO_ 381 0;
BA_ "GenMsgCycleTime" BO_ 384 10;
BA_ "GenMsgSendType" BO_ 384 0;
BA_ "GenMsgCycleTime" BO_ 385 100;
BA_ "GenMsgSendType" BO_ 385 0;
BA_ "GenMsgCycleTime" BO_ 386 100;
BA_ "GenMsgSendType" BO_ 386 0;
BA_ "GenMsgCycleTime" BO_ 387 100;
BA_ "GenMsgSendType" BO_ 387 0;
BA_ "GenMsgCycleTime" BO_ 389 100;
BA_ "GenMsgSendType" BO_ 389 0;
BA_ "GenMsgCycleTime" BO_ 417 20;
BA_ "GenMsgSendType" BO_ 417 0;
BA_ "GenMsgCycleTime" BO_ 430 20;
BA_ "GenMsgSendType" BO_ 430 0;
BA_ "GenMsgCycleTime" BO_ 431 20;
BA_ "GenMsgSendType" BO_ 431 0;
BA_ "GenMsgCycleTime" BO_ 504 20;
BA_ "GenMsgSendType" BO_ 504 0;
BA_ "GenMsgCycleTime" BO_ 505 20;
BA_ "GenMsgSendType" BO_ 505 0;
BA_ "GenMsgCycleTime" BO_ 524 100;
BA_ "GenMsgSendType" BO_ 524 0;
BA_ "GenMsgCycleTime" BO_ 531 100;
BA_ "GenMsgSendType" BO_ 531 0;
BA_ "GenMsgCycleTime" BO_ 532 20;
BA_ "GenMsgSendType" BO_ 532 0;
BA_ "GenMsgCycleTime" BO_ 533 50;
BA_ "GenMsgSendType" BO_ 533 0;
BA_ "GenMsgCycleTime" BO_ 545 200;
BA_ "GenMsgSendType" BO_ 545 0;
BA_ "GenMsgCycleTime" BO_ 546 200;
BA_ "GenMsgSendType" BO_ 546 0;
BA_ "GenMsgCycleTime" BO_ 553 20;
BA_ "GenMsgSendType" BO_ 553 0;
BA_ "GenMsgCycleTime" BO_ 560 20;
BA_ "GenMsgSendType" BO_ 560 0;
BA_ "GenMsgCycleTime" BO_ 565 100;
BA_ "GenMsgSendType" BO_ 565 0;
BA_ "GenSigTimeoutTime_ALL" SG_ 133 CHKSM_CRASH_Sts 200;
BA_ "InvalidValue" SG_ 133 CHKSM_CRASH_Sts "";
BA_ "GenSigTimeoutTime_ALL" SG_ 133 ALV_CRASH_Sts 200;
BA_ "InvalidValue" SG_ 133 ALV_CRASH_Sts "Fh";
BA_ "GenSigTimeoutTime_ALL" SG_ 133 ACM_Crash_Sts 200;
BA_ "InvalidValue" SG_ 133 ACM_Crash_Sts "3h";
BA_ "GenSigTimeoutTime_ALL" SG_ 133 ACM_Airbag_Deployment_Status 200;
BA_ "InvalidValue" SG_ 133 ACM_Airbag_Deployment_Status "3h";
BA_ "GenSigTimeoutTime_ALL" SG_ 133 ACM_Crash_Intensity 200;
BA_ "InvalidValue" SG_ 133 ACM_Crash_Intensity "7h";
BA_ "GenSigTimeoutTime_ALL" SG_ 133 ACM_Front_Crash 200;
BA_ "InvalidValue" SG_ 133 ACM_Front_Crash "3h";
BA_ "GenSigTimeoutTime_ALL" SG_ 133 ACM_DriverSide_Crash 200;
BA_ "InvalidValue" SG_ 133 ACM_DriverSide_Crash "3h";
BA_ "GenSigTimeoutTime_ALL" SG_ 133 ACM_PassSide_Crash 200;
BA_ "InvalidValue" SG_ 133 ACM_PassSide_Crash "3h";
BA_ "GenSigTimeoutTime_ALL" SG_ 133 ACM_Rear_Crash 200;
BA_ "InvalidValue" SG_ 133 ACM_Rear_Crash "3h";
BA_ "GenSigTimeoutTime_ALL" SG_ 133 ACM_Rollover_Crash 200;
BA_ "InvalidValue" SG_ 133 ACM_Rollover_Crash "3h";
BA_ "GenSigTimeoutTime_ALL" SG_ 147 CHKSM_MILEAGE 500;
BA_ "InvalidValue" SG_ 147 CHKSM_MILEAGE "";
BA_ "GenSigTimeoutTime_ALL" SG_ 147 ALIVE_MILEAGE 500;
BA_ "InvalidValue" SG_ 147 ALIVE_MILEAGE "Fh";
BA_ "GenSigTimeoutTime_ALL" SG_ 147 Mileage 500;
BA_ "InvalidValue" SG_ 147 Mileage "FFFFh";
BA_ "GenSigTimeoutTime_ALL" SG_ 148 VCU_Pump_3_Stt 500;
BA_ "InvalidValue" SG_ 148 VCU_Pump_3_Stt "";
BA_ "GenSigTimeoutTime_ALL" SG_ 148 VCU_Pump_3_Flowrate 500;
BA_ "InvalidValue" SG_ 148 VCU_Pump_3_Flowrate "";
BA_ "GenSigTimeoutTime_ALL" SG_ 149 CHKSM_IDB_FUNCTION 500;
BA_ "InvalidValue" SG_ 149 CHKSM_IDB_FUNCTION "";
BA_ "GenSigTimeoutTime_ALL" SG_ 149 ALV_IDB_FUNCTION 500;
BA_ "InvalidValue" SG_ 149 ALV_IDB_FUNCTION "Fh";
BA_ "GenSigTimeoutTime_ALL" SG_ 149 STAT_ABS 500;
BA_ "InvalidValue" SG_ 149 STAT_ABS "3h";
BA_ "GenSigTimeoutTime_ALL" SG_ 149 ABS_Active 500;
BA_ "InvalidValue" SG_ 149 ABS_Active "3h";
BA_ "GenSigTimeoutTime_ALL" SG_ 149 AYC_Active 500;
BA_ "InvalidValue" SG_ 149 AYC_Active "3h";
BA_ "GenSigTimeoutTime_ALL" SG_ 149 ASR_Active 500;
BA_ "InvalidValue" SG_ 149 ASR_Active "3h";
BA_ "GenSigTimeoutTime_ALL" SG_ 149 STAT_DSC 500;
BA_ "InvalidValue" SG_ 149 STAT_DSC "3h";
BA_ "GenSigTimeoutTime_ALL" SG_ 149 DSC_Active 500;
BA_ "InvalidValue" SG_ 149 DSC_Active "3h";
BA_ "GenSigTimeoutTime_ALL" SG_ 149 HBA_ActiveSignal 500;
BA_ "InvalidValue" SG_ 149 HBA_ActiveSignal "3h";
BA_ "GenSigTimeoutTime_ALL" SG_ 149 ARM_ActiveSignal 500;
BA_ "InvalidValue" SG_ 149 ARM_ActiveSignal "3h";
BA_ "GenSigTimeoutTime_ALL" SG_ 149 STAT_AutoHazardBlinking 500;
BA_ "InvalidValue" SG_ 149 STAT_AutoHazardBlinking "3h";
BA_ "GenSigTimeoutTime_ALL" SG_ 149 MSR_Active 500;
BA_ "InvalidValue" SG_ 149 MSR_Active "3h";
BA_ "GenSigTimeoutTime_ALL" SG_ 149 HSA_ActiveSignal 500;
BA_ "InvalidValue" SG_ 149 HSA_ActiveSignal "3h";
BA_ "GenSigTimeoutTime_ALL" SG_ 149 EPBi_ECD_ActiveSignal 500;
BA_ "InvalidValue" SG_ 149 EPBi_ECD_ActiveSignal "3h";
BA_ "GenSigTimeoutTime_ALL" SG_ 149 TSM_Active 500;
BA_ "InvalidValue" SG_ 149 TSM_Active "3h";
BA_ "GenSigTimeoutTime_ALL" SG_ 149 HAS_Available 500;
BA_ "InvalidValue" SG_ 149 HAS_Available "3h";
BA_ "GenSigTimeoutTime_ALL" SG_ 149 STAT_EBD 500;
BA_ "InvalidValue" SG_ 149 STAT_EBD "3h";
BA_ "GenSigTimeoutTime_ALL" SG_ 149 EBD_Active 500;
BA_ "InvalidValue" SG_ 149 EBD_Active "3h";
BA_ "GenSigTimeoutTime_ALL" SG_ 149 ST_BRG_MSA 500;
BA_ "InvalidValue" SG_ 149 ST_BRG_MSA "Fh";
BA_ "GenSigTimeoutTime_ALL" SG_ 150 CHKSM_MHU_IDB_Mode_Select 500;
BA_ "InvalidValue" SG_ 150 CHKSM_MHU_IDB_Mode_Select "";
BA_ "GenSigTimeoutTime_ALL" SG_ 150 ALV_MHU_IDB_Mode_Select 500;
BA_ "InvalidValue" SG_ 150 ALV_MHU_IDB_Mode_Select "Fh";
BA_ "GenSigTimeoutTime_ALL" SG_ 150 MHU_IDB_Mode_Select_Signal 500;
BA_ "InvalidValue" SG_ 150 MHU_IDB_Mode_Select_Signal "";
BA_ "GenSigTimeoutTime_ALL" SG_ 217 CRC_VCU_HV_DrvSys_status 200;
BA_ "InvalidValue" SG_ 217 CRC_VCU_HV_DrvSys_status "";
BA_ "GenSigTimeoutTime_ALL" SG_ 217 ALIV_VCU_HV_DrvSys_status 200;
BA_ "InvalidValue" SG_ 217 ALIV_VCU_HV_DrvSys_status "Fh";
BA_ "GenSigTimeoutTime_ALL" SG_ 217 VCU_HVsystem_status 200;
BA_ "InvalidValue" SG_ 217 VCU_HVsystem_status "";
BA_ "GenSigTimeoutTime_ALL" SG_ 217 VCU_ACPD_Percent 200;
BA_ "InvalidValue" SG_ 217 VCU_ACPD_Percent "FFFh";
BA_ "GenSigTimeoutTime_ALL" SG_ 217 VCU_ACPD_Percent_Valid 200;
BA_ "InvalidValue" SG_ 217 VCU_ACPD_Percent_Valid "";
BA_ "GenSigTimeoutTime_ALL" SG_ 217 VCU_ACTGear 200;
BA_ "InvalidValue" SG_ 217 VCU_ACTGear "";
BA_ "GenSigTimeoutTime_ALL" SG_ 217 VCU_ACTGearValid 200;
BA_ "InvalidValue" SG_ 217 VCU_ACTGearValid "";
BA_ "GenSigTimeoutTime_ALL" SG_ 217 VCU_ACT_DriveMode 200;
BA_ "InvalidValue" SG_ 217 VCU_ACT_DriveMode "";
BA_ "GenSigStartValue" SG_ 217 VCU_ACT_DriveMode_Valid 1;
BA_ "GenSigTimeoutTime_ALL" SG_ 217 VCU_ACT_DriveMode_Valid 200;
BA_ "InvalidValue" SG_ 217 VCU_ACT_DriveMode_Valid "";
BA_ "GenSigTimeoutTime_ALL" SG_ 217 VCU_HV_DRVsystem_status 200;
BA_ "InvalidValue" SG_ 217 VCU_HV_DRVsystem_status "";
BA_ "GenSigTimeoutTime_ALL" SG_ 217 VCU_Recu_BrakeLight_ON_Req 200;
BA_ "InvalidValue" SG_ 217 VCU_Recu_BrakeLight_ON_Req "3h";
BA_ "GenSigTimeoutTime_ALL" SG_ 218 CRC_VCU_IDB_Regen_Cap 200;
BA_ "InvalidValue" SG_ 218 CRC_VCU_IDB_Regen_Cap "";
BA_ "GenSigTimeoutTime_ALL" SG_ 218 ALIV_VCU_IDB_Regen_Cap 200;
BA_ "InvalidValue" SG_ 218 ALIV_VCU_IDB_Regen_Cap "Fh";
BA_ "GenSigTimeoutTime_ALL" SG_ 218 VCU_RecuBrakeTorqCap_FR 200;
BA_ "InvalidValue" SG_ 218 VCU_RecuBrakeTorqCap_FR "";
BA_ "GenSigTimeoutTime_ALL" SG_ 218 VCU_RecuBrkTorqCap_Sts_FR 200;
BA_ "InvalidValue" SG_ 218 VCU_RecuBrkTorqCap_Sts_FR "";
BA_ "GenSigTimeoutTime_ALL" SG_ 218 VCU_RecuBrakeTorqCap_RR 200;
BA_ "InvalidValue" SG_ 218 VCU_RecuBrakeTorqCap_RR "";
BA_ "GenSigTimeoutTime_ALL" SG_ 218 VCU_RecuBrkTorqCap_Sts_RR 200;
BA_ "InvalidValue" SG_ 218 VCU_RecuBrkTorqCap_Sts_RR "";
BA_ "GenSigTimeoutTime_ALL" SG_ 218 VCU_IDB_DrvIntdTorqFr 200;
BA_ "InvalidValue" SG_ 218 VCU_IDB_DrvIntdTorqFr "";
BA_ "GenSigTimeoutTime_ALL" SG_ 219 CRC_VCU_IDB_Regen_Act 200;
BA_ "InvalidValue" SG_ 219 CRC_VCU_IDB_Regen_Act "";
BA_ "GenSigTimeoutTime_ALL" SG_ 219 ALIV_VCU_IDB_Regen_Act 200;
BA_ "InvalidValue" SG_ 219 ALIV_VCU_IDB_Regen_Act "Fh";
BA_ "GenSigTimeoutTime_ALL" SG_ 219 VCU_BrkRegenTorqueAct_FR 200;
BA_ "InvalidValue" SG_ 219 VCU_BrkRegenTorqueAct_FR "";
BA_ "GenSigTimeoutTime_ALL" SG_ 219 VCU_BrkRegenTorqueActValid_FR 200;
BA_ "InvalidValue" SG_ 219 VCU_BrkRegenTorqueActValid_FR "";
BA_ "GenSigTimeoutTime_ALL" SG_ 219 VCU_BrkRegenTorqueAct_RR 200;
BA_ "InvalidValue" SG_ 219 VCU_BrkRegenTorqueAct_RR "";
BA_ "GenSigTimeoutTime_ALL" SG_ 219 VCU_BrkRegenTorqueActValid_RR 200;
BA_ "InvalidValue" SG_ 219 VCU_BrkRegenTorqueActValid_RR "";
BA_ "GenSigTimeoutTime_ALL" SG_ 219 VCU_IDB_DrvIntdTorqRe 200;
BA_ "GenSigTimeoutTime_ALL" SG_ 225 CRC_IDB_VCU_ACC_TorqueRequest 200;
BA_ "InvalidValue" SG_ 225 CRC_IDB_VCU_ACC_TorqueRequest "";
BA_ "GenSigTimeoutTime_ALL" SG_ 225 Alive_IDB_VCU_ACC_TorqueRequest 200;
BA_ "InvalidValue" SG_ 225 Alive_IDB_VCU_ACC_TorqueRequest "Fh";
BA_ "GenSigTimeoutTime_ALL" SG_ 225 IDB_ACC_WheelTrq_Request 200;
BA_ "GenSigTimeoutTime_ALL" SG_ 225 IDB_ACC_TargetWheel_Torque 200;
BA_ "InvalidValue" SG_ 225 IDB_ACC_TargetWheel_Torque "";
BA_ "GenSigTimeoutTime_ALL" SG_ 225 SECCAN_IDB_VCU_ACC_Torq 200;
BA_ "GenSigTimeoutTime_ALL" SG_ 226 CRC_IDB_VCU_APA_TorqueRequest 200;
BA_ "InvalidValue" SG_ 226 Alive_IDB_VCU_APA_TorqueRequest "Fh";
BA_ "GenSigTimeoutTime_ALL" SG_ 226 Alive_IDB_VCU_APA_TorqueRequest 200;
BA_ "GenSigTimeoutTime_ALL" SG_ 226 IDB_APA_WheelTrq_Request 200;
BA_ "GenSigTimeoutTime_ALL" SG_ 226 IDB_APA_TargetWheel_Torque 200;
BA_ "GenSigTimeoutTime_ALL" SG_ 226 SECCAN_IDB_VCU_APA_Torque 200;
BA_ "GenSigTimeoutTime_ALL" SG_ 256 CHKSM_MHU_VEH_INFO 5000;
BA_ "InvalidValue" SG_ 256 CHKSM_MHU_VEH_INFO "";
BA_ "GenSigTimeoutTime_ALL" SG_ 256 ALV_MHU_VEH_INFO 5000;
BA_ "InvalidValue" SG_ 256 ALV_MHU_VEH_INFO "Fh";
BA_ "GenSigTimeoutTime_ALL" SG_ 256 MHU_UserProfileId 5000;
BA_ "InvalidValue" SG_ 256 MHU_UserProfileId "Fh";
BA_ "GenSigTimeoutTime_ALL" SG_ 256 MHU_Connectivity_Status 5000;
BA_ "InvalidValue" SG_ 256 MHU_Connectivity_Status "0";
BA_ "GenSigTimeoutTime_ALL" SG_ 260 CHKSM_LV_BATT_CHARG 500;
BA_ "InvalidValue" SG_ 260 CHKSM_LV_BATT_CHARG "";
BA_ "GenSigTimeoutTime_ALL" SG_ 260 ALIV_LV_BATT_CHARG 500;
BA_ "InvalidValue" SG_ 260 ALIV_LV_BATT_CHARG "Fh";
BA_ "GenSigStartValue" SG_ 260 SOH_SUL 255;
BA_ "GenSigTimeoutTime_ALL" SG_ 260 SOH_SUL 500;
BA_ "InvalidValue" SG_ 260 SOH_SUL "FFh";
BA_ "GenSigStartValue" SG_ 260 SOH_SUL_STATE 3;
BA_ "GenSigTimeoutTime_ALL" SG_ 260 SOH_SUL_STATE 500;
BA_ "InvalidValue" SG_ 260 SOH_SUL_STATE "3h";
BA_ "GenSigStartValue" SG_ 260 SOC_STATE 3;
BA_ "GenSigTimeoutTime_ALL" SG_ 260 SOC_STATE 500;
BA_ "InvalidValue" SG_ 260 SOC_STATE "3h";
BA_ "GenSigTimeoutTime_ALL" SG_ 260 Resp_Error 500;
BA_ "InvalidValue" SG_ 260 Resp_Error "";
BA_ "GenSigTimeoutTime_ALL" SG_ 260 FLAG_INCONSTENCY 500;
BA_ "InvalidValue" SG_ 260 FLAG_INCONSTENCY "";
BA_ "GenSigTimeoutTime_ALL" SG_ 260 EBS_error 500;
BA_ "InvalidValue" SG_ 260 EBS_error "";
BA_ "GenSigTimeoutTime_ALL" SG_ 260 FLAG_DISCONNECT 500;
BA_ "InvalidValue" SG_ 260 FLAG_DISCONNECT "";
BA_ "GenSigTimeoutTime_ALL" SG_ 260 BCM_LV_Batt_Charging_Req 500;
BA_ "InvalidValue" SG_ 260 BCM_LV_Batt_Charging_Req "";
BA_ "GenSigStartValue" SG_ 260 LV_TargetVoltage 26;
BA_ "GenSigTimeoutTime_ALL" SG_ 260 LV_TargetVoltage 500;
BA_ "InvalidValue" SG_ 260 LV_TargetVoltage "-";
BA_ "GenSigStartValue" SG_ 260 LV_TargetCurrent 512;
BA_ "GenSigTimeoutTime_ALL" SG_ 260 LV_TargetCurrent 500;
BA_ "InvalidValue" SG_ 260 LV_TargetCurrent "-";
BA_ "GenSigTimeoutTime_ALL" SG_ 261 CHKSM_BCM_STAT_DOOR_FLAP 500;
BA_ "InvalidValue" SG_ 261 CHKSM_BCM_STAT_DOOR_FLAP "";
BA_ "GenSigTimeoutTime_ALL" SG_ 261 ALIVE_BCM_STAT_DOOR_FLAP 500;
BA_ "InvalidValue" SG_ 261 ALIVE_BCM_STAT_DOOR_FLAP "Fh";
BA_ "GenSigTimeoutTime_ALL" SG_ 261 BCM_STAT_TrunkAjar 500;
BA_ "InvalidValue" SG_ 261 BCM_STAT_TrunkAjar "3h";
BA_ "GenSigTimeoutTime_ALL" SG_ 261 BCM_STAT_DoorAjarFL 500;
BA_ "InvalidValue" SG_ 261 BCM_STAT_DoorAjarFL "3h";
BA_ "GenSigTimeoutTime_ALL" SG_ 261 BCM_STAT_DoorAjarFR 500;
BA_ "InvalidValue" SG_ 261 BCM_STAT_DoorAjarFR "3h";
BA_ "GenSigTimeoutTime_ALL" SG_ 261 BCM_STAT_DoorAjarRL 500;
BA_ "InvalidValue" SG_ 261 BCM_STAT_DoorAjarRL "3h";
BA_ "GenSigTimeoutTime_ALL" SG_ 261 BCM_STAT_DoorAjarRR 500;
BA_ "InvalidValue" SG_ 261 BCM_STAT_DoorAjarRR "3h";
BA_ "GenSigTimeoutTime_ALL" SG_ 261 BCM_STAT_BonnetAjar 500;
BA_ "InvalidValue" SG_ 261 BCM_STAT_BonnetAjar "3h";
BA_ "GenSigTimeoutTime_ALL" SG_ 264 CHKSM_GS_DriveReq 500;
BA_ "InvalidValue" SG_ 264 CHKSM_GS_DriveReq "";
BA_ "GenSigTimeoutTime_ALL" SG_ 264 ALIVE_GS_DriveReq 500;
BA_ "InvalidValue" SG_ 264 ALIVE_GS_DriveReq "Fh";
BA_ "GenSigTimeoutTime_ALL" SG_ 264 GS_TargetGearReq 500;
BA_ "InvalidValue" SG_ 264 GS_TargetGearReq "";
BA_ "GenSigTimeoutTime_ALL" SG_ 265 CHKSM_BCM_SWITCH_Sts 500;
BA_ "InvalidValue" SG_ 265 CHKSM_BCM_SWITCH_Sts "";
BA_ "GenSigTimeoutTime_ALL" SG_ 265 ALV_BCM_SWITCH_Sts 500;
BA_ "InvalidValue" SG_ 265 ALV_BCM_SWITCH_Sts "Fh";
BA_ "GenSigSendType" SG_ 265 BCM_STAT_BrakeSwitch 4;
BA_ "GenSigTimeoutTime_ALL" SG_ 265 BCM_STAT_BrakeSwitch 500;
BA_ "InvalidValue" SG_ 265 BCM_STAT_BrakeSwitch "3h";
BA_ "GenSigSendType" SG_ 265 BCM_STAT_HazardWarn 4;
BA_ "GenSigTimeoutTime_ALL" SG_ 265 BCM_STAT_HazardWarn 500;
BA_ "InvalidValue" SG_ 265 BCM_STAT_HazardWarn "3h";
BA_ "GenSigSendType" SG_ 265 BCM_STAT_FuelPumpCutOFF 4;
BA_ "GenSigTimeoutTime_ALL" SG_ 265 BCM_STAT_FuelPumpCutOFF 500;
BA_ "InvalidValue" SG_ 265 BCM_STAT_FuelPumpCutOFF "3h";
BA_ "GenSigTimeoutTime_ALL" SG_ 265 BCM_FollowMeHomeActive 500;
BA_ "InvalidValue" SG_ 265 BCM_FollowMeHomeActive "3h";
BA_ "GenSigSendType" SG_ 265 BCM_STAT_Horn 4;
BA_ "GenSigTimeoutTime_ALL" SG_ 265 BCM_STAT_Horn 500;
BA_ "InvalidValue" SG_ 265 BCM_STAT_Horn "3h";
BA_ "GenSigSendType" SG_ 265 BCM_STAT_Autowiping 4;
BA_ "GenSigTimeoutTime_ALL" SG_ 265 BCM_STAT_Autowiping 500;
BA_ "InvalidValue" SG_ 265 BCM_STAT_Autowiping "3h";
BA_ "GenSigTimeoutTime_ALL" SG_ 265 BCM_TurnIndicator 500;
BA_ "InvalidValue" SG_ 265 BCM_TurnIndicator "3h";
BA_ "GenSigTimeoutTime_ALL" SG_ 265 BCM_WelcomeActive 500;
BA_ "InvalidValue" SG_ 265 BCM_WelcomeActive "3h";
BA_ "GenSigTimeoutTime_ALL" SG_ 265 BCM_HighBeam 500;
BA_ "InvalidValue" SG_ 265 BCM_HighBeam "3h";
BA_ "GenSigTimeoutTime_ALL" SG_ 265 ACM_Seat_Belt_Status_3rd_Row_Pas 500;
BA_ "InvalidValue" SG_ 265 ACM_Seat_Belt_Status_3rd_Row_Pas "";
BA_ "GenSigTimeoutTime_ALL" SG_ 265 ACM_Seat_Belt_Status_3rd_Row_Dri 500;
BA_ "InvalidValue" SG_ 265 ACM_Seat_Belt_Status_3rd_Row_Dri "";
BA_ "GenSigTimeoutTime_ALL" SG_ 266 CHKSM_BCM_VOLTAGE 2500;
BA_ "InvalidValue" SG_ 266 CHKSM_BCM_VOLTAGE "";
BA_ "GenSigTimeoutTime_ALL" SG_ 266 ALIVE_BCM_VOLTAGE 2500;
BA_ "InvalidValue" SG_ 266 ALIVE_BCM_VOLTAGE "Fh";
BA_ "GenSigStartValue" SG_ 266 UBatt 9205;
BA_ "GenSigTimeoutTime_ALL" SG_ 266 UBatt 2500;
BA_ "InvalidValue" SG_ 266 UBatt "3FFFh";
BA_ "GenSigStartValue" SG_ 266 LV_Batt_Temp 40;
BA_ "GenSigTimeoutTime_ALL" SG_ 266 LV_Batt_Temp 2500;
BA_ "InvalidValue" SG_ 266 LV_Batt_Temp "FFh";
BA_ "GenSigTimeoutTime_ALL" SG_ 266 LV_SOC 2500;
BA_ "InvalidValue" SG_ 266 LV_SOC "FFh";
BA_ "GenSigStartValue" SG_ 266 LV_Batt_Current 49152;
BA_ "GenSigTimeoutTime_ALL" SG_ 266 LV_Batt_Current 2500;
BA_ "InvalidValue" SG_ 266 LV_Batt_Current "FFFFh";
BA_ "GenSigTimeoutTime_ALL" SG_ 266 LV_BatteryType 2500;
BA_ "InvalidValue" SG_ 266 LV_BatteryType "-";
BA_ "GenSigTimeoutTime_ALL" SG_ 274 CHKSM_BCM_CLAMP_STAT 500;
BA_ "InvalidValue" SG_ 274 CHKSM_BCM_CLAMP_STAT "";
BA_ "GenSigTimeoutTime_ALL" SG_ 274 ALIVE_BCM_CLAMP_STAT 500;
BA_ "InvalidValue" SG_ 274 ALIVE_BCM_CLAMP_STAT "Fh";
BA_ "GenSigSendType" SG_ 274 RemoteFunctionState 4;
BA_ "GenSigTimeoutTime_ALL" SG_ 274 RemoteFunctionState 500;
BA_ "InvalidValue" SG_ 274 RemoteFunctionState "3h";
BA_ "GenSigTimeoutTime_ALL" SG_ 274 STAT_BLS 500;
BA_ "InvalidValue" SG_ 274 STAT_BLS "3h";
BA_ "GenSigTimeoutTime_ALL" SG_ 274 STAT_CL_50_L 500;
BA_ "InvalidValue" SG_ 274 STAT_CL_50_L "3h";
BA_ "GenSigSendType" SG_ 274 Clamp50AdviceRemoteStart 4;
BA_ "GenSigTimeoutTime_ALL" SG_ 274 Clamp50AdviceRemoteStart 500;
BA_ "InvalidValue" SG_ 274 Clamp50AdviceRemoteStart "3h";
BA_ "GenSigSendType" SG_ 274 Clamp50AdviceESS 4;
BA_ "GenSigTimeoutTime_ALL" SG_ 274 Clamp50AdviceESS 500;
BA_ "InvalidValue" SG_ 274 Clamp50AdviceESS "3h";
BA_ "GenSigTimeoutTime_ALL" SG_ 274 STAT_CL_R_L 500;
BA_ "InvalidValue" SG_ 274 STAT_CL_R_L "3h";
BA_ "GenSigTimeoutTime_ALL" SG_ 274 STAT_CL_15_1_L 500;
BA_ "InvalidValue" SG_ 274 STAT_CL_15_1_L "3h";
BA_ "GenSigTimeoutTime_ALL" SG_ 274 STAT_CL_15_1_DME_L 500;
BA_ "InvalidValue" SG_ 274 STAT_CL_15_1_DME_L "3h";
BA_ "GenSigTimeoutTime_ALL" SG_ 274 FobId 500;
BA_ "InvalidValue" SG_ 274 FobId "3h";
BA_ "GenSigTimeoutTime_ALL" SG_ 274 STAT_Terminal 500;
BA_ "InvalidValue" SG_ 274 STAT_Terminal "7h";
BA_ "GenSigTimeoutTime_ALL" SG_ 274 STAT_CL30_C_BEV 500;
BA_ "InvalidValue" SG_ 274 STAT_CL30_C_BEV "3h";
BA_ "GenSigTimeoutTime_ALL" SG_ 274 BCM_Clamp_Transport 500;
BA_ "InvalidValue" SG_ 274 BCM_Clamp_Transport "7h";
BA_ "GenSigTimeoutTime_ALL" SG_ 278 CHKSM_LVBAT_INFO2 2500;
BA_ "InvalidValue" SG_ 278 CHKSM_LVBAT_INFO2 "-";
BA_ "GenSigTimeoutTime_ALL" SG_ 278 ALIV_LVBAT_INFO2 2500;
BA_ "InvalidValue" SG_ 278 ALIV_LVBAT_INFO2 "Fh";
BA_ "GenSigTimeoutTime_ALL" SG_ 278 LV_MaxAllowDischargeCurrent 2500;
BA_ "InvalidValue" SG_ 278 LV_MaxAllowDischargeCurrent "-";
BA_ "GenSigTimeoutTime_ALL" SG_ 278 LV_WakeupReason 2500;
BA_ "InvalidValue" SG_ 278 LV_WakeupReason "7h";
BA_ "GenSigTimeoutTime_ALL" SG_ 278 LV_MaxAllowChargeCurrent 2500;
BA_ "InvalidValue" SG_ 278 LV_MaxAllowChargeCurrent "-";
BA_ "GenSigTimeoutTime_ALL" SG_ 278 LV_SOE 2500;
BA_ "InvalidValue" SG_ 278 LV_SOE "-";
BA_ "GenSigTimeoutTime_ALL" SG_ 290 CHKSM_CCU_REQUEST 1000;
BA_ "InvalidValue" SG_ 290 CHKSM_CCU_REQUEST "";
BA_ "GenSigTimeoutTime_ALL" SG_ 290 ALV_CCU_REQUEST 1000;
BA_ "InvalidValue" SG_ 290 ALV_CCU_REQUEST "Fh";
BA_ "GenSigTimeoutTime_ALL" SG_ 290 CCU_REQ_MaxCool 1000;
BA_ "InvalidValue" SG_ 290 CCU_REQ_MaxCool "3h";
BA_ "GenSigStartValue" SG_ 290 CCU_REQ_MaxHeat 3;
BA_ "GenSigTimeoutTime_ALL" SG_ 290 CCU_REQ_MaxHeat 1000;
BA_ "InvalidValue" SG_ 290 CCU_REQ_MaxHeat "3h";
BA_ "GenSigStartValue" SG_ 290 CCU_REQ_ESSMotorControl 7;
BA_ "GenSigTimeoutTime_ALL" SG_ 290 CCU_REQ_ESSMotorControl 1000;
BA_ "InvalidValue" SG_ 290 CCU_REQ_ESSMotorControl "7h";
BA_ "GenSigTimeoutTime_ALL" SG_ 290 CCU_AC_PWM 1000;
BA_ "InvalidValue" SG_ 290 CCU_AC_PWM "7Fh";
BA_ "GenSigTimeoutTime_ALL" SG_ 291 CHKSM_ACChargingInfo 2500;
BA_ "InvalidValue" SG_ 291 CHKSM_ACChargingInfo "FFh";
BA_ "GenSigTimeoutTime_ALL" SG_ 291 ALIVE_ACChargingInfo 2500;
BA_ "InvalidValue" SG_ 291 ALIVE_ACChargingInfo "Fh";
BA_ "GenSigTimeoutTime_ALL" SG_ 291 ACCharging_MaxChargingPower 2500;
BA_ "InvalidValue" SG_ 291 ACCharging_MaxChargingPower "3FFh";
BA_ "GenSigTimeoutTime_ALL" SG_ 291 CurrentACChargingPower 2500;
BA_ "InvalidValue" SG_ 291 CurrentACChargingPower "3FFh";
BA_ "GenSigTimeoutTime_ALL" SG_ 291 ACCharging_MaxCurrent 2500;
BA_ "InvalidValue" SG_ 291 ACCharging_MaxCurrent "FFFFh";
BA_ "GenSigTimeoutTime_ALL" SG_ 292 CHKSM_DCChargingInfo 2500;
BA_ "InvalidValue" SG_ 292 CHKSM_DCChargingInfo "FFh";
BA_ "GenSigTimeoutTime_ALL" SG_ 292 ALIVE_DCChargingInfo 2500;
BA_ "InvalidValue" SG_ 292 ALIVE_DCChargingInfo "Fh";
BA_ "GenSigTimeoutTime_ALL" SG_ 292 DCCharging_MaxChargingPower 2500;
BA_ "InvalidValue" SG_ 292 DCCharging_MaxChargingPower "FFFFh";
BA_ "GenSigTimeoutTime_ALL" SG_ 292 CurrentDCChargingPower 2500;
BA_ "InvalidValue" SG_ 292 CurrentDCChargingPower "3FFh";
BA_ "GenSigTimeoutTime_ALL" SG_ 292 DCCharging_MaxCurrent 2500;
BA_ "InvalidValue" SG_ 292 DCCharging_MaxCurrent "FFFFh";
BA_ "GenSigSendType" SG_ 303 CHKSM_BCM_TERMINAL 3;
BA_ "GenSigTimeoutTime_ALL" SG_ 303 CHKSM_BCM_TERMINAL 500;
BA_ "InvalidValue" SG_ 303 CHKSM_BCM_TERMINAL "";
BA_ "GenSigSendType" SG_ 303 ALV_BCM_TERMINAL 3;
BA_ "GenSigTimeoutTime_ALL" SG_ 303 ALV_BCM_TERMINAL 500;
BA_ "InvalidValue" SG_ 303 ALV_BCM_TERMINAL "Fh";
BA_ "InvalidValue" SG_ 303 STAT_AlcoholIgnStatus "3h";
BA_ "GenSigTimeoutTime_ALL" SG_ 303 STAT_AlcoholIgnStatus 500;
BA_ "InvalidValue" SG_ 303 STAT_AlcoholEngineStatus "3h";
BA_ "GenSigTimeoutTime_ALL" SG_ 303 STAT_AlcoholEngineStatus 500;
BA_ "GenSigSendType" SG_ 303 ST_KL 3;
BA_ "GenSigTimeoutTime_ALL" SG_ 303 ST_KL 500;
BA_ "InvalidValue" SG_ 303 ST_KL "Fh";
BA_ "GenSigSendType" SG_ 303 ST_KL_KEY_VLD 3;
BA_ "GenSigTimeoutTime_ALL" SG_ 303 ST_KL_KEY_VLD 500;
BA_ "InvalidValue" SG_ 303 ST_KL_KEY_VLD "Fh";
BA_ "GenSigSendType" SG_ 303 ST_STCD_PENG 3;
BA_ "GenSigTimeoutTime_ALL" SG_ 303 ST_STCD_PENG 500;
BA_ "InvalidValue" SG_ 303 ST_STCD_PENG "3h";
BA_ "GenSigSendType" SG_ 303 ST_SSB 3;
BA_ "GenSigTimeoutTime_ALL" SG_ 303 ST_SSB 500;
BA_ "InvalidValue" SG_ 303 ST_SSB "3h";
BA_ "GenSigSendType" SG_ 303 RWDT_BLS 3;
BA_ "GenSigTimeoutTime_ALL" SG_ 303 RWDT_BLS 500;
BA_ "InvalidValue" SG_ 303 RWDT_BLS "Fh";
BA_ "GenSigSendType" SG_ 303 RQ_DRVG_RDI 3;
BA_ "GenSigTimeoutTime_ALL" SG_ 303 RQ_DRVG_RDI 500;
BA_ "InvalidValue" SG_ 303 RQ_DRVG_RDI "3h";
BA_ "GenSigSendType" SG_ 303 CTR_ENG_STOP 3;
BA_ "GenSigTimeoutTime_ALL" SG_ 303 CTR_ENG_STOP 500;
BA_ "InvalidValue" SG_ 303 CTR_ENG_STOP "3h";
BA_ "GenSigSendType" SG_ 303 ST_VEH_CON 3;
BA_ "GenSigTimeoutTime_ALL" SG_ 303 ST_VEH_CON 500;
BA_ "InvalidValue" SG_ 303 ST_VEH_CON "Fh";
BA_ "GenSigSendType" SG_ 310 PnC_activation 7;
BA_ "InvalidValue" SG_ 310 PnC_activation "";
BA_ "GenSigSendType" SG_ 310 PnCandEIM_Switch 7;
BA_ "InvalidValue" SG_ 310 PnCandEIM_Switch "";
BA_ "GenSigSendType" SG_ 310 PnC_trigger1 7;
BA_ "InvalidValue" SG_ 310 PnC_trigger1 "";
BA_ "GenSigSendType" SG_ 310 PnC_trigger2 7;
BA_ "InvalidValue" SG_ 310 PnC_trigger2 "";
BA_ "GenSigSendType" SG_ 310 PnC_feature_enable 7;
BA_ "InvalidValue" SG_ 310 PnC_feature_enable "";
BA_ "GenSigSendType" SG_ 311 OK_OldSessionJoined 7;
BA_ "GenSigTimeoutTime_ALL" SG_ 311 OK_OldSessionJoined 500;
BA_ "InvalidValue" SG_ 311 OK_OldSessionJoined "null";
BA_ "GenSigSendType" SG_ 311 OK_NewSessionEstablished 7;
BA_ "GenSigTimeoutTime_ALL" SG_ 311 OK_NewSessionEstablished 500;
BA_ "InvalidValue" SG_ 311 OK_NewSessionEstablished "null";
BA_ "GenSigSendType" SG_ 311 OK_CertificateExpireSoon 7;
BA_ "GenSigTimeoutTime_ALL" SG_ 311 OK_CertificateExpireSoon 500;
BA_ "InvalidValue" SG_ 311 OK_CertificateExpireSoon "null";
BA_ "GenSigSendType" SG_ 311 PnC_OK 7;
BA_ "GenSigStartValue" SG_ 311 PnC_OK 2;
BA_ "GenSigTimeoutTime_ALL" SG_ 311 PnC_OK 500;
BA_ "InvalidValue" SG_ 311 PnC_OK "null";
BA_ "GenSigSendType" SG_ 311 Failed_CertificateNoAllowAtEVSE 7;
BA_ "GenSigTimeoutTime_ALL" SG_ 311 Failed_CertificateNoAllowAtEVSE 500;
BA_ "InvalidValue" SG_ 311 Failed_CertificateNoAllowAtEVSE "null";
BA_ "GenSigSendType" SG_ 311 Failed_ContactorError 7;
BA_ "GenSigTimeoutTime_ALL" SG_ 311 Failed_ContactorError 500;
BA_ "InvalidValue" SG_ 311 Failed_ContactorError "null";
BA_ "GenSigSendType" SG_ 311 Failed_NoChargeServiceSelectd 7;
BA_ "GenSigTimeoutTime_ALL" SG_ 311 Failed_NoChargeServiceSelectd 500;
BA_ "InvalidValue" SG_ 311 Failed_NoChargeServiceSelectd "null";
BA_ "GenSigSendType" SG_ 311 PnC_Failed 7;
BA_ "GenSigTimeoutTime_ALL" SG_ 311 PnC_Failed 500;
BA_ "InvalidValue" SG_ 311 PnC_Failed "null";
BA_ "GenSigSendType" SG_ 311 Failed_ServiceIDInvalid 7;
BA_ "GenSigTimeoutTime_ALL" SG_ 311 Failed_ServiceIDInvalid 500;
BA_ "InvalidValue" SG_ 311 Failed_ServiceIDInvalid "null";
BA_ "GenSigSendType" SG_ 311 Falied_UnknownSession 7;
BA_ "GenSigTimeoutTime_ALL" SG_ 311 Falied_UnknownSession 500;
BA_ "InvalidValue" SG_ 311 Falied_UnknownSession "null";
BA_ "GenSigSendType" SG_ 311 Failed_SignatureError 7;
BA_ "GenSigTimeoutTime_ALL" SG_ 311 Failed_SignatureError 500;
BA_ "InvalidValue" SG_ 311 Failed_SignatureError "null";
BA_ "GenSigSendType" SG_ 311 Failed_SequenceError 7;
BA_ "GenSigTimeoutTime_ALL" SG_ 311 Failed_SequenceError 500;
BA_ "InvalidValue" SG_ 311 Failed_SequenceError "null";
BA_ "GenSigSendType" SG_ 311 Failed_CertChainError 7;
BA_ "GenSigTimeoutTime_ALL" SG_ 311 Failed_CertChainError 500;
BA_ "InvalidValue" SG_ 311 Failed_CertChainError "null";
BA_ "GenSigSendType" SG_ 311 Failed_NoCertificateAvailable 7;
BA_ "GenSigTimeoutTime_ALL" SG_ 311 Failed_NoCertificateAvailable 500;
BA_ "InvalidValue" SG_ 311 Failed_NoCertificateAvailable "null";
BA_ "GenSigSendType" SG_ 311 Failed_CertificateRevoked 7;
BA_ "GenSigTimeoutTime_ALL" SG_ 311 Failed_CertificateRevoked 500;
BA_ "InvalidValue" SG_ 311 Failed_CertificateRevoked "null";
BA_ "GenSigSendType" SG_ 311 Failed_PaymentSelectionInvalid 7;
BA_ "GenSigTimeoutTime_ALL" SG_ 311 Failed_PaymentSelectionInvalid 500;
BA_ "InvalidValue" SG_ 311 Failed_PaymentSelectionInvalid "null";
BA_ "GenSigSendType" SG_ 311 Failed_WrongChargeParameter 7;
BA_ "GenSigTimeoutTime_ALL" SG_ 311 Failed_WrongChargeParameter 500;
BA_ "InvalidValue" SG_ 311 Failed_WrongChargeParameter "null";
BA_ "GenSigSendType" SG_ 311 Failed_WrongEnergyTranferMode 7;
BA_ "GenSigTimeoutTime_ALL" SG_ 311 Failed_WrongEnergyTranferMode 500;
BA_ "InvalidValue" SG_ 311 Failed_WrongEnergyTranferMode "null";
BA_ "GenSigSendType" SG_ 311 Failed_ChallengeInvalid 7;
BA_ "GenSigTimeoutTime_ALL" SG_ 311 Failed_ChallengeInvalid 500;
BA_ "InvalidValue" SG_ 311 Failed_ChallengeInvalid "null";
BA_ "GenSigSendType" SG_ 311 Failed_ContractCancelled 7;
BA_ "GenSigTimeoutTime_ALL" SG_ 311 Failed_ContractCancelled 500;
BA_ "InvalidValue" SG_ 311 Failed_ContractCancelled "null";
BA_ "GenSigSendType" SG_ 311 Failed_MeteringSignatureNotValid 7;
BA_ "GenSigTimeoutTime_ALL" SG_ 311 Failed_MeteringSignatureNotValid 500;
BA_ "InvalidValue" SG_ 311 Failed_MeteringSignatureNotValid "null";
BA_ "GenSigSendType" SG_ 311 Failed_PowerDeliverNotApplied 7;
BA_ "GenSigTimeoutTime_ALL" SG_ 311 Failed_PowerDeliverNotApplied 500;
BA_ "InvalidValue" SG_ 311 Failed_PowerDeliverNotApplied "null";
BA_ "GenSigSendType" SG_ 311 Failed_TarrifSelectionInvalid 7;
BA_ "GenSigTimeoutTime_ALL" SG_ 311 Failed_TarrifSelectionInvalid 500;
BA_ "InvalidValue" SG_ 311 Failed_TarrifSelectionInvalid "null";
BA_ "GenSigSendType" SG_ 311 Failed_ChargingProfileInvalid 7;
BA_ "GenSigTimeoutTime_ALL" SG_ 311 Failed_ChargingProfileInvalid 500;
BA_ "InvalidValue" SG_ 311 Failed_ChargingProfileInvalid "null";
BA_ "GenSigSendType" SG_ 311 Error_message_4 7;
BA_ "GenSigTimeoutTime_ALL" SG_ 311 Error_message_4 500;
BA_ "InvalidValue" SG_ 311 Error_message_4 "null";
BA_ "GenSigSendType" SG_ 311 Error_message_3 7;
BA_ "GenSigTimeoutTime_ALL" SG_ 311 Error_message_3 500;
BA_ "InvalidValue" SG_ 311 Error_message_3 "null";
BA_ "GenSigSendType" SG_ 311 Error_message_1 7;
BA_ "GenSigTimeoutTime_ALL" SG_ 311 Error_message_1 500;
BA_ "InvalidValue" SG_ 311 Error_message_1 "null";
BA_ "GenSigSendType" SG_ 311 Error_message_2 7;
BA_ "GenSigTimeoutTime_ALL" SG_ 311 Error_message_2 500;
BA_ "InvalidValue" SG_ 311 Error_message_2 "null";
BA_ "GenSigSendType" SG_ 311 PnC_ChargeSessionEnded 7;
BA_ "GenSigTimeoutTime_ALL" SG_ 311 PnC_ChargeSessionEnded 500;
BA_ "InvalidValue" SG_ 311 PnC_ChargeSessionEnded "null";
BA_ "GenSigSendType" SG_ 311 PnC_Status 7;
BA_ "GenSigTimeoutTime_ALL" SG_ 311 PnC_Status 500;
BA_ "InvalidValue" SG_ 311 PnC_Status "null";
BA_ "GenSigSendType" SG_ 311 PnC_Contract_Status 7;
BA_ "GenSigStartValue" SG_ 311 PnC_Contract_Status 1;
BA_ "GenSigTimeoutTime_ALL" SG_ 311 PnC_Contract_Status 500;
BA_ "InvalidValue" SG_ 311 PnC_Contract_Status "null";
BA_ "GenSigSendType" SG_ 311 Error_message_5 7;
BA_ "GenSigTimeoutTime_ALL" SG_ 311 Error_message_5 500;
BA_ "InvalidValue" SG_ 311 Error_message_5 "null";
BA_ "GenSigTimeoutTime_ALL" SG_ 316 CRC_FCAM_VCU_ACC_Status 200;
BA_ "InvalidValue" SG_ 316 Alive_FCAM_VCU_ACC_Status "Fh";
BA_ "GenSigTimeoutTime_ALL" SG_ 316 Alive_FCAM_VCU_ACC_Status 200;
BA_ "GenSigTimeoutTime_ALL" SG_ 316 FCAM_ACC_Mode_VCU 200;
BA_ "GenSigTimeoutTime_ALL" SG_ 316 SECCAN_FCAM_VCU_ACC_Status 200;
BA_ "GenSigSendType" SG_ 317 SessionPaymentType 7;
BA_ "GenSigTimeoutTime_ALL" SG_ 317 SessionPaymentType 500;
BA_ "InvalidValue" SG_ 317 SessionPaymentType "";
BA_ "GenSigTimeoutTime_ALL" SG_ 338 CHSKM_EDS_FS_FR 200;
BA_ "GenSigTimeoutTime_ALL" SG_ 338 ALV_EDS_FS_FR 200;
BA_ "InvalidValue" SG_ 338 ALV_EDS_FS_FR "Fh";
BA_ "GenSigTimeoutTime_ALL" SG_ 338 EDS_FuSa_error_FR 200;
BA_ "GenSigTimeoutTime_ALL" SG_ 338 EDS_shutoffpath_error_FR 200;
BA_ "InvalidValue" SG_ 338 EDS_shutoffpath_error_FR "";
BA_ "GenSigTimeoutTime_ALL" SG_ 338 EDS_EDSDisChgFault_FWD 200;
BA_ "InvalidValue" SG_ 338 EDS_EDSDisChgFault_FWD "";
BA_ "GenSigTimeoutTime_ALL" SG_ 339 CHSKM_EDS_FS_RR 200;
BA_ "GenSigTimeoutTime_ALL" SG_ 339 ALV_EDS_FS_RR 200;
BA_ "InvalidValue" SG_ 339 ALV_EDS_FS_RR "Fh";
BA_ "GenSigTimeoutTime_ALL" SG_ 339 EDS_FuSa_error_RR 200;
BA_ "GenSigTimeoutTime_ALL" SG_ 339 EDS_shutoffpath_error_RR 200;
BA_ "InvalidValue" SG_ 339 EDS_shutoffpath_error_RR "";
BA_ "GenSigTimeoutTime_ALL" SG_ 339 EDS_EDSDisChgFault_RWD 200;
BA_ "InvalidValue" SG_ 339 EDS_EDSDisChgFault_RWD "";
BA_ "GenSigTimeoutTime_ALL" SG_ 357 CHSKM_VCU_ChargingConnection 200;
BA_ "InvalidValue" SG_ 357 CHSKM_VCU_ChargingConnection "";
BA_ "GenSigTimeoutTime_ALL" SG_ 357 ALV_VCU_ChargingConnection 200;
BA_ "InvalidValue" SG_ 357 ALV_VCU_ChargingConnection "Fh";
BA_ "GenSigTimeoutTime_ALL" SG_ 357 VCU_AcChgGunIn 200;
BA_ "InvalidValue" SG_ 357 VCU_AcChgGunIn "";
BA_ "GenSigTimeoutTime_ALL" SG_ 357 VCU_DCChgGunIn 200;
BA_ "InvalidValue" SG_ 357 VCU_DCChgGunIn "";
BA_ "GenSigTimeoutTime_ALL" SG_ 357 VCU_CPValue 200;
BA_ "GenSigStartValue" SG_ 357 VCU_ACChargingVoltage 1;
BA_ "GenSigTimeoutTime_ALL" SG_ 357 VCU_ACChargingVoltage 200;
BA_ "InvalidValue" SG_ 357 VCU_ACChargingVoltage "Fh";
BA_ "GenSigStartValue" SG_ 357 VCU_MinCurrentOfACCharging 1;
BA_ "GenSigTimeoutTime_ALL" SG_ 357 VCU_MinCurrentOfACCharging 200;
BA_ "InvalidValue" SG_ 357 VCU_MinCurrentOfACCharging "7h";
BA_ "GenSigTimeoutTime_ALL" SG_ 357 VCU_MaxCurrentOfACCharging 200;
BA_ "InvalidValue" SG_ 357 VCU_MaxCurrentOfACCharging "3Fh";
BA_ "GenSigSendType" SG_ 359 TWV1_N_Position 7;
BA_ "InvalidValue" SG_ 359 TWV1_N_Position "";
BA_ "GenSigSendType" SG_ 359 TWV1_St_Feedback 7;
BA_ "InvalidValue" SG_ 359 TWV1_St_Feedback "";
BA_ "GenSigSendType" SG_ 359 TWV1_Frm_Error 7;
BA_ "InvalidValue" SG_ 359 TWV1_Frm_Error "";
BA_ "GenSigTimeoutTime_ALL" SG_ 372 CHSKM_BMS_CurMeas 100;
BA_ "InvalidValue" SG_ 372 CHSKM_BMS_CurMeas "";
BA_ "GenSigTimeoutTime_ALL" SG_ 372 ALV_BMS_CurMeas 100;
BA_ "InvalidValue" SG_ 372 ALV_BMS_CurMeas "Fh";
BA_ "GenSigStartValue" SG_ 372 BMS_PackCur_MEAS 32768;
BA_ "GenSigTimeoutTime_ALL" SG_ 372 BMS_PackCur_MEAS 100;
BA_ "InvalidValue" SG_ 372 BMS_PackCur_MEAS "FFFFh";
BA_ "GenSigTimeoutTime_ALL" SG_ 374 Checksum_0x176 200;
BA_ "InvalidValue" SG_ 374 Checksum_0x176 "";
BA_ "GenSigTimeoutTime_ALL" SG_ 374 Rolling_Counter_0x176 200;
BA_ "InvalidValue" SG_ 374 Rolling_Counter_0x176 "Fh";
BA_ "GenSigTimeoutTime_ALL" SG_ 374 BMS_HVPackVol_MEAS 200;
BA_ "InvalidValue" SG_ 374 BMS_HVPackVol_MEAS "FFFFh";
BA_ "GenSigTimeoutTime_ALL" SG_ 374 BMS_HVLinkVol_MEAS 200;
BA_ "InvalidValue" SG_ 374 BMS_HVLinkVol_MEAS "FFFFh";
BA_ "GenSigTimeoutTime_ALL" SG_ 376 CHKSM_YSS_LongAcc 100;
BA_ "InvalidValue" SG_ 376 CHKSM_YSS_LongAcc "";
BA_ "GenSigTimeoutTime_ALL" SG_ 376 ALV_YSS_LongAcc 100;
BA_ "InvalidValue" SG_ 376 ALV_YSS_LongAcc "Fh";
BA_ "GenSigTimeoutTime_ALL" SG_ 376 YSS_LONG_ACCUNFILTERED_QUAL 100;
BA_ "GenSigTimeoutTime_ALL" SG_ 376 YSS_LONG_ACC_UNFILTERED 100;
BA_ "InvalidValue" SG_ 376 YSS_LONG_ACC_UNFILTERED "FFFFh";
BA_ "GenSigTimeoutTime_ALL" SG_ 376 YSS_LONG_ACC_QUAL 100;
BA_ "GenSigTimeoutTime_ALL" SG_ 376 YSS_LONG_ACC 100;
BA_ "InvalidValue" SG_ 376 YSS_LONG_ACC "FFFFh";
BA_ "GenSigTimeoutTime_ALL" SG_ 377 CHKSM_YSS_LateralAcc 100;
BA_ "InvalidValue" SG_ 377 CHKSM_YSS_LateralAcc "";
BA_ "GenSigTimeoutTime_ALL" SG_ 377 ALV_YSS_LateralAcc 100;
BA_ "InvalidValue" SG_ 377 ALV_YSS_LateralAcc "Fh";
BA_ "GenSigTimeoutTime_ALL" SG_ 377 YSS_LAT_ACCUNFILTERED_QUAL 100;
BA_ "GenSigTimeoutTime_ALL" SG_ 377 YSS_LAT_ACC_UNFILTERED 100;
BA_ "InvalidValue" SG_ 377 YSS_LAT_ACC_UNFILTERED "FFFh";
BA_ "GenSigTimeoutTime_ALL" SG_ 377 YSS_LAT_ACC_QUAL 100;
BA_ "GenSigTimeoutTime_ALL" SG_ 377 YSS_LAT_ACC 100;
BA_ "InvalidValue" SG_ 377 YSS_LAT_ACC "FFFFh";
BA_ "GenSigTimeoutTime_ALL" SG_ 381 CHKSM_YSS_YawRate 100;
BA_ "InvalidValue" SG_ 381 CHKSM_YSS_YawRate "";
BA_ "GenSigTimeoutTime_ALL" SG_ 381 ALV_YSS_YawRate 100;
BA_ "InvalidValue" SG_ 381 ALV_YSS_YawRate "Fh";
BA_ "GenSigTimeoutTime_ALL" SG_ 381 YSS_YAW_RATEUNFILTERED_QUAL 100;
BA_ "GenSigTimeoutTime_ALL" SG_ 381 YSS_YAW_RATE_UNFILTERED 100;
BA_ "InvalidValue" SG_ 381 YSS_YAW_RATE_UNFILTERED "FFFh";
BA_ "GenSigTimeoutTime_ALL" SG_ 381 YSS_YAW_RATE_QUAL 100;
BA_ "GenSigTimeoutTime_ALL" SG_ 381 YSS_SC_STATUS 100;
BA_ "InvalidValue" SG_ 381 YSS_SC_STATUS "";
BA_ "GenSigTimeoutTime_ALL" SG_ 381 YSS_YAW_RATE 100;
BA_ "InvalidValue" SG_ 381 YSS_YAW_RATE "FFFFh";
BA_ "GenSigStartValue" SG_ 381 YSS_TEMPERATURE 40;
BA_ "GenSigTimeoutTime_ALL" SG_ 381 YSS_TEMPERATURE 100;
BA_ "InvalidValue" SG_ 381 YSS_TEMPERATURE "FFh";
BA_ "GenSigTimeoutTime_ALL" SG_ 384 CHKSM_EPS2_SAS_Sensor 100;
BA_ "InvalidValue" SG_ 384 CHKSM_EPS2_SAS_Sensor "";
BA_ "GenSigTimeoutTime_ALL" SG_ 384 ALV_EPS2_SAS_Sensor 100;
BA_ "InvalidValue" SG_ 384 ALV_EPS2_SAS_Sensor "Fh";
BA_ "GenSigTimeoutTime_ALL" SG_ 384 EPS2_SAS_SASStsSnsr 100;
BA_ "InvalidValue" SG_ 384 EPS2_SAS_SASStsSnsr "";
BA_ "GenSigStartValue" SG_ 384 EPS2_SAS_SteerWhlRotSpd 8192;
BA_ "GenSigTimeoutTime_ALL" SG_ 384 EPS2_SAS_SteerWhlRotSpd 100;
BA_ "InvalidValue" SG_ 384 EPS2_SAS_SteerWhlRotSpd "3FFFh";
BA_ "GenSigTimeoutTime_ALL" SG_ 384 EPS2_SAS_SteerWhlRotSpdStatus 100;
BA_ "InvalidValue" SG_ 384 EPS2_SAS_SteerWhlRotSpdStatus "";
BA_ "GenSigTimeoutTime_ALL" SG_ 384 EPS2_SAS_SASFailure 100;
BA_ "InvalidValue" SG_ 384 EPS2_SAS_SASFailure "";
BA_ "GenSigTimeoutTime_ALL" SG_ 384 EPS2_SAS_Calibrated 100;
BA_ "InvalidValue" SG_ 384 EPS2_SAS_Calibrated "";
BA_ "GenSigTimeoutTime_ALL" SG_ 384 EPS2_SAS_SteerWheelAngleValid 100;
BA_ "InvalidValue" SG_ 384 EPS2_SAS_SteerWheelAngleValid "3h";
BA_ "GenSigStartValue" SG_ 384 EPS2_SAS_SteerWheelAngle 32773;
BA_ "GenSigTimeoutTime_ALL" SG_ 384 EPS2_SAS_SteerWheelAngle 100;
BA_ "InvalidValue" SG_ 384 EPS2_SAS_SteerWheelAngle "FFFFh";
BA_ "GenSigTimeoutTime_ALL" SG_ 385 VCU_Debug1 500;
BA_ "InvalidValue" SG_ 385 VCU_Debug1 "";
BA_ "GenSigTimeoutTime_ALL" SG_ 385 VCU_Debug2 500;
BA_ "InvalidValue" SG_ 385 VCU_Debug2 "";
BA_ "GenSigTimeoutTime_ALL" SG_ 385 VCU_Debug3 500;
BA_ "InvalidValue" SG_ 385 VCU_Debug3 "";
BA_ "GenSigTimeoutTime_ALL" SG_ 385 VCU_Debug4 500;
BA_ "InvalidValue" SG_ 385 VCU_Debug4 "";
BA_ "GenSigTimeoutTime_ALL" SG_ 386 VCU_FS_A_1 1000;
BA_ "InvalidValue" SG_ 386 VCU_FS_A_1 "1h";
BA_ "GenSigTimeoutTime_ALL" SG_ 386 VCU_FS_A_2 1000;
BA_ "InvalidValue" SG_ 386 VCU_FS_A_2 "1h";
BA_ "GenSigTimeoutTime_ALL" SG_ 386 VCU_FS_A_3 1000;
BA_ "InvalidValue" SG_ 386 VCU_FS_A_3 "1h";
BA_ "GenSigTimeoutTime_ALL" SG_ 386 VCU_FS_A_4 1000;
BA_ "InvalidValue" SG_ 386 VCU_FS_A_4 "1h";
BA_ "GenSigTimeoutTime_ALL" SG_ 386 VCU_FS_A_5 1000;
BA_ "InvalidValue" SG_ 386 VCU_FS_A_5 "1h";
BA_ "GenSigTimeoutTime_ALL" SG_ 386 VCU_FS_A_6 1000;
BA_ "InvalidValue" SG_ 386 VCU_FS_A_6 "1h";
BA_ "GenSigTimeoutTime_ALL" SG_ 386 VCU_FS_A_7 1000;
BA_ "InvalidValue" SG_ 386 VCU_FS_A_7 "1h";
BA_ "GenSigTimeoutTime_ALL" SG_ 386 VCU_FS_A_8 1000;
BA_ "InvalidValue" SG_ 386 VCU_FS_A_8 "1h";
BA_ "GenSigTimeoutTime_ALL" SG_ 386 VCU_FS_A_9 1000;
BA_ "InvalidValue" SG_ 386 VCU_FS_A_9 "1h";
BA_ "GenSigTimeoutTime_ALL" SG_ 386 VCU_FS_A_10 1000;
BA_ "InvalidValue" SG_ 386 VCU_FS_A_10 "1h";
BA_ "GenSigTimeoutTime_ALL" SG_ 386 VCU_FS_A_11 1000;
BA_ "InvalidValue" SG_ 386 VCU_FS_A_11 "1h";
BA_ "GenSigTimeoutTime_ALL" SG_ 386 VCU_FS_A_12 1000;
BA_ "InvalidValue" SG_ 386 VCU_FS_A_12 "1h";
BA_ "GenSigTimeoutTime_ALL" SG_ 386 VCU_FS_A_13 1000;
BA_ "InvalidValue" SG_ 386 VCU_FS_A_13 "1h";
BA_ "GenSigTimeoutTime_ALL" SG_ 386 VCU_FS_A_14 1000;
BA_ "InvalidValue" SG_ 386 VCU_FS_A_14 "1h";
BA_ "GenSigTimeoutTime_ALL" SG_ 386 VCU_FS_A_15 1000;
BA_ "InvalidValue" SG_ 386 VCU_FS_A_15 "1h";
BA_ "GenSigTimeoutTime_ALL" SG_ 386 VCU_FS_A_16 1000;
BA_ "InvalidValue" SG_ 386 VCU_FS_A_16 "1h";
BA_ "GenSigTimeoutTime_ALL" SG_ 386 VCU_FS_A_17 1000;
BA_ "InvalidValue" SG_ 386 VCU_FS_A_17 "1h";
BA_ "GenSigTimeoutTime_ALL" SG_ 386 VCU_FS_A_18 1000;
BA_ "InvalidValue" SG_ 386 VCU_FS_A_18 "1h";
BA_ "GenSigTimeoutTime_ALL" SG_ 386 VCU_FS_A_19 1000;
BA_ "InvalidValue" SG_ 386 VCU_FS_A_19 "1h";
BA_ "GenSigTimeoutTime_ALL" SG_ 386 VCU_FS_A_20 1000;
BA_ "InvalidValue" SG_ 386 VCU_FS_A_20 "1h";
BA_ "GenSigTimeoutTime_ALL" SG_ 386 VCU_FS_A_21 1000;
BA_ "InvalidValue" SG_ 386 VCU_FS_A_21 "1h";
BA_ "GenSigTimeoutTime_ALL" SG_ 386 VCU_FS_A_22 1000;
BA_ "InvalidValue" SG_ 386 VCU_FS_A_22 "1h";
BA_ "GenSigTimeoutTime_ALL" SG_ 386 VCU_FS_A_23 1000;
BA_ "InvalidValue" SG_ 386 VCU_FS_A_23 "1h";
BA_ "GenSigTimeoutTime_ALL" SG_ 386 VCU_FS_A_24 1000;
BA_ "InvalidValue" SG_ 386 VCU_FS_A_24 "1h";
BA_ "GenSigTimeoutTime_ALL" SG_ 386 VCU_FS_A_25 1000;
BA_ "InvalidValue" SG_ 386 VCU_FS_A_25 "1h";
BA_ "GenSigTimeoutTime_ALL" SG_ 386 VCU_FS_A_26 1000;
BA_ "InvalidValue" SG_ 386 VCU_FS_A_26 "1h";
BA_ "GenSigTimeoutTime_ALL" SG_ 386 VCU_FS_A_27 1000;
BA_ "InvalidValue" SG_ 386 VCU_FS_A_27 "1h";
BA_ "GenSigTimeoutTime_ALL" SG_ 386 VCU_FS_A_28 1000;
BA_ "InvalidValue" SG_ 386 VCU_FS_A_28 "1h";
BA_ "GenSigTimeoutTime_ALL" SG_ 386 VCU_FS_A_29 1000;
BA_ "InvalidValue" SG_ 386 VCU_FS_A_29 "1h";
BA_ "GenSigTimeoutTime_ALL" SG_ 386 VCU_FS_A_30 1000;
BA_ "InvalidValue" SG_ 386 VCU_FS_A_30 "1h";
BA_ "GenSigTimeoutTime_ALL" SG_ 386 VCU_FS_A_31 1000;
BA_ "InvalidValue" SG_ 386 VCU_FS_A_31 "1h";
BA_ "GenSigTimeoutTime_ALL" SG_ 386 VCU_FS_A_32 1000;
BA_ "InvalidValue" SG_ 386 VCU_FS_A_32 "1h";
BA_ "GenSigTimeoutTime_ALL" SG_ 386 VCU_FS_A_33 1000;
BA_ "InvalidValue" SG_ 386 VCU_FS_A_33 "1h";
BA_ "GenSigTimeoutTime_ALL" SG_ 386 VCU_FS_A_34 1000;
BA_ "InvalidValue" SG_ 386 VCU_FS_A_34 "1h";
BA_ "GenSigTimeoutTime_ALL" SG_ 386 VCU_FS_A_35 1000;
BA_ "InvalidValue" SG_ 386 VCU_FS_A_35 "1h";
BA_ "GenSigTimeoutTime_ALL" SG_ 386 VCU_FS_A_36 1000;
BA_ "InvalidValue" SG_ 386 VCU_FS_A_36 "1h";
BA_ "GenSigTimeoutTime_ALL" SG_ 386 VCU_FS_A_37 1000;
BA_ "InvalidValue" SG_ 386 VCU_FS_A_37 "1h";
BA_ "GenSigTimeoutTime_ALL" SG_ 386 VCU_FS_A_38 1000;
BA_ "InvalidValue" SG_ 386 VCU_FS_A_38 "1h";
BA_ "GenSigTimeoutTime_ALL" SG_ 386 VCU_FS_A_39 1000;
BA_ "InvalidValue" SG_ 386 VCU_FS_A_39 "1h";
BA_ "GenSigTimeoutTime_ALL" SG_ 386 VCU_FS_A_40 1000;
BA_ "InvalidValue" SG_ 386 VCU_FS_A_40 "1h";
BA_ "GenSigTimeoutTime_ALL" SG_ 386 VCU_FS_A_41 1000;
BA_ "InvalidValue" SG_ 386 VCU_FS_A_41 "1h";
BA_ "GenSigTimeoutTime_ALL" SG_ 386 VCU_FS_A_42 1000;
BA_ "InvalidValue" SG_ 386 VCU_FS_A_42 "1h";
BA_ "GenSigTimeoutTime_ALL" SG_ 386 VCU_FS_A_43 1000;
BA_ "InvalidValue" SG_ 386 VCU_FS_A_43 "1h";
BA_ "GenSigTimeoutTime_ALL" SG_ 386 VCU_FS_A_44 1000;
BA_ "InvalidValue" SG_ 386 VCU_FS_A_44 "1h";
BA_ "GenSigTimeoutTime_ALL" SG_ 386 VCU_FS_A_45 1000;
BA_ "InvalidValue" SG_ 386 VCU_FS_A_45 "1h";
BA_ "GenSigTimeoutTime_ALL" SG_ 386 VCU_FS_A_46 1000;
BA_ "InvalidValue" SG_ 386 VCU_FS_A_46 "1h";
BA_ "GenSigTimeoutTime_ALL" SG_ 386 VCU_FS_A_47 1000;
BA_ "InvalidValue" SG_ 386 VCU_FS_A_47 "1h";
BA_ "GenSigTimeoutTime_ALL" SG_ 386 VCU_FS_A_48 1000;
BA_ "InvalidValue" SG_ 386 VCU_FS_A_48 "1h";
BA_ "GenSigTimeoutTime_ALL" SG_ 386 VCU_FS_A_49 1000;
BA_ "InvalidValue" SG_ 386 VCU_FS_A_49 "1h";
BA_ "GenSigTimeoutTime_ALL" SG_ 386 VCU_FS_A_50 1000;
BA_ "InvalidValue" SG_ 386 VCU_FS_A_50 "1h";
BA_ "GenSigTimeoutTime_ALL" SG_ 386 VCU_FS_A_51 1000;
BA_ "InvalidValue" SG_ 386 VCU_FS_A_51 "1h";
BA_ "GenSigTimeoutTime_ALL" SG_ 386 VCU_FS_A_52 1000;
BA_ "InvalidValue" SG_ 386 VCU_FS_A_52 "1h";
BA_ "GenSigTimeoutTime_ALL" SG_ 386 VCU_FS_A_53 1000;
BA_ "InvalidValue" SG_ 386 VCU_FS_A_53 "1h";
BA_ "GenSigTimeoutTime_ALL" SG_ 386 VCU_FS_A_54 1000;
BA_ "InvalidValue" SG_ 386 VCU_FS_A_54 "1h";
BA_ "GenSigTimeoutTime_ALL" SG_ 386 VCU_FS_A_55 1000;
BA_ "InvalidValue" SG_ 386 VCU_FS_A_55 "1h";
BA_ "GenSigTimeoutTime_ALL" SG_ 386 VCU_FS_A_56 1000;
BA_ "InvalidValue" SG_ 386 VCU_FS_A_56 "1h";
BA_ "GenSigTimeoutTime_ALL" SG_ 386 VCU_FS_A_57 1000;
BA_ "InvalidValue" SG_ 386 VCU_FS_A_57 "1h";
BA_ "GenSigTimeoutTime_ALL" SG_ 386 VCU_FS_A_58 1000;
BA_ "InvalidValue" SG_ 386 VCU_FS_A_58 "1h";
BA_ "GenSigTimeoutTime_ALL" SG_ 386 VCU_FS_A_59 1000;
BA_ "InvalidValue" SG_ 386 VCU_FS_A_59 "1h";
BA_ "GenSigTimeoutTime_ALL" SG_ 386 VCU_FS_A_60 1000;
BA_ "InvalidValue" SG_ 386 VCU_FS_A_60 "1h";
BA_ "GenSigTimeoutTime_ALL" SG_ 386 VCU_FS_A_61 1000;
BA_ "InvalidValue" SG_ 386 VCU_FS_A_61 "1h";
BA_ "GenSigTimeoutTime_ALL" SG_ 386 VCU_FS_A_62 1000;
BA_ "InvalidValue" SG_ 386 VCU_FS_A_62 "1h";
BA_ "GenSigTimeoutTime_ALL" SG_ 386 VCU_FS_A_63 1000;
BA_ "InvalidValue" SG_ 386 VCU_FS_A_63 "1h";
BA_ "GenSigTimeoutTime_ALL" SG_ 386 VCU_FS_A_64 1000;
BA_ "InvalidValue" SG_ 386 VCU_FS_A_64 "1h";
BA_ "GenSigTimeoutTime_ALL" SG_ 387 VCU_FS_B_1 1000;
BA_ "InvalidValue" SG_ 387 VCU_FS_B_1 "1h";
BA_ "GenSigTimeoutTime_ALL" SG_ 387 VCU_FS_B_2 1000;
BA_ "InvalidValue" SG_ 387 VCU_FS_B_2 "1h";
BA_ "GenSigTimeoutTime_ALL" SG_ 387 VCU_FS_B_3 1000;
BA_ "InvalidValue" SG_ 387 VCU_FS_B_3 "1h";
BA_ "GenSigTimeoutTime_ALL" SG_ 387 VCU_FS_B_4 1000;
BA_ "InvalidValue" SG_ 387 VCU_FS_B_4 "1h";
BA_ "GenSigTimeoutTime_ALL" SG_ 387 VCU_FS_B_5 1000;
BA_ "InvalidValue" SG_ 387 VCU_FS_B_5 "1h";
BA_ "GenSigTimeoutTime_ALL" SG_ 387 VCU_FS_B_6 1000;
BA_ "InvalidValue" SG_ 387 VCU_FS_B_6 "1h";
BA_ "GenSigTimeoutTime_ALL" SG_ 387 VCU_FS_B_7 1000;
BA_ "InvalidValue" SG_ 387 VCU_FS_B_7 "1h";
BA_ "GenSigTimeoutTime_ALL" SG_ 387 VCU_FS_B_8 1000;
BA_ "InvalidValue" SG_ 387 VCU_FS_B_8 "1h";
BA_ "GenSigTimeoutTime_ALL" SG_ 387 VCU_FS_B_9 1000;
BA_ "InvalidValue" SG_ 387 VCU_FS_B_9 "1h";
BA_ "GenSigTimeoutTime_ALL" SG_ 387 VCU_FS_B_10 1000;
BA_ "InvalidValue" SG_ 387 VCU_FS_B_10 "1h";
BA_ "GenSigTimeoutTime_ALL" SG_ 387 VCU_FS_B_11 1000;
BA_ "InvalidValue" SG_ 387 VCU_FS_B_11 "1h";
BA_ "GenSigTimeoutTime_ALL" SG_ 387 VCU_FS_B_12 1000;
BA_ "InvalidValue" SG_ 387 VCU_FS_B_12 "1h";
BA_ "GenSigTimeoutTime_ALL" SG_ 387 VCU_FS_B_13 1000;
BA_ "InvalidValue" SG_ 387 VCU_FS_B_13 "1h";
BA_ "GenSigTimeoutTime_ALL" SG_ 387 VCU_FS_B_14 1000;
BA_ "InvalidValue" SG_ 387 VCU_FS_B_14 "1h";
BA_ "GenSigTimeoutTime_ALL" SG_ 387 VCU_FS_B_15 1000;
BA_ "InvalidValue" SG_ 387 VCU_FS_B_15 "1h";
BA_ "GenSigTimeoutTime_ALL" SG_ 387 VCU_FS_B_16 1000;
BA_ "InvalidValue" SG_ 387 VCU_FS_B_16 "1h";
BA_ "GenSigTimeoutTime_ALL" SG_ 387 VCU_FS_B_17 1000;
BA_ "InvalidValue" SG_ 387 VCU_FS_B_17 "1h";
BA_ "GenSigTimeoutTime_ALL" SG_ 387 VCU_FS_B_18 1000;
BA_ "InvalidValue" SG_ 387 VCU_FS_B_18 "1h";
BA_ "GenSigTimeoutTime_ALL" SG_ 387 VCU_FS_B_19 1000;
BA_ "InvalidValue" SG_ 387 VCU_FS_B_19 "1h";
BA_ "GenSigTimeoutTime_ALL" SG_ 387 VCU_FS_B_20 1000;
BA_ "InvalidValue" SG_ 387 VCU_FS_B_20 "1h";
BA_ "GenSigTimeoutTime_ALL" SG_ 387 VCU_FS_B_21 1000;
BA_ "InvalidValue" SG_ 387 VCU_FS_B_21 "1h";
BA_ "GenSigTimeoutTime_ALL" SG_ 387 VCU_FS_B_22 1000;
BA_ "InvalidValue" SG_ 387 VCU_FS_B_22 "1h";
BA_ "GenSigTimeoutTime_ALL" SG_ 387 VCU_FS_B_23 1000;
BA_ "InvalidValue" SG_ 387 VCU_FS_B_23 "1h";
BA_ "GenSigTimeoutTime_ALL" SG_ 387 VCU_FS_B_24 1000;
BA_ "InvalidValue" SG_ 387 VCU_FS_B_24 "1h";
BA_ "GenSigTimeoutTime_ALL" SG_ 387 VCU_FS_B_25 1000;
BA_ "InvalidValue" SG_ 387 VCU_FS_B_25 "1h";
BA_ "GenSigTimeoutTime_ALL" SG_ 387 VCU_FS_B_26 1000;
BA_ "InvalidValue" SG_ 387 VCU_FS_B_26 "1h";
BA_ "GenSigTimeoutTime_ALL" SG_ 387 VCU_FS_B_27 1000;
BA_ "InvalidValue" SG_ 387 VCU_FS_B_27 "1h";
BA_ "GenSigTimeoutTime_ALL" SG_ 387 VCU_FS_B_28 1000;
BA_ "InvalidValue" SG_ 387 VCU_FS_B_28 "1h";
BA_ "GenSigTimeoutTime_ALL" SG_ 387 VCU_FS_B_29 1000;
BA_ "InvalidValue" SG_ 387 VCU_FS_B_29 "1h";
BA_ "GenSigTimeoutTime_ALL" SG_ 387 VCU_FS_B_30 1000;
BA_ "InvalidValue" SG_ 387 VCU_FS_B_30 "1h";
BA_ "GenSigTimeoutTime_ALL" SG_ 387 VCU_FS_B_31 1000;
BA_ "InvalidValue" SG_ 387 VCU_FS_B_31 "1h";
BA_ "GenSigTimeoutTime_ALL" SG_ 387 VCU_FS_B_32 1000;
BA_ "InvalidValue" SG_ 387 VCU_FS_B_32 "1h";
BA_ "GenSigTimeoutTime_ALL" SG_ 387 VCU_FS_B_33 1000;
BA_ "InvalidValue" SG_ 387 VCU_FS_B_33 "1h";
BA_ "GenSigTimeoutTime_ALL" SG_ 387 VCU_FS_B_34 1000;
BA_ "InvalidValue" SG_ 387 VCU_FS_B_34 "1h";
BA_ "GenSigTimeoutTime_ALL" SG_ 387 VCU_FS_B_35 1000;
BA_ "InvalidValue" SG_ 387 VCU_FS_B_35 "1h";
BA_ "GenSigTimeoutTime_ALL" SG_ 387 VCU_FS_B_36 1000;
BA_ "InvalidValue" SG_ 387 VCU_FS_B_36 "1h";
BA_ "GenSigTimeoutTime_ALL" SG_ 387 VCU_FS_B_37 1000;
BA_ "InvalidValue" SG_ 387 VCU_FS_B_37 "1h";
BA_ "GenSigTimeoutTime_ALL" SG_ 387 VCU_FS_B_38 1000;
BA_ "InvalidValue" SG_ 387 VCU_FS_B_38 "1h";
BA_ "GenSigTimeoutTime_ALL" SG_ 387 VCU_FS_B_39 1000;
BA_ "InvalidValue" SG_ 387 VCU_FS_B_39 "1h";
BA_ "GenSigTimeoutTime_ALL" SG_ 387 VCU_FS_B_40 1000;
BA_ "InvalidValue" SG_ 387 VCU_FS_B_40 "1h";
BA_ "GenSigTimeoutTime_ALL" SG_ 387 VCU_FS_B_41 1000;
BA_ "InvalidValue" SG_ 387 VCU_FS_B_41 "1h";
BA_ "GenSigTimeoutTime_ALL" SG_ 387 VCU_FS_B_42 1000;
BA_ "InvalidValue" SG_ 387 VCU_FS_B_42 "1h";
BA_ "GenSigTimeoutTime_ALL" SG_ 387 VCU_FS_B_43 1000;
BA_ "InvalidValue" SG_ 387 VCU_FS_B_43 "1h";
BA_ "GenSigTimeoutTime_ALL" SG_ 387 VCU_FS_B_44 1000;
BA_ "InvalidValue" SG_ 387 VCU_FS_B_44 "1h";
BA_ "GenSigTimeoutTime_ALL" SG_ 387 VCU_FS_B_45 1000;
BA_ "InvalidValue" SG_ 387 VCU_FS_B_45 "1h";
BA_ "GenSigTimeoutTime_ALL" SG_ 387 VCU_FS_B_46 1000;
BA_ "InvalidValue" SG_ 387 VCU_FS_B_46 "1h";
BA_ "GenSigTimeoutTime_ALL" SG_ 387 VCU_FS_B_47 1000;
BA_ "InvalidValue" SG_ 387 VCU_FS_B_47 "1h";
BA_ "GenSigTimeoutTime_ALL" SG_ 387 VCU_FS_B_48 1000;
BA_ "InvalidValue" SG_ 387 VCU_FS_B_48 "1h";
BA_ "GenSigTimeoutTime_ALL" SG_ 387 VCU_FS_B_49 1000;
BA_ "InvalidValue" SG_ 387 VCU_FS_B_49 "1h";
BA_ "GenSigTimeoutTime_ALL" SG_ 387 VCU_FS_B_50 1000;
BA_ "InvalidValue" SG_ 387 VCU_FS_B_50 "1h";
BA_ "GenSigTimeoutTime_ALL" SG_ 387 VCU_FS_B_51 1000;
BA_ "InvalidValue" SG_ 387 VCU_FS_B_51 "1h";
BA_ "GenSigTimeoutTime_ALL" SG_ 387 VCU_FS_B_52 1000;
BA_ "InvalidValue" SG_ 387 VCU_FS_B_52 "1h";
BA_ "GenSigTimeoutTime_ALL" SG_ 387 VCU_FS_B_53 1000;
BA_ "InvalidValue" SG_ 387 VCU_FS_B_53 "1h";
BA_ "GenSigTimeoutTime_ALL" SG_ 387 VCU_FS_B_54 1000;
BA_ "InvalidValue" SG_ 387 VCU_FS_B_54 "1h";
BA_ "GenSigTimeoutTime_ALL" SG_ 387 VCU_FS_B_55 1000;
BA_ "InvalidValue" SG_ 387 VCU_FS_B_55 "1h";
BA_ "GenSigTimeoutTime_ALL" SG_ 387 VCU_FS_B_56 1000;
BA_ "InvalidValue" SG_ 387 VCU_FS_B_56 "1h";
BA_ "GenSigTimeoutTime_ALL" SG_ 387 VCU_FS_B_57 1000;
BA_ "InvalidValue" SG_ 387 VCU_FS_B_57 "1h";
BA_ "GenSigTimeoutTime_ALL" SG_ 387 VCU_FS_B_58 1000;
BA_ "InvalidValue" SG_ 387 VCU_FS_B_58 "1h";
BA_ "GenSigTimeoutTime_ALL" SG_ 387 VCU_FS_B_59 1000;
BA_ "InvalidValue" SG_ 387 VCU_FS_B_59 "1h";
BA_ "GenSigTimeoutTime_ALL" SG_ 387 VCU_FS_B_60 1000;
BA_ "InvalidValue" SG_ 387 VCU_FS_B_60 "1h";
BA_ "GenSigTimeoutTime_ALL" SG_ 387 VCU_FS_B_61 1000;
BA_ "InvalidValue" SG_ 387 VCU_FS_B_61 "1h";
BA_ "GenSigTimeoutTime_ALL" SG_ 387 VCU_FS_B_62 1000;
BA_ "InvalidValue" SG_ 387 VCU_FS_B_62 "1h";
BA_ "GenSigTimeoutTime_ALL" SG_ 387 VCU_FS_B_63 1000;
BA_ "InvalidValue" SG_ 387 VCU_FS_B_63 "1h";
BA_ "GenSigTimeoutTime_ALL" SG_ 387 VCU_FS_B_64 1000;
BA_ "InvalidValue" SG_ 387 VCU_FS_B_64 "1h";
BA_ "GenSigTimeoutTime_ALL" SG_ 389 VCU_FS_C_1 1000;
BA_ "GenSigTimeoutTime_ALL" SG_ 389 VCU_FS_C_2 1000;
BA_ "GenSigTimeoutTime_ALL" SG_ 389 VCU_FS_C_3 1000;
BA_ "GenSigTimeoutTime_ALL" SG_ 389 VCU_FS_C_4 1000;
BA_ "GenSigTimeoutTime_ALL" SG_ 389 VCU_FS_C_5 1000;
BA_ "GenSigTimeoutTime_ALL" SG_ 389 VCU_FS_C_6 1000;
BA_ "GenSigTimeoutTime_ALL" SG_ 389 VCU_FS_C_7 1000;
BA_ "GenSigTimeoutTime_ALL" SG_ 389 VCU_FS_C_8 1000;
BA_ "GenSigTimeoutTime_ALL" SG_ 389 VCU_FS_C_9 1000;
BA_ "GenSigTimeoutTime_ALL" SG_ 389 VCU_FS_C_10 1000;
BA_ "GenSigTimeoutTime_ALL" SG_ 389 VCU_FS_C_11 1000;
BA_ "GenSigTimeoutTime_ALL" SG_ 389 VCU_FS_C_12 1000;
BA_ "GenSigTimeoutTime_ALL" SG_ 389 VCU_FS_C_13 1000;
BA_ "GenSigTimeoutTime_ALL" SG_ 389 VCU_FS_C_14 1000;
BA_ "GenSigTimeoutTime_ALL" SG_ 389 VCU_FS_C_15 1000;
BA_ "GenSigTimeoutTime_ALL" SG_ 389 VCU_FS_C_16 1000;
BA_ "GenSigTimeoutTime_ALL" SG_ 389 VCU_FS_C_17 1000;
BA_ "GenSigTimeoutTime_ALL" SG_ 389 VCU_FS_C_18 1000;
BA_ "GenSigTimeoutTime_ALL" SG_ 389 VCU_FS_C_19 1000;
BA_ "GenSigTimeoutTime_ALL" SG_ 389 VCU_FS_C_20 1000;
BA_ "GenSigTimeoutTime_ALL" SG_ 389 VCU_FS_C_21 1000;
BA_ "GenSigTimeoutTime_ALL" SG_ 389 VCU_FS_C_22 1000;
BA_ "GenSigTimeoutTime_ALL" SG_ 389 VCU_FS_C_23 1000;
BA_ "GenSigTimeoutTime_ALL" SG_ 389 VCU_FS_C_24 1000;
BA_ "GenSigTimeoutTime_ALL" SG_ 389 VCU_FS_C_25 1000;
BA_ "GenSigTimeoutTime_ALL" SG_ 389 VCU_FS_C_26 1000;
BA_ "GenSigTimeoutTime_ALL" SG_ 389 VCU_FS_C_27 1000;
BA_ "GenSigTimeoutTime_ALL" SG_ 389 VCU_FS_C_28 1000;
BA_ "GenSigTimeoutTime_ALL" SG_ 389 VCU_FS_C_29 1000;
BA_ "GenSigTimeoutTime_ALL" SG_ 389 VCU_FS_C_30 1000;
BA_ "GenSigTimeoutTime_ALL" SG_ 389 VCU_FS_C_31 1000;
BA_ "GenSigTimeoutTime_ALL" SG_ 389 VCU_FS_C_32 1000;
BA_ "GenSigTimeoutTime_ALL" SG_ 389 VCU_FS_C_33 1000;
BA_ "GenSigTimeoutTime_ALL" SG_ 389 VCU_FS_C_34 1000;
BA_ "GenSigTimeoutTime_ALL" SG_ 389 VCU_FS_C_34 1000;
BA_ "GenSigTimeoutTime_ALL" SG_ 389 VCU_FS_C_35 1000;
BA_ "GenSigTimeoutTime_ALL" SG_ 389 VCU_FS_C_36 1000;
BA_ "GenSigTimeoutTime_ALL" SG_ 389 VCU_FS_C_37 1000;
BA_ "GenSigTimeoutTime_ALL" SG_ 389 VCU_FS_C_38 1000;
BA_ "GenSigTimeoutTime_ALL" SG_ 389 VCU_FS_C_39 1000;
BA_ "GenSigTimeoutTime_ALL" SG_ 389 VCU_FS_C_40 1000;
BA_ "GenSigTimeoutTime_ALL" SG_ 389 VCU_FS_C_41 1000;
BA_ "GenSigTimeoutTime_ALL" SG_ 389 VCU_FS_C_42 1000;
BA_ "GenSigTimeoutTime_ALL" SG_ 389 VCU_FS_C_43 1000;
BA_ "GenSigTimeoutTime_ALL" SG_ 389 VCU_FS_C_44 1000;
BA_ "GenSigTimeoutTime_ALL" SG_ 389 VCU_FS_C_45 1000;
BA_ "GenSigTimeoutTime_ALL" SG_ 389 VCU_FS_C_46 1000;
BA_ "GenSigTimeoutTime_ALL" SG_ 389 VCU_FS_C_47 1000;
BA_ "GenSigTimeoutTime_ALL" SG_ 389 VCU_FS_C_48 1000;
BA_ "GenSigTimeoutTime_ALL" SG_ 389 VCU_FS_C_49 1000;
BA_ "GenSigTimeoutTime_ALL" SG_ 389 VCU_FS_C_50 1000;
BA_ "GenSigTimeoutTime_ALL" SG_ 389 VCU_FS_C_51 1000;
BA_ "GenSigTimeoutTime_ALL" SG_ 389 VCU_FS_C_52 1000;
BA_ "GenSigTimeoutTime_ALL" SG_ 389 VCU_FS_C_53 1000;
BA_ "GenSigTimeoutTime_ALL" SG_ 389 VCU_FS_C_54 1000;
BA_ "GenSigTimeoutTime_ALL" SG_ 389 VCU_FS_C_55 1000;
BA_ "GenSigTimeoutTime_ALL" SG_ 389 VCU_FS_C_56 1000;
BA_ "GenSigTimeoutTime_ALL" SG_ 389 VCU_FS_C_57 1000;
BA_ "GenSigTimeoutTime_ALL" SG_ 389 VCU_FS_C_58 1000;
BA_ "GenSigTimeoutTime_ALL" SG_ 389 VCU_FS_C_59 1000;
BA_ "GenSigTimeoutTime_ALL" SG_ 389 VCU_FS_C_60 1000;
BA_ "GenSigTimeoutTime_ALL" SG_ 389 VCU_FS_C_61 1000;
BA_ "GenSigTimeoutTime_ALL" SG_ 389 VCU_FS_C_62 1000;
BA_ "GenSigTimeoutTime_ALL" SG_ 389 VCU_FS_C_63 1000;
BA_ "GenSigTimeoutTime_ALL" SG_ 389 VCU_FS_C_64 1000;
BA_ "GenSigTimeoutTime_ALL" SG_ 417 CHSKM_V_VEH 200;
BA_ "InvalidValue" SG_ 417 CHSKM_V_VEH "";
BA_ "GenSigTimeoutTime_ALL" SG_ 417 ALIV_V_VEH 200;
BA_ "InvalidValue" SG_ 417 ALIV_V_VEH "Fh";
BA_ "GenSigTimeoutTime_ALL" SG_ 417 V_VEH_COG 200;
BA_ "InvalidValue" SG_ 417 V_VEH_COG "FFFFh";
BA_ "GenSigTimeoutTime_ALL" SG_ 417 DVCO_VEH 200;
BA_ "InvalidValue" SG_ 417 DVCO_VEH "7h";
BA_ "GenSigStartValue" SG_ 417 QU_V_VEH_COG 8;
BA_ "GenSigTimeoutTime_ALL" SG_ 417 QU_V_VEH_COG 200;
BA_ "InvalidValue" SG_ 417 QU_V_VEH_COG "Fh";
BA_ "GenSigTimeoutTime_ALL" SG_ 430 CRC_VCU_FR_TorqCap 200;
BA_ "InvalidValue" SG_ 430 CRC_VCU_FR_TorqCap "";
BA_ "GenSigTimeoutTime_ALL" SG_ 430 ALIV_VCU_FR_TorqCap 200;
BA_ "InvalidValue" SG_ 430 ALIV_VCU_FR_TorqCap "Fh";
BA_ "GenSigTimeoutTime_ALL" SG_ 430 VCU_MaxTorq_FR 200;
BA_ "InvalidValue" SG_ 430 VCU_MaxTorq_FR "";
BA_ "GenSigTimeoutTime_ALL" SG_ 430 VCU_MaxTorq_Sts_FR 200;
BA_ "InvalidValue" SG_ 430 VCU_MaxTorq_Sts_FR "";
BA_ "GenSigTimeoutTime_ALL" SG_ 430 VCU_MinTorq_FR 200;
BA_ "InvalidValue" SG_ 430 VCU_MinTorq_FR "";
BA_ "GenSigTimeoutTime_ALL" SG_ 430 VCU_MinTorq_Sts_FR 200;
BA_ "InvalidValue" SG_ 430 VCU_MinTorq_Sts_FR "";
BA_ "GenSigTimeoutTime_ALL" SG_ 430 SECCAN_VCU_FR_TorqCap 200;
BA_ "InvalidValue" SG_ 430 SECCAN_VCU_FR_TorqCap "";
BA_ "GenSigTimeoutTime_ALL" SG_ 431 CRC_VCU_RR_TorqCap 200;
BA_ "InvalidValue" SG_ 431 CRC_VCU_RR_TorqCap "";
BA_ "GenSigTimeoutTime_ALL" SG_ 431 ALIV_VCU_RR_TorqCap 200;
BA_ "InvalidValue" SG_ 431 ALIV_VCU_RR_TorqCap "Fh";
BA_ "GenSigTimeoutTime_ALL" SG_ 431 VCU_MaxTorq_RR 200;
BA_ "InvalidValue" SG_ 431 VCU_MaxTorq_RR "";
BA_ "GenSigTimeoutTime_ALL" SG_ 431 VCU_MaxTorq_Sts_RR 200;
BA_ "InvalidValue" SG_ 431 VCU_MaxTorq_Sts_RR "";
BA_ "GenSigTimeoutTime_ALL" SG_ 431 VCU_MinTorq_RR 200;
BA_ "InvalidValue" SG_ 431 VCU_MinTorq_RR "";
BA_ "GenSigTimeoutTime_ALL" SG_ 431 VCU_MinTorq_Sts_RR 200;
BA_ "InvalidValue" SG_ 431 VCU_MinTorq_Sts_RR "";
BA_ "GenSigTimeoutTime_ALL" SG_ 431 SECCAN_VCU_RR_TorqCap 200;
BA_ "InvalidValue" SG_ 431 SECCAN_VCU_RR_TorqCap "";
BA_ "GenSigTimeoutTime_ALL" SG_ 504 CHKSM_EDS_OutPut_FR 200;
BA_ "InvalidValue" SG_ 504 CHKSM_EDS_OutPut_FR "";
BA_ "GenSigTimeoutTime_ALL" SG_ 504 ALV_EDS_OutPut_FR 200;
BA_ "InvalidValue" SG_ 504 ALV_EDS_OutPut_FR "Fh";
BA_ "GenSigTimeoutTime_ALL" SG_ 504 EDS_Work_STS_FR 200;
BA_ "InvalidValue" SG_ 504 EDS_Work_STS_FR "Fh";
BA_ "GenSigStartValue" SG_ 504 EDS_Spd_FR 20000;
BA_ "GenSigTimeoutTime_ALL" SG_ 504 EDS_Spd_FR 200;
BA_ "InvalidValue" SG_ 504 EDS_Spd_FR "FFFFh";
BA_ "GenSigTimeoutTime_ALL" SG_ 504 EDS_output_trqValid_FR 200;
BA_ "InvalidValue" SG_ 504 EDS_output_trqValid_FR "";
BA_ "GenSigTimeoutTime_ALL" SG_ 504 EDS_MotorDriveSts_FR 200;
BA_ "InvalidValue" SG_ 504 EDS_MotorDriveSts_FR "3h";
BA_ "GenSigTimeoutTime_ALL" SG_ 504 EDS_powoff_req_FR 200;
BA_ "InvalidValue" SG_ 504 EDS_powoff_req_FR "";
BA_ "GenSigTimeoutTime_ALL" SG_ 504 EDS_SpdValid_FR 200;
BA_ "InvalidValue" SG_ 504 EDS_SpdValid_FR "";
BA_ "GenSigStartValue" SG_ 504 EDS_output_trq_FR 2000;
BA_ "GenSigTimeoutTime_ALL" SG_ 504 EDS_output_trq_FR 200;
BA_ "InvalidValue" SG_ 504 EDS_output_trq_FR "FFFFh";
BA_ "GenSigTimeoutTime_ALL" SG_ 504 EDS_VCU_6SO_flag_FWD 200;
BA_ "InvalidValue" SG_ 504 EDS_VCU_6SO_flag_FWD "";
BA_ "GenSigTimeoutTime_ALL" SG_ 505 CHKSM_EDS_OutPut_RR 200;
BA_ "InvalidValue" SG_ 505 CHKSM_EDS_OutPut_RR "";
BA_ "GenSigTimeoutTime_ALL" SG_ 505 ALV_EDS_OutPut_RR 200;
BA_ "InvalidValue" SG_ 505 ALV_EDS_OutPut_RR "Fh";
BA_ "GenSigTimeoutTime_ALL" SG_ 505 EDS_Work_STS_RR 200;
BA_ "InvalidValue" SG_ 505 EDS_Work_STS_RR "Fh";
BA_ "GenSigStartValue" SG_ 505 EDS_Spd_RR 20000;
BA_ "GenSigTimeoutTime_ALL" SG_ 505 EDS_Spd_RR 200;
BA_ "InvalidValue" SG_ 505 EDS_Spd_RR "FFFFh";
BA_ "GenSigTimeoutTime_ALL" SG_ 505 EDS_output_trqValid_RR 200;
BA_ "InvalidValue" SG_ 505 EDS_output_trqValid_RR "";
BA_ "GenSigTimeoutTime_ALL" SG_ 505 EDS_MotorDriveSts_RR 200;
BA_ "InvalidValue" SG_ 505 EDS_MotorDriveSts_RR "3h";
BA_ "GenSigTimeoutTime_ALL" SG_ 505 EDS_powoff_req_RR 200;
BA_ "InvalidValue" SG_ 505 EDS_powoff_req_RR "";
BA_ "GenSigTimeoutTime_ALL" SG_ 505 EDS_SpdValid_RR 200;
BA_ "InvalidValue" SG_ 505 EDS_SpdValid_RR "";
BA_ "GenSigStartValue" SG_ 505 EDS_output_trq_RR 2000;
BA_ "GenSigTimeoutTime_ALL" SG_ 505 EDS_output_trq_RR 200;
BA_ "InvalidValue" SG_ 505 EDS_output_trq_RR "FFFFh";
BA_ "GenSigTimeoutTime_ALL" SG_ 505 EDS_VCU_6SO_flag_RWD 200;
BA_ "InvalidValue" SG_ 505 EDS_VCU_6SO_flag_RWD "";
BA_ "GenSigTimeoutTime_ALL" SG_ 524 CHKSM_IC_ODO 500;
BA_ "InvalidValue" SG_ 524 CHKSM_IC_ODO "";
BA_ "GenSigTimeoutTime_ALL" SG_ 524 ALIV_IC_ODO 500;
BA_ "InvalidValue" SG_ 524 ALIV_IC_ODO "Fh";
BA_ "GenSigTimeoutTime_ALL" SG_ 524 MHU_Odometer_IC 500;
BA_ "InvalidValue" SG_ 524 MHU_Odometer_IC "FFFFFh";
BA_ "GenSigTimeoutTime_ALL" SG_ 531 CHSKM_VCU_POD_reqDCDC 500;
BA_ "InvalidValue" SG_ 531 CHSKM_VCU_POD_reqDCDC "";
BA_ "GenSigTimeoutTime_ALL" SG_ 531 ALV_VCU_POD_reqDCDC 500;
BA_ "InvalidValue" SG_ 531 ALV_VCU_POD_reqDCDC "Fh";
BA_ "GenSigTimeoutTime_ALL" SG_ 531 VCU_enableDCDC 500;
BA_ "InvalidValue" SG_ 531 VCU_enableDCDC "3h";
BA_ "GenSigStartValue" SG_ 531 VCU_vDCDCRequest 224;
BA_ "GenSigTimeoutTime_ALL" SG_ 531 VCU_vDCDCRequest 500;
BA_ "InvalidValue" SG_ 531 VCU_vDCDCRequest "FFFFh";
BA_ "GenSigTimeoutTime_ALL" SG_ 531 VCU_iDCDCRequest_lim 500;
BA_ "InvalidValue" SG_ 531 VCU_iDCDCRequest_lim "FFFFh";
BA_ "GenSigTimeoutTime_ALL" SG_ 532 CRC_VCU_ADAS 200;
BA_ "InvalidValue" SG_ 532 CRC_VCU_ADAS "";
BA_ "GenSigTimeoutTime_ALL" SG_ 532 ALIV_VCU_ADAS 200;
BA_ "InvalidValue" SG_ 532 ALIV_VCU_ADAS "Fh";
BA_ "GenSigTimeoutTime_ALL" SG_ 532 VCU_ADAS_ControledRes 200;
BA_ "InvalidValue" SG_ 532 VCU_ADAS_ControledRes "";
BA_ "GenSigTimeoutTime_ALL" SG_ 532 VCU_ADAS_Available 200;
BA_ "InvalidValue" SG_ 532 VCU_ADAS_Available "";
BA_ "GenSigTimeoutTime_ALL" SG_ 532 VCU_Accel_Pedal_Position_Virtual 200;
BA_ "InvalidValue" SG_ 532 VCU_Accel_Pedal_Position_Virtual "FFh";
BA_ "GenSigTimeoutTime_ALL" SG_ 532 VCU_ADAS_FuncMode 200;
BA_ "InvalidValue" SG_ 532 VCU_ADAS_FuncMode "";
BA_ "GenSigTimeoutTime_ALL" SG_ 532 VCU_ADAS_CtrlAbortFeedback 200;
BA_ "InvalidValue" SG_ 532 VCU_ADAS_CtrlAbortFeedback "";
BA_ "GenSigTimeoutTime_ALL" SG_ 533 Checksum_0x215 500;
BA_ "InvalidValue" SG_ 533 Checksum_0x215 "";
BA_ "GenSigTimeoutTime_ALL" SG_ 533 Rolling_Counter_0x215 500;
BA_ "InvalidValue" SG_ 533 Rolling_Counter_0x215 "Fh";
BA_ "GenSigTimeoutTime_ALL" SG_ 533 BMS_BatBalance_ERR 500;
BA_ "InvalidValue" SG_ 533 BMS_BatBalance_ERR "";
BA_ "GenSigTimeoutTime_ALL" SG_ 533 BMS_Balance_STS 500;
BA_ "InvalidValue" SG_ 533 BMS_Balance_STS "";
BA_ "GenSigTimeoutTime_ALL" SG_ 533 BMS_IGN_Sts 500;
BA_ "InvalidValue" SG_ 533 BMS_IGN_Sts "";
BA_ "GenSigTimeoutTime_ALL" SG_ 533 BMS_HWCrash_Sts 500;
BA_ "InvalidValue" SG_ 533 BMS_HWCrash_Sts "";
BA_ "GenSigTimeoutTime_ALL" SG_ 533 BMS_HVIL_STS 500;
BA_ "InvalidValue" SG_ 533 BMS_HVIL_STS "3h";
BA_ "GenSigTimeoutTime_ALL" SG_ 533 BMS_HVOnOff_STS 500;
BA_ "InvalidValue" SG_ 533 BMS_HVOnOff_STS "";
BA_ "GenSigTimeoutTime_ALL" SG_ 533 BMS_ERR_LEV 500;
BA_ "InvalidValue" SG_ 533 BMS_ERR_LEV "";
BA_ "GenSigTimeoutTime_ALL" SG_ 533 BMS_SocActual_EST 500;
BA_ "InvalidValue" SG_ 533 BMS_SocActual_EST "3FFh";
BA_ "GenSigTimeoutTime_ALL" SG_ 533 BMS_Sys_STS 500;
BA_ "InvalidValue" SG_ 533 BMS_Sys_STS "8h";
BA_ "GenSigTimeoutTime_ALL" SG_ 533 BMS_ISU_Status 500;
BA_ "InvalidValue" SG_ 533 BMS_ISU_Status "";
BA_ "GenSigStartValue" SG_ 533 BMS_SOH 54;
BA_ "GenSigTimeoutTime_ALL" SG_ 533 BMS_SOH 500;
BA_ "InvalidValue" SG_ 533 BMS_SOH "FFh";
BA_ "GenSigStartValue" SG_ 533 BMS_SOE 54;
BA_ "GenSigTimeoutTime_ALL" SG_ 533 BMS_SOE 500;
BA_ "InvalidValue" SG_ 533 BMS_SOE "FFh";
BA_ "GenSigTimeoutTime_ALL" SG_ 533 BMS_HV_Sts 500;
BA_ "GenSigTimeoutTime_ALL" SG_ 545 CCUR_Req_AirCondition 1000;
BA_ "InvalidValue" SG_ 545 CCUR_Req_AirCondition "3h";
BA_ "GenSigTimeoutTime_ALL" SG_ 545 SECCAN_CCUR 1000;
BA_ "InvalidValue" SG_ 545 SECCAN_CCUR "";
BA_ "GenSigTimeoutTime_ALL" SG_ 546 FRONT_SET_Rear_AirCondition 5000;
BA_ "InvalidValue" SG_ 546 FRONT_SET_Rear_AirCondition "3h";
BA_ "GenSigTimeoutTime_ALL" SG_ 546 SECCAN_CCUF 5000;
BA_ "InvalidValue" SG_ 546 SECCAN_CCUF "";
BA_ "GenSigTimeoutTime_ALL" SG_ 553 CHSKM_VCU_EDSControl_Front 200;
BA_ "InvalidValue" SG_ 553 CHSKM_VCU_EDSControl_Front "";
BA_ "GenSigTimeoutTime_ALL" SG_ 553 ALV_VCU_EDSControl_Front 200;
BA_ "InvalidValue" SG_ 553 ALV_VCU_EDSControl_Front "Fh";
BA_ "GenSigTimeoutTime_ALL" SG_ 553 VCU_EDS_StsModeReq_FWD 200;
BA_ "InvalidValue" SG_ 553 VCU_EDS_StsModeReq_FWD "Fh";
BA_ "GenSigStartValue" SG_ 553 VCU_EDS_TargetTqMin_FWD 500;
BA_ "GenSigTimeoutTime_ALL" SG_ 553 VCU_EDS_TargetTqMin_FWD 200;
BA_ "InvalidValue" SG_ 553 VCU_EDS_TargetTqMin_FWD "";
BA_ "GenSigTimeoutTime_ALL" SG_ 553 VCU_EparkCMD_FWD 200;
BA_ "InvalidValue" SG_ 553 VCU_EparkCMD_FWD "3h";
BA_ "GenSigStartValue" SG_ 553 VCU_EDS_demtrq_FWD 1000;
BA_ "GenSigTimeoutTime_ALL" SG_ 553 VCU_EDS_demtrq_FWD 200;
BA_ "InvalidValue" SG_ 553 VCU_EDS_demtrq_FWD "";
BA_ "GenSigTimeoutTime_ALL" SG_ 553 VCU_EDS_TargetTqMax_FWD 200;
BA_ "InvalidValue" SG_ 553 VCU_EDS_TargetTqMax_FWD "";
BA_ "GenSigTimeoutTime_ALL" SG_ 553 VCU_EDS_ActiveHeating_Request 200;
BA_ "InvalidValue" SG_ 553 VCU_EDS_ActiveHeating_Request "";
BA_ "GenSigTimeoutTime_ALL" SG_ 553 VCU_EDS_CreepFlg_FWD 200;
BA_ "InvalidValue" SG_ 553 VCU_EDS_CreepFlg_FWD "";
BA_ "GenSigTimeoutTime_ALL" SG_ 553 VCU_EDS_HILLHoldFlg_FWD 200;
BA_ "InvalidValue" SG_ 553 VCU_EDS_HILLHoldFlg_FWD "";
BA_ "GenSigTimeoutTime_ALL" SG_ 553 VCU_EDS_demtrqValid_FWD 200;
BA_ "InvalidValue" SG_ 553 VCU_EDS_demtrqValid_FWD "";
BA_ "GenSigTimeoutTime_ALL" SG_ 553 VCU_EDS_HeatPowerDemand 200;
BA_ "InvalidValue" SG_ 553 VCU_EDS_HeatPowerDemand "FFh";
BA_ "GenSigTimeoutTime_ALL" SG_ 560 CHSKM_VCU_EDSControl_Rear 200;
BA_ "InvalidValue" SG_ 560 CHSKM_VCU_EDSControl_Rear "";
BA_ "GenSigTimeoutTime_ALL" SG_ 560 ALV_VCU_EDSControl_Rear 200;
BA_ "InvalidValue" SG_ 560 ALV_VCU_EDSControl_Rear "Fh";
BA_ "GenSigStartValue" SG_ 560 VCU_EDS_TargetTqMin_RWD 500;
BA_ "GenSigTimeoutTime_ALL" SG_ 560 VCU_EDS_TargetTqMin_RWD 200;
BA_ "InvalidValue" SG_ 560 VCU_EDS_TargetTqMin_RWD "";
BA_ "GenSigStartValue" SG_ 560 VCU_EDS_demtrq_RWD 1000;
BA_ "GenSigTimeoutTime_ALL" SG_ 560 VCU_EDS_demtrq_RWD 200;
BA_ "InvalidValue" SG_ 560 VCU_EDS_demtrq_RWD "";
BA_ "GenSigTimeoutTime_ALL" SG_ 560 VCU_EDS_StsModeReq_RWD 200;
BA_ "InvalidValue" SG_ 560 VCU_EDS_StsModeReq_RWD "Fh";
BA_ "GenSigTimeoutTime_ALL" SG_ 560 VCU_EDS_TargetTqMax_RWD 200;
BA_ "InvalidValue" SG_ 560 VCU_EDS_TargetTqMax_RWD "";
BA_ "GenSigTimeoutTime_ALL" SG_ 560 VCU_EDS_demtrqValid_RWD 200;
BA_ "InvalidValue" SG_ 560 VCU_EDS_demtrqValid_RWD "";
BA_ "GenSigTimeoutTime_ALL" SG_ 560 VCU_EDS_HILLHoldFlg_RWD 200;
BA_ "InvalidValue" SG_ 560 VCU_EDS_HILLHoldFlg_RWD "";
BA_ "GenSigTimeoutTime_ALL" SG_ 560 VCU_EDS_CreepFlg_RWD 200;
BA_ "InvalidValue" SG_ 560 VCU_EDS_CreepFlg_RWD "";
BA_ "GenSigTimeoutTime_ALL" SG_ 565 CHKSM_TRM_STATUS 500;
BA_ "InvalidValue" SG_ 565 CHKSM_TRM_STATUS "";
BA_ "GenSigTimeoutTime_ALL" SG_ 565 ALIVE_TRM_STATUS 500;
BA_ "InvalidValue" SG_ 565 ALIVE_TRM_STATUS "Fh";
BA_ "GenSigTimeoutTime_ALL" SG_ 565 TowingDetected 500;
BA_ "InvalidValue" SG_ 565 TowingDetected "3h";
BA_ "GenSigTimeoutTime_ALL" SG_ 565 TrailerDetected 500;
BA_ "InvalidValue" SG_ 565 TrailerDetected "3h";

VAL_ 133 ACM_Crash_Sts 0 "No_Event" 1 "Crash_Detected";
VAL_ 133 ACM_Airbag_Deployment_Status 0 "No_Airbag_Deployment" 1 "Airbag_Deployment";
VAL_ 133 ACM_Crash_Intensity 0 "No_Crash" 1 "Crash_Intensity_1" 2 "Crash_Intensity_2" 3 "Crash_Intensity_3";
VAL_ 133 ACM_Front_Crash 0 "No_Event" 1 "Front_Crash_Detected";
VAL_ 133 ACM_DriverSide_Crash 0 "No_Event" 1 "Driverside_Crash_Detected";
VAL_ 133 ACM_PassSide_Crash 0 "No_Event" 1 "PasSide_Crash_Detected";
VAL_ 133 ACM_Rear_Crash 0 "No_Event" 1 "Rear_Crash_Detected";
VAL_ 133 ACM_Rollover_Crash 0 "No_Event" 1 "Rollover_Crash_Detected";
VAL_ 148 VCU_Pump_3_Stt 0 "OFF" 1 "ON" 2 "Fault" 3 "Reserve";
VAL_ 149 STAT_ABS 0 "No error" 1 "Error Full functionality of ABS is not available" 2 "Reserved" 3 "Signal invalid";
VAL_ 149 ABS_Active 0 "Inactive" 1 "Active" 2 "Reserved" 3 "Signal invalid";
VAL_ 149 AYC_Active 0 "Inactive" 1 "Active" 2 "Reserved" 3 "Signal invalid";
VAL_ 149 ASR_Active 0 "Inactive" 1 "Active" 2 "Reserved" 3 "Signal invalid";
VAL_ 149 STAT_DSC 0 "IDB normal" 1 "Traction Mode" 2 "IDB-OFF" 3 "Signal invalid";
VAL_ 149 DSC_Active 0 "Inactive" 1 "Active" 2 "Reserved" 3 "Signal invalid";
VAL_ 149 HBA_ActiveSignal 0 "Inactive" 1 "Active" 2 "Reserved" 3 "Signal invalid";
VAL_ 149 ARM_ActiveSignal 0 "Inactive" 1 "Active" 2 "Reserved" 3 "Signal invalid";
VAL_ 149 STAT_AutoHazardBlinking 0 "AutoHazardBlinking OFF" 1 "AutoHazardBlinking ON" 2 "Reserved" 3 "Signal invalid";
VAL_ 149 MSR_Active 0 "Inactive" 1 "Active" 2 "Reserved" 3 "Signal invalid";
VAL_ 149 HSA_ActiveSignal 0 "Inactive" 1 "Active" 2 "Reserved" 3 "Signal invalid";
VAL_ 149 EPBi_ECD_ActiveSignal 0 "Function supported by EPBi active signal" 1 "Function supported by EPBi no active" 2 "Reserved" 3 "Signal invalid";
VAL_ 149 TSM_Active 0 "Not active" 1 "Active" 2 "No trailer" 3 "Invalid";
VAL_ 149 HAS_Available 0 "No error" 1 "Error. Functionality of Hiil Hold is not available" 2 "Reserved" 3 "Signal invalid";
VAL_ 149 STAT_EBD 0 "No error" 1 "Error . Functionality of EBD is not available" 2 "Reserved" 3 "Signal invalid";
VAL_ 149 EBD_Active 0 "Inactive" 1 "Active" 2 "Reserved" 3 "Signal invalid";
VAL_ 149 ST_BRG_MSA 0 "vehicle is not held at speed 0 by the brake" 1 "vehicle is held at speed 0 by the brake" 14 "functions reports error" 15 "signal invalid";
VAL_ 150 MHU_IDB_Mode_Select_Signal 0 "IDB nomal" 1 "Traction Mode" 2 "IDB-OFF" 3 "Signal Invalid";
VAL_ 217 VCU_HVsystem_status 0 "Not ready" 1 "HV On" 2 "ReadyToDrive" 3 "Charging" 4 "Error" 5 "Reserved" 6 "Reserved" 7 "Reserved";
VAL_ 217 VCU_ACPD_Percent_Valid 0 "Valid" 1 "Invalid";
VAL_ 217 VCU_ACTGear 0 "P" 1 "R" 2 "N" 3 "D" 4 "Reserved" 5 "Reserved" 6 "Reserved" 7 "Fault";
VAL_ 217 VCU_ACTGearValid 0 "Valid" 1 "Invalid";
VAL_ 217 VCU_ACT_DriveMode 0 "Normal mode" 1 "ECO mode" 2 "Sport mode" 3 "Reserved" 4 "Reserved" 5 "Reserved" 6 "Reserved" 7 "Invalid";
VAL_ 217 VCU_ACT_DriveMode_Valid 0 "Valid" 1 "Invalid";
VAL_ 217 VCU_HV_DRVsystem_status 0 "Not available" 1 "Normal" 2 "Degration" 3 "Limphome" 4 "Error" 5 "Reserved" 6 "Reserved" 7 "Reserved";
VAL_ 217 VCU_Recu_BrakeLight_ON_Req 0 "Brake light OFF" 1 "Brake light ON" 2 "Reserved" 3 "Signal not available";
VAL_ 218 VCU_RecuBrkTorqCap_Sts_FR 0 "Not Initialized" 1 "Normal" 2 "Faulty";
VAL_ 218 VCU_RecuBrkTorqCap_Sts_RR 0 "Not Initialized" 1 "Normal" 2 "Faulty";
VAL_ 219 VCU_BrkRegenTorqueActValid_FR 0 "Valid" 1 "Invalid";
VAL_ 219 VCU_BrkRegenTorqueActValid_RR 0 "Valid" 1 "Invalid";
VAL_ 225 IDB_ACC_WheelTrq_Request 0 "No Request" 1 "Request Wheel Torque";
VAL_ 226 IDB_APA_WheelTrq_Request 0 "No Request" 1 "Request Wheel Torque" ;
VAL_ 256 MHU_UserProfileId 0 "User 1 - Guess mode" 1 "User 2 - Valet mode" 2 "User 3" 3 "User 4" 4 "User 5" 5 "User 6" 6 "User 7" 7 "User 8" 8 "User 9" 9 "User 10" 15 "Invalid Value";
VAL_ 256 MHU_Connectivity_Status 0 "Init" 1 "No Connection" 2 "LTE Internet Connection" 3 "WIFI Internet Establish" 4 "WIFI + LTE Connection" 5 "Reserved" 6 "Reserved" 7 "Reserved";
VAL_ 260 SOH_SUL 255 "Signal invalid";
VAL_ 260 SOH_SUL_STATE 0 "Not learned" 1 "Learned" 2 "Reserved" 3 "Signal invalid";
VAL_ 260 SOC_STATE 0 "deviation > 15% " 1 "deviation < 15%" 2 "deviation < 10%" 3 "invalid";
VAL_ 260 Resp_Error 0 "No Error" 1 "Error";
VAL_ 260 FLAG_INCONSTENCY 0 "No battery inconsistency" 1 "Battery inconsistency";
VAL_ 260 EBS_error 0 "No Error" 1 "Error";
VAL_ 260 FLAG_DISCONNECT 0 "No battery disconnection" 1 "Battery disconnection";
VAL_ 260 BCM_LV_Batt_Charging_Req 0 "Disable " 1 "Enable";
VAL_ 261 BCM_STAT_TrunkAjar 0 "Closed" 1 "Opened" 2 "Reserved" 3 "Signal invalid";
VAL_ 261 BCM_STAT_DoorAjarFL 0 "Closed" 1 "Opened" 2 "Reserved" 3 "Signal invalid";
VAL_ 261 BCM_STAT_DoorAjarFR 0 "Closed" 1 "Opened" 2 "Reserved" 3 "Signal invalid";
VAL_ 261 BCM_STAT_DoorAjarRL 0 "Closed" 1 "Opened" 2 "Reserved" 3 "Signal invalid";
VAL_ 261 BCM_STAT_DoorAjarRR 0 "Closed" 1 "Opened" 2 "Reserved" 3 "Signal invalid";
VAL_ 261 BCM_STAT_BonnetAjar 0 "Closed" 1 "Opened" 2 "Reserved" 3 "Signal invalid";
VAL_ 264 GS_TargetGearReq 0 "P" 1 "R" 2 "N" 3 "D" 4 "Reserved" 5 "Reserved" 6 "Reserved" 7 "Fault";
VAL_ 265 BCM_STAT_BrakeSwitch 0 "Brake not pressed" 1 "Brake Pressed" 2 "Reserved" 3 "Signal invalid";
VAL_ 265 BCM_STAT_HazardWarn 0 "Not active" 1 "Active" 2 "Reserved" 3 "Signal invalid";
VAL_ 265 BCM_STAT_FuelPumpCutOFF 0 "Not active" 1 "Active" 2 "Reserved" 3 "Signal invalid";
VAL_ 265 BCM_FollowMeHomeActive 0 "Not Active" 1 "Active" 2 "Reserved" 3 "Signal Invalid";
VAL_ 265 BCM_STAT_Horn 0 "OFF" 1 "ON" 2 "Reserved" 3 "Signal invalid";
VAL_ 265 BCM_STAT_Autowiping 0 "OFF" 1 "ON" 2 "Reserved" 3 "Signal invalid";
VAL_ 265 BCM_TurnIndicator 0 "OFF" 1 "Left" 2 "Right";
VAL_ 265 BCM_WelcomeActive 0 "Not Active" 1 "Active" 2 "Reserved" 3 "Signal Invalid";
VAL_ 265 BCM_HighBeam 0 "OFF" 1 "High Beam" 2 "Flash high Beam" 3 "Fault";
VAL_ 265 ACM_Seat_Belt_Status_3rd_Row_Pas 0 "Not_buckled" 1 "Buckled" 2 "Not_Available" 3 "Failure";
VAL_ 265 ACM_Seat_Belt_Status_3rd_Row_Dri 0 "Not_buckled" 1 "Buckled" 2 "Not_Available" 3 "Failure";
VAL_ 266 LV_BatteryType 0 "Lead Acid Battery" 1 "Lithium Battery" 2 "Reversed" 3 "Invalid";
VAL_ 274 RemoteFunctionState 0 "Normal function" 1 "Remote function" 2 "Reserved" 3 "Signal Invalid";
VAL_ 274 STAT_BLS 0 "BLS not pressed" 1 "BLS pressed" 2 "Reserved" 3 "Signal invalid";
VAL_ 274 STAT_CL_50_L 0 "OFF" 1 "ON" 2 "Failure" 3 "Signal invalid";
VAL_ 274 Clamp50AdviceRemoteStart 0 "Engine Start announcement not active" 1 "Engine Start announcement active" 2 "Reserved" 3 "Invalid";
VAL_ 274 Clamp50AdviceESS 0 "Engine Start announcement not active" 1 "Engine Start announcement active" 2 "Reserved" 3 "Invalid";
VAL_ 274 STAT_CL_R_L 0 "OFF" 1 "ON" 2 "Failure" 3 "Signal invalid";
VAL_ 274 STAT_CL_15_1_L 0 "OFF" 1 "ON" 2 "Failure" 3 "Signal invalid";
VAL_ 274 STAT_CL_15_1_DME_L 0 "OFF" 1 "ON" 2 "Failure" 3 "Signal invalid";
VAL_ 274 FobId 0 "Key not available" 1 "FOB_1" 2 "FOB_2" 3 "Signal invalid";
VAL_ 274 STAT_Terminal 0 "OFF(Comfort Enable)" 1 "ACC (Park)" 2 "ON (Driver Present)" 3 "Engine start (eMotor running)" 4 "SW Update OTA" 5 "Reserved" 6 "Reserved" 7 "Signal Invalid";
VAL_ 274 STAT_CL30_C_BEV 0 "OFF" 1 "ON" 2 "Failure" 3 "Signal invalid";
VAL_ 274 BCM_Clamp_Transport 0 "Transport Disabled" 1 "Transport E-Motor Running" 2 "Transport Driver Present" 3 "Ttransport ACC" 4 "Transport OFF" 5 "Init" 6 "Reserved " 7 "Reserved ";
VAL_ 278 LV_WakeupReason 0 "None" 1 "Low SOC Wakeup" 2 "Low Temp Wakeup" 3 "High discharge current wakeup" 4 "High charge current wakeup" 5 "Reserve" 6 "Reserve" 7 "Invalid" ;
VAL_ 290 CCU_REQ_MaxCool 0 "OFF" 1 "ON" 2 "Reserved" 3 "Signal invalid";
VAL_ 290 CCU_REQ_MaxHeat 0 "OFF" 1 "ON" 2 "Reserved" 3 "Signal invalid";
VAL_ 290 CCU_REQ_ESSMotorControl 0 "No action" 1 "inhibit motor stop" 2 "request motor start" 3 "Reserved" 4 "Reserved" 5 "Reserved" 6 "Reserved" 7 "Signal invalid";
VAL_ 303 ST_KL 0 "Init" 1 "Reserved" 2 "KL30" 3 "Reserved" 4 "Reserved" 5 "Reserved" 6 "KL30B-ON" 7 "KL30C-ON (BEV Only)" 8 "KLR-ON" 9 "KL15-change" 10 "KL15-ON" 11 "KL50-delay (ICE only)" 12 "KL50-Change(ICE only)" 13 "KL50-ON (ICE only)" 14 "Reserved" 15 "Signal invalid";
VAL_ 303 ST_KL_KEY_VLD 0 "Init" 1 "Key invalid" 2 "Key search activ" 3 "Key valid AR" 4 "Key valid IR" 5 "Key 10sec delay" 6 "Reserved" 7 "Reserved" 8 "Reserved" 9 "Reserved" 10 "Reserved" 11 "Reserved" 12 "Reserved" 13 "Reserved" 14 "Error" 15 "Signal invalid";
VAL_ 303 STAT_AlcoholIgnStatus 0 "OFF" 1 "ON" 2 "Reserved" 3 "Signal invalid" ;
VAL_ 303 STAT_AlcoholEngineStatus 0 "OFF" 1 "ON" 2 "Reserved" 3 "Signal invalid" ;
VAL_ 303 ST_STCD_PENG 0 "Startcondition traction not fulfilled" 1 "Startcondition traction fulfilled" 2 "Startcondition traction  implausible fulfilled" 3 "Signal invalid";
VAL_ 303 ST_SSB 0 "SSB not pressed" 1 "SSB pressed" 2 "Reserve" 3 "Signal invalid";
VAL_ 303 RWDT_BLS 0 "BLTS and BLS not applied" 1 "BLS applied" 2 "BLTS  applied" 3 "BLTS and BLS  valid applied" 4 "Reserved" 5 "Reserved" 6 "Reserved" 7 "Error (Invalid signal from BLTS or BLS)" 8 "Init" 15 "Signal invalid";
VAL_ 303 RQ_DRVG_RDI 0 "No action" 1 "Engine start advice" 2 "Reserved" 3 "Signal invalid";
VAL_ 303 CTR_ENG_STOP 0 "Init" 1 "Default" 2 "Motor_Off" 3 "Signal invalid";
VAL_ 303 ST_VEH_CON 0 "Initial (VSM_STM_STATE_INIT)" 1 "Standby, driver absent (VSM_STM_STATE_STANDBY)" 2 "Basis operation, driver present (VSM_STM_STATE_BASICOP)" 3 "Basis operation, vehicle coasting (VSM_STM_STATE_BASICOP_ROLL)" 4 "Engine postrun (VSM_STM_STATE_15OFF_DRIVE)" 5 "Ignition On (VSM_STM_STATE_IGNITION)" 6 "Ignition On, vehicle coasting (VSM_STM_STATE_IGNITION_ROLL)" 7 "Engine On, vehicle not coasting (VSM_STM_STATE_ENG_IDLE)" 8 "Driving (VSM_STM_STATE_DRIVE)" 9 "Impending start of engine (VSM_STM_STATE_ENG_START_PRE)" 10 "Impending start of engine, vehicle coasting (VSM_STM_STATE_ENG_START_PRE_ROLL)" 11 "Start engine (VSM_STM_STATE_ENG_START)" 12 "Start engine, vehicle coasting (VSM_STM_STATE_ENG_START_ROLL)" 13 "Car wash operation (VSM_STM_STATE_WASH)" 14 "Error (VSM_STM_STATE_ERROR)" 15 "Signal invalid";
VAL_ 310 PnC_activation 0 "ON" 1 "OFF";
VAL_ 310 PnCandEIM_Switch 0 "PnC" 1 "EMI";
VAL_ 310 PnC_trigger1 0 "Available" 1 "Not Available";
VAL_ 310 PnC_trigger2 0 "Available" 1 "Not Available";
VAL_ 310 PnC_Cert_Del 0 "Available" 1 "Del_Cert";
VAL_ 310 PnC_feature_enable 0 "Enable" 1 "Disable";
VAL_ 311 OK_OldSessionJoined 0 "Error" 1 "No Error";
VAL_ 311 OK_NewSessionEstablished 0 "Error" 1 "No Error";
VAL_ 311 OK_CertificateExpireSoon 0 "Error" 1 "No Error";
VAL_ 311 PnC_OK 0 "Error" 1 "No Error" 2 "Init";
VAL_ 311 Failed_CertificateNoAllowAtEVSE 0 "Error" 1 "No Error";
VAL_ 311 Failed_ContactorError 0 "Error" 1 "No Error";
VAL_ 311 Failed_NoChargeServiceSelectd 0 "Error" 1 "No Error";
VAL_ 311 PnC_Failed 0 "Error" 1 "No Error";
VAL_ 311 Failed_ServiceIDInvalid 0 "Error" 1 "No Error";
VAL_ 311 Falied_UnknownSession 0 "Error" 1 "No Error";
VAL_ 311 Failed_SignatureError 0 "Error" 1 "No Error";
VAL_ 311 Failed_SequenceError 0 "Error" 1 "No Error";
VAL_ 311 Failed_CertChainError 0 "Error" 1 "No Error";
VAL_ 311 Failed_NoCertificateAvailable 0 "Error" 1 "No Error";
VAL_ 311 Failed_CertificateRevoked 0 "Error" 1 "No Error";
VAL_ 311 Failed_PaymentSelectionInvalid 0 "Error" 1 "No Error";
VAL_ 311 Failed_WrongChargeParameter 0 "Error" 1 "No Error";
VAL_ 311 Failed_WrongEnergyTranferMode 0 "Error" 1 "No Error";
VAL_ 311 Failed_ChallengeInvalid 0 "Error" 1 "No Error";
VAL_ 311 Failed_ContractCancelled 0 "Error" 1 "No Error";
VAL_ 311 Failed_MeteringSignatureNotValid 0 "Error" 1 "No Error";
VAL_ 311 Failed_PowerDeliverNotApplied 0 "Error" 1 "No Error";
VAL_ 311 Failed_TarrifSelectionInvalid 0 "Error" 1 "No Error";
VAL_ 311 Failed_ChargingProfileInvalid 0 "Error" 1 "No Error";
VAL_ 311 Error_message_4 0 "Error" 1 "No Error";
VAL_ 311 Error_message_3 0 "Error" 1 "No Error";
VAL_ 311 Error_message_1 0 "Error" 1 "No Error";
VAL_ 311 Error_message_2 0 "Error" 1 "No Error";
VAL_ 311 PnC_ChargeSessionEnded 0 "In Progress" 1 "Charging_Ended";
VAL_ 311 PnC_Status 0 "Enabled" 1 "Disabled";
VAL_ 311 PnC_Contract_Status 0 "Installed" 1 "Not available";
VAL_ 311 Error_message_5 0 "Error" 1 "No Error";
VAL_ 316 FCAM_ACC_Mode_VCU 0 "initialization" 1 "OFF" 2 "Inhibited" 3 "Standy" 4 "Active" 5 "Override" 6 "Brake Only" 7 "Fault" ;
VAL_ 317 SessionPaymentType 0 "EIM" 1 "PNC" 2 "Error";
VAL_ 338 EDS_FuSa_error_FR 0 "normal" 1 "error" 2 "error" 3 "error" 4 "error" 5 "error" 6 "error" 7 "error" 8 "error" 9 "error" 10 "error" 11 "error" 12 "error" 13 "error" 14 "error" 15 "error";
VAL_ 338 EDS_shutoffpath_error_FR 0 "normal" 1 "error" 2 "error" 3 "error" 4 "error" 5 "error" 6 "error" 7 "error" 8 "error" 9 "error" 10 "error" 11 "error" 12 "error" 13 "error" 14 "error" 15 "error";
VAL_ 338 EDS_EDSDisChgFault_FWD 0 "normal" 1 "error" 2 "error" 3 "error" 4 "error" 5 "error" 6 "error" 7 "error" 8 "error" 9 "error" 10 "error" 11 "error" 12 "error" 13 "error" 14 "error" 15 "error";
VAL_ 339 EDS_FuSa_error_RR 0 "normal" 1 "error" 2 "error" 3 "error" 4 "error" 5 "error" 6 "error" 7 "error" 8 "error" 9 "error" 10 "error" 11 "error" 12 "error" 13 "error" 14 "error" 15 "error";
VAL_ 339 EDS_shutoffpath_error_RR 0 "normal" 1 "error" 2 "error" 3 "error" 4 "error" 5 "error" 6 "error" 7 "error" 8 "error" 9 "error" 10 "error" 11 "error" 12 "error" 13 "error" 14 "error" 15 "error";
VAL_ 339 EDS_EDSDisChgFault_RWD 0 "normal" 1 "error" 2 "error" 3 "error" 4 "error" 5 "error" 6 "error" 7 "error" 8 "error" 9 "error" 10 "error" 11 "error" 12 "error" 13 "error" 14 "error" 15 "error";
VAL_ 357 VCU_AcChgGunIn 0 "disconnect" 1 "connect";
VAL_ 357 VCU_DCChgGunIn 0 "disconnect" 1 "connect";
VAL_ 357 VCU_CPValue 127 "Invalid";
VAL_ 359 TWV1_St_Feedback 0 "Over Voltage" 1 "Under Voltage" 2 "OverTemp_Warning" 3 "OverTemp_ShutDown" 4 "Over Current" 5 "Stall" 6 "OpenLoad" 7 "Communication_Error" 8 "WTREST" 9 "POR" 10 "SensorOVR" 11 "Reserved" 12 "Reserved" 13 "Reserved" 14 "Reserved" 15 "TrgPosDone";
VAL_ 359 TWV1_Frm_Error 0 "Normal" 1 "Error";
VAL_ 376 YSS_LONG_ACCUNFILTERED_QUAL 2 "VALID" 4 "SUBSITUTE" 6 "IN VALID" 14 "NOT AVAILABLE" 15 "UNFILLED";
VAL_ 376 YSS_LONG_ACC_QUAL 2 "VALID" 4 "SUBSITUTE" 6 "IN VALID" 14 "NOT AVAILABLE" 15 "UNFILLED";
VAL_ 377 YSS_LAT_ACCUNFILTERED_QUAL 2 "VALID" 4 "SUBSITUTE" 6 "IN VALID" 14 "NOT AVAILABLE" 15 "UNFILLED";
VAL_ 377 YSS_LAT_ACC_QUAL 2 "VALID" 4 "SUBSITUTE" 6 "IN VALID" 14 "NOT AVAILABLE" 15 "UNFILLED";
VAL_ 381 YSS_YAW_RATEUNFILTERED_QUAL 2 "VALID" 4 "SUBSITUTE" 6 "IN VALID" 14 "NOT AVAILABLE" 15 "UNFILLED";
VAL_ 381 YSS_YAW_RATE_QUAL 2 "VALID" 4 "SUBSITUTE" 6 "IN VALID" 14 "NOT AVAILABLE" 15 "UNFILLED";
VAL_ 381 YSS_SC_STATUS 0 "No Mistake" 2 "Under Voltage" 3 "Over Voltage" 13 "Function Not Available" 14 "Function Error" 15 "Un-Filled";
VAL_ 384 EPS2_SAS_SASStsSnsr 0 "sensor value  Invalid" 1 "sensor value  valid";
VAL_ 384 EPS2_SAS_SteerWhlRotSpdStatus 0 "Invalid" 1 "Valid";
VAL_ 384 EPS2_SAS_SASFailure 0 "Failure" 1 "No Failure";
VAL_ 384 EPS2_SAS_Calibrated 0 "Not Calibrated" 1 "Calibrated";
VAL_ 384 EPS2_SAS_SteerWheelAngleValid 0 "Valid" 1 "Invalid";
VAL_ 385 VCU_Debug4 0 "No Error" 1 "Warning" 2 "Reduced HV System Power" 3 "Reduced Front EDS Power" 4 "Reduced Rear EDS Power" 5 "Front EDS Inhibit" 6 "Rear EDS Inhibit" 7 "Limp Home" 8 "Neutral Request" 9 "Soft Shutdown" 10 "Reduced HV System Power and Reduced Front EDS Power" 11 "Reduced HV System Power and Reduced Rear EDS Power" 12 "Reduced Front EDS Power and Reduced Rear EDS Power" 13 "Reduced HV System Power and Front EDS Inhibit" 14 "Reduced Rear EDS Power and Front EDS Inhibit" 15 "Reduced HV System Power and Rear EDS Inhibit" 16 "Reduced Front EDS Power and Rear EDS Inhibit" 17 "Reduced HV System Power and Limp Home" 18 "Front EDS Inhibit and Limp Home" 19 "Rear EDS Inhibit and Limp Home" 20 "Reduced HV System Power and Neutral Request" 21 "Emergency Shutdown";
VAL_ 386 VCU_FS_A_1 0 "No error" 1 "Error";
VAL_ 386 VCU_FS_A_2 0 "No error" 1 "Error";
VAL_ 386 VCU_FS_A_3 0 "No error" 1 "Error";
VAL_ 386 VCU_FS_A_4 0 "No error" 1 "Error";
VAL_ 386 VCU_FS_A_5 0 "No error" 1 "Error";
VAL_ 386 VCU_FS_A_6 0 "No error" 1 "Error";
VAL_ 386 VCU_FS_A_7 0 "No error" 1 "Error";
VAL_ 386 VCU_FS_A_8 0 "No error" 1 "Error";
VAL_ 386 VCU_FS_A_9 0 "No error" 1 "Error";
VAL_ 386 VCU_FS_A_10 0 "No error" 1 "Error";
VAL_ 386 VCU_FS_A_11 0 "No error" 1 "Error";
VAL_ 386 VCU_FS_A_12 0 "No error" 1 "Error";
VAL_ 386 VCU_FS_A_13 0 "No error" 1 "Error";
VAL_ 386 VCU_FS_A_14 0 "No error" 1 "Error";
VAL_ 386 VCU_FS_A_15 0 "No error" 1 "Error";
VAL_ 386 VCU_FS_A_16 0 "No error" 1 "Error";
VAL_ 386 VCU_FS_A_17 0 "No error" 1 "Error";
VAL_ 386 VCU_FS_A_18 0 "No error" 1 "Error";
VAL_ 386 VCU_FS_A_19 0 "No error" 1 "Error";
VAL_ 386 VCU_FS_A_20 0 "No error" 1 "Error";
VAL_ 386 VCU_FS_A_21 0 "No error" 1 "Error";
VAL_ 386 VCU_FS_A_22 0 "No error" 1 "Error";
VAL_ 386 VCU_FS_A_23 0 "No error" 1 "Error";
VAL_ 386 VCU_FS_A_24 0 "No error" 1 "Error";
VAL_ 386 VCU_FS_A_25 0 "No error" 1 "Error";
VAL_ 386 VCU_FS_A_26 0 "No error" 1 "Error";
VAL_ 386 VCU_FS_A_27 0 "No error" 1 "Error";
VAL_ 386 VCU_FS_A_28 0 "No error" 1 "Error";
VAL_ 386 VCU_FS_A_29 0 "No error" 1 "Error";
VAL_ 386 VCU_FS_A_30 0 "No error" 1 "Error";
VAL_ 386 VCU_FS_A_31 0 "No error" 1 "Error";
VAL_ 386 VCU_FS_A_32 0 "No error" 1 "Error";
VAL_ 386 VCU_FS_A_33 0 "No error" 1 "Error";
VAL_ 386 VCU_FS_A_34 0 "No error" 1 "Error";
VAL_ 386 VCU_FS_A_35 0 "No error" 1 "Error";
VAL_ 386 VCU_FS_A_36 0 "No error" 1 "Error";
VAL_ 386 VCU_FS_A_37 0 "No error" 1 "Error";
VAL_ 386 VCU_FS_A_38 0 "No error" 1 "Error";
VAL_ 386 VCU_FS_A_39 0 "No error" 1 "Error";
VAL_ 386 VCU_FS_A_40 0 "No error" 1 "Error";
VAL_ 386 VCU_FS_A_41 0 "No error" 1 "Error";
VAL_ 386 VCU_FS_A_42 0 "No error" 1 "Error";
VAL_ 386 VCU_FS_A_43 0 "No error" 1 "Error";
VAL_ 386 VCU_FS_A_44 0 "No error" 1 "Error";
VAL_ 386 VCU_FS_A_45 0 "No error" 1 "Error";
VAL_ 386 VCU_FS_A_46 0 "No error" 1 "Error";
VAL_ 386 VCU_FS_A_47 0 "No error" 1 "Error";
VAL_ 386 VCU_FS_A_48 0 "No error" 1 "Error";
VAL_ 386 VCU_FS_A_49 0 "No error" 1 "Error";
VAL_ 386 VCU_FS_A_50 0 "No error" 1 "Error";
VAL_ 386 VCU_FS_A_51 0 "No error" 1 "Error";
VAL_ 386 VCU_FS_A_52 0 "No error" 1 "Error";
VAL_ 386 VCU_FS_A_53 0 "No error" 1 "Error";
VAL_ 386 VCU_FS_A_54 0 "No error" 1 "Error";
VAL_ 386 VCU_FS_A_55 0 "No error" 1 "Error";
VAL_ 386 VCU_FS_A_56 0 "No error" 1 "Error";
VAL_ 386 VCU_FS_A_57 0 "No error" 1 "Error";
VAL_ 386 VCU_FS_A_58 0 "No error" 1 "Error";
VAL_ 386 VCU_FS_A_59 0 "No error" 1 "Error";
VAL_ 386 VCU_FS_A_60 0 "No error" 1 "Error";
VAL_ 386 VCU_FS_A_61 0 "No error" 1 "Error";
VAL_ 386 VCU_FS_A_62 0 "No error" 1 "Error";
VAL_ 386 VCU_FS_A_63 0 "No error" 1 "Error";
VAL_ 386 VCU_FS_A_64 0 "No error" 1 "Error";
VAL_ 387 VCU_FS_B_1 0 "No error" 1 "Error";
VAL_ 387 VCU_FS_B_2 0 "No error" 1 "Error";
VAL_ 387 VCU_FS_B_3 0 "No error" 1 "Error";
VAL_ 387 VCU_FS_B_4 0 "No error" 1 "Error";
VAL_ 387 VCU_FS_B_5 0 "No error" 1 "Error";
VAL_ 387 VCU_FS_B_6 0 "No error" 1 "Error";
VAL_ 387 VCU_FS_B_7 0 "No error" 1 "Error";
VAL_ 387 VCU_FS_B_8 0 "No error" 1 "Error";
VAL_ 387 VCU_FS_B_9 0 "No error" 1 "Error";
VAL_ 387 VCU_FS_B_10 0 "No error" 1 "Error";
VAL_ 387 VCU_FS_B_11 0 "No error" 1 "Error";
VAL_ 387 VCU_FS_B_12 0 "No error" 1 "Error";
VAL_ 387 VCU_FS_B_13 0 "No error" 1 "Error";
VAL_ 387 VCU_FS_B_14 0 "No error" 1 "Error";
VAL_ 387 VCU_FS_B_15 0 "No error" 1 "Error";
VAL_ 387 VCU_FS_B_16 0 "No error" 1 "Error";
VAL_ 387 VCU_FS_B_17 0 "No error" 1 "Error";
VAL_ 387 VCU_FS_B_18 0 "No error" 1 "Error";
VAL_ 387 VCU_FS_B_19 0 "No error" 1 "Error";
VAL_ 387 VCU_FS_B_20 0 "No error" 1 "Error";
VAL_ 387 VCU_FS_B_21 0 "No error" 1 "Error";
VAL_ 387 VCU_FS_B_22 0 "No error" 1 "Error";
VAL_ 387 VCU_FS_B_23 0 "No error" 1 "Error";
VAL_ 387 VCU_FS_B_24 0 "No error" 1 "Error";
VAL_ 387 VCU_FS_B_25 0 "No error" 1 "Error";
VAL_ 387 VCU_FS_B_26 0 "No error" 1 "Error";
VAL_ 387 VCU_FS_B_27 0 "No error" 1 "Error";
VAL_ 387 VCU_FS_B_28 0 "No error" 1 "Error";
VAL_ 387 VCU_FS_B_29 0 "No error" 1 "Error";
VAL_ 387 VCU_FS_B_30 0 "No error" 1 "Error";
VAL_ 387 VCU_FS_B_31 0 "No error" 1 "Error";
VAL_ 387 VCU_FS_B_32 0 "No error" 1 "Error";
VAL_ 387 VCU_FS_B_33 0 "No error" 1 "Error";
VAL_ 387 VCU_FS_B_34 0 "No error" 1 "Error";
VAL_ 387 VCU_FS_B_35 0 "No error" 1 "Error";
VAL_ 387 VCU_FS_B_36 0 "No error" 1 "Error";
VAL_ 387 VCU_FS_B_37 0 "No error" 1 "Error";
VAL_ 387 VCU_FS_B_38 0 "No error" 1 "Error";
VAL_ 387 VCU_FS_B_39 0 "No error" 1 "Error";
VAL_ 387 VCU_FS_B_40 0 "No error" 1 "Error";
VAL_ 387 VCU_FS_B_41 0 "No error" 1 "Error";
VAL_ 387 VCU_FS_B_42 0 "No error" 1 "Error";
VAL_ 387 VCU_FS_B_43 0 "No error" 1 "Error";
VAL_ 387 VCU_FS_B_44 0 "No error" 1 "Error";
VAL_ 387 VCU_FS_B_45 0 "No error" 1 "Error";
VAL_ 387 VCU_FS_B_46 0 "No error" 1 "Error";
VAL_ 387 VCU_FS_B_47 0 "No error" 1 "Error";
VAL_ 387 VCU_FS_B_48 0 "No error" 1 "Error";
VAL_ 387 VCU_FS_B_49 0 "No error" 1 "Error";
VAL_ 387 VCU_FS_B_50 0 "No error" 1 "Error";
VAL_ 387 VCU_FS_B_51 0 "No error" 1 "Error";
VAL_ 387 VCU_FS_B_52 0 "No error" 1 "Error";
VAL_ 387 VCU_FS_B_53 0 "No error" 1 "Error";
VAL_ 387 VCU_FS_B_54 0 "No error" 1 "Error";
VAL_ 387 VCU_FS_B_55 0 "No error" 1 "Error";
VAL_ 387 VCU_FS_B_56 0 "No error" 1 "Error";
VAL_ 387 VCU_FS_B_57 0 "No error" 1 "Error";
VAL_ 387 VCU_FS_B_58 0 "No error" 1 "Error";
VAL_ 387 VCU_FS_B_59 0 "No error" 1 "Error";
VAL_ 387 VCU_FS_B_60 0 "No error" 1 "Error";
VAL_ 387 VCU_FS_B_61 0 "No error" 1 "Error";
VAL_ 387 VCU_FS_B_62 0 "No error" 1 "Error";
VAL_ 387 VCU_FS_B_63 0 "No error" 1 "Error";
VAL_ 387 VCU_FS_B_64 0 "No error" 1 "Error";
VAL_ 389 VCU_FS_C_1 0 "normal" 1 "error" ;
VAL_ 389 VCU_FS_C_2 0 "normal" 1 "error" ;
VAL_ 389 VCU_FS_C_3 0 "normal" 1 "error" ;
VAL_ 389 VCU_FS_C_4 0 "normal" 1 "error" ;
VAL_ 389 VCU_FS_C_5 0 "normal" 1 "error" ;
VAL_ 389 VCU_FS_C_6 0 "normal" 1 "error" ;
VAL_ 389 VCU_FS_C_7 0 "normal" 1 "error" ;
VAL_ 389 VCU_FS_C_8 0 "normal" 1 "error" ;
VAL_ 389 VCU_FS_C_9 0 "normal" 1 "error" ;
VAL_ 389 VCU_FS_C_10 0 "normal" 1 "error" ;
VAL_ 389 VCU_FS_C_11 0 "normal" 1 "error" ;
VAL_ 389 VCU_FS_C_12 0 "normal" 1 "error" ;
VAL_ 389 VCU_FS_C_13 0 "normal" 1 "error" ;
VAL_ 389 VCU_FS_C_14 0 "normal" 1 "error" ;
VAL_ 389 VCU_FS_C_15 0 "normal" 1 "error" ;
VAL_ 389 VCU_FS_C_16 0 "normal" 1 "error" ;
VAL_ 389 VCU_FS_C_17 0 "normal" 1 "error" ;
VAL_ 389 VCU_FS_C_18 0 "normal" 1 "error" ;
VAL_ 389 VCU_FS_C_19 0 "normal" 1 "error" ;
VAL_ 389 VCU_FS_C_20 0 "normal" 1 "error" ;
VAL_ 389 VCU_FS_C_21 0 "normal" 1 "error" ;
VAL_ 389 VCU_FS_C_22 0 "normal" 1 "error" ;
VAL_ 389 VCU_FS_C_23 0 "normal" 1 "error" ;
VAL_ 389 VCU_FS_C_24 0 "normal" 1 "error" ;
VAL_ 389 VCU_FS_C_25 0 "normal" 1 "error" ;
VAL_ 389 VCU_FS_C_26 0 "normal" 1 "error" ;
VAL_ 389 VCU_FS_C_27 0 "normal" 1 "error" ;
VAL_ 389 VCU_FS_C_28 0 "normal" 1 "error" ;
VAL_ 389 VCU_FS_C_29 0 "normal" 1 "error" ;
VAL_ 389 VCU_FS_C_30 0 "normal" 1 "error" ;
VAL_ 389 VCU_FS_C_31 0 "normal" 1 "error" ;
VAL_ 389 VCU_FS_C_32 0 "normal" 1 "error" ;
VAL_ 389 VCU_FS_C_33 0 "normal" 1 "error" ;
VAL_ 389 VCU_FS_C_34 0 "normal" 1 "error" ;
VAL_ 389 VCU_FS_C_35 0 "normal" 1 "error" ;
VAL_ 389 VCU_FS_C_36 0 "normal" 1 "error" ;
VAL_ 389 VCU_FS_C_37 0 "normal" 1 "error" ;
VAL_ 389 VCU_FS_C_38 0 "normal" 1 "error" ;
VAL_ 389 VCU_FS_C_39 0 "normal" 1 "error" ;
VAL_ 389 VCU_FS_C_40 0 "normal" 1 "error" ;
VAL_ 389 VCU_FS_C_41 0 "normal" 1 "error" ;
VAL_ 389 VCU_FS_C_42 0 "normal" 1 "error" ;
VAL_ 389 VCU_FS_C_43 0 "normal" 1 "error" ;
VAL_ 389 VCU_FS_C_44 0 "normal" 1 "error" ;
VAL_ 389 VCU_FS_C_45 0 "normal" 1 "error" ;
VAL_ 389 VCU_FS_C_46 0 "normal" 1 "error" ;
VAL_ 389 VCU_FS_C_47 0 "normal" 1 "error" ;
VAL_ 389 VCU_FS_C_48 0 "normal" 1 "error" ;
VAL_ 389 VCU_FS_C_49 0 "normal" 1 "error" ;
VAL_ 389 VCU_FS_C_50 0 "normal" 1 "error" ;
VAL_ 389 VCU_FS_C_51 0 "normal" 1 "error" ;
VAL_ 389 VCU_FS_C_52 0 "normal" 1 "error" ;
VAL_ 389 VCU_FS_C_53 0 "normal" 1 "error" ;
VAL_ 389 VCU_FS_C_54 0 "normal" 1 "error" ;
VAL_ 389 VCU_FS_C_55 0 "normal" 1 "error" ;
VAL_ 389 VCU_FS_C_56 0 "normal" 1 "error" ;
VAL_ 389 VCU_FS_C_57 0 "normal" 1 "error" ;
VAL_ 389 VCU_FS_C_58 0 "normal" 1 "error" ;
VAL_ 389 VCU_FS_C_59 0 "normal" 1 "error" ;
VAL_ 389 VCU_FS_C_60 0 "normal" 1 "error" ;
VAL_ 389 VCU_FS_C_61 0 "normal" 1 "error" ;
VAL_ 389 VCU_FS_C_62 0 "normal" 1 "error" ;
VAL_ 389 VCU_FS_C_63 0 "normal" 1 "error" ;
VAL_ 389 VCU_FS_C_64 0 "normal" 1 "error" ;
VAL_ 417 DVCO_VEH 0 "Vehicle is stationary" 1 "Vehicle is moving forward" 2 "Vehicle is reversing" 3 "Vehicle is moving " 4 "Vehicle is stationary rear axle rol" 5 "Vehicle is stationary all axle roll" 6 "Vehicle is stationary Front axle roll" 7 "Signal invalid";
VAL_ 417 QU_V_VEH_COG 1 "Signal value is valid and secured and plausible" 2 "Reserved" 3 "Reserved" 4 "Reserved" 6 "Reserved" 7 "Reserved" 8 "Init" 9 "Reserved" 10 "Signal value is valid" 11 "Signal quality or monitoring limited" 12 "Reserved" 14 "Signal value is invalid" 15 "Signal invalid";
VAL_ 430 VCU_MaxTorq_Sts_FR 0 "NotInitialized" 1 "Normal" 2 "Faulty";
VAL_ 430 VCU_MinTorq_Sts_FR 0 "NotInitialized" 1 "Normal" 2 "Faulty";
VAL_ 431 VCU_MaxTorq_Sts_RR 0 "NotInitialized" 1 "Normal" 2 "Faulty";
VAL_ 431 VCU_MinTorq_Sts_RR 0 "NotInitialized" 1 "Normal" 2 "Faulty";
VAL_ 504 EDS_Work_STS_FR 0 "default" 1 "init" 2 "standby" 3 "precharge" 4 "normal" 5 "HVReady" 6 "6SO" 11 "shut down" 12 "after run" 13 "Failure" 14 "power off" 15 "invaild";
VAL_ 504 EDS_output_trqValid_FR 0 "invalid" 1 "valid";
VAL_ 504 EDS_MotorDriveSts_FR 0 "Zero control" 1 "Drive control" 2 "regen control" 3 "Invaild";
VAL_ 504 EDS_powoff_req_FR 0 "(No request)" 1 "(Request high voltage power down)";
VAL_ 504 EDS_SpdValid_FR 0 "invalid" 1 "valid";
VAL_ 504 EDS_VCU_6SO_flag_FWD 0 "OFF" 1 "ON";
VAL_ 505 EDS_Work_STS_RR 0 "default" 1 "init" 2 "standby" 3 "precharge" 4 "normal" 5 "HVReady" 6 "6SO" 11 "shut down" 12 "after run" 13 "Failure" 14 "power off" 15 "invaild";
VAL_ 505 EDS_output_trqValid_RR 0 "invalid" 1 "valid";
VAL_ 505 EDS_MotorDriveSts_RR 0 "Zero control" 1 "Drive control" 2 "regen control" 3 "Invaild";
VAL_ 505 EDS_powoff_req_RR 0 "(No request)" 1 "(Request high voltage power down)";
VAL_ 505 EDS_SpdValid_RR 0 "invalid" 1 "valid";
VAL_ 505 EDS_VCU_6SO_flag_RWD 0 "OFF" 1 "ON";
VAL_ 531 VCU_enableDCDC 0 "Request OFF" 1 "Request ON";
VAL_ 532 VCU_ADAS_ControledRes 0 "Inactive" 1 "Active";
VAL_ 532 VCU_ADAS_Available 0 "Available" 1 "Not Available";
VAL_ 532 VCU_ADAS_FuncMode 0 "Function Not Active" 1 "APA Mode" 2 "RP Mode" 3 "SM Mode";
VAL_ 532 VCU_ADAS_CtrlAbortFeedback 0 "normal" 1 "vehicle block" 2 "ESC Intervention" 3 "over speed" 4 "cannot change Gear" 5 "Driver intervence(gear)";
VAL_ 533 BMS_BatBalance_ERR 0 "Error" 1 "normal";
VAL_ 533 BMS_Balance_STS 0 "Inactive" 1 "active";
VAL_ 533 BMS_IGN_Sts 0 "OFF" 1 "ON";
VAL_ 533 BMS_HWCrash_Sts 0 "No Crash" 1 "Crash";
VAL_ 533 BMS_HVIL_STS 0 "Closed" 1 "Open & short to battery" 2 "short to ground" 3 "Signal invalid";
VAL_ 533 BMS_HVOnOff_STS 0 "HV Off" 1 "Precharge" 2 "HV On" 3 "Fail to HV on";
VAL_ 533 BMS_ERR_LEV 0 "No error" 1 "Warning" 2 "Limp Home" 3 "Power down without FTTI" 4 "Delay power down with FTTI" 5 "Emergency off condition" 6 "Fault, needs to shutdown and wakeup" 7 "Battery locked - reserved";
VAL_ 533 BMS_Sys_STS 0 "Initialization of power on, self-checking" 1 "Self-check passes, can be high-voltage" 2 "Successful High Voltage Power Up" 3 "Successful Power Down of HV" 4 "Power Down process" 5 "Successful Power Down" 6 "BCU Sleep mode" 7 "Failure, unable to operate" 8 "Invalid";
VAL_ 533 BMS_ISU_Status 0 "Normal (> 250 kOhms)" 1 "Level1 (<250 kOhms ~ >100 kOhms)" 3 "Level3 (<100 kOhms)";
VAL_ 533 BMS_HV_Sts 0 "HV Off" 1 "Pre Charge" 2 "HV On" 3 "Super_Fast_Charge" 4 "AC Charge" 5 "Undefined" 6 "Undefined" 7 "Undefined" 8 "Undefined" 9 "Undefined";
VAL_ 546 FRONT_SET_Rear_AirCondition 0 "Not pressed" 1 "Pressed" 2 "Reserved" 3 "Signal invalid";
VAL_ 553 VCU_EDS_StsModeReq_FWD 0 "default" 1 "init" 2 "standby" 3 "precharge" 4 "normal" 5 "HVReady" 11 "shut down" 12 "after run" 13 "Failure" 14 "power off" 15 "invaild";
VAL_ 553 VCU_EparkCMD_FWD 0 "Init (No Action)" 1 "Apply (Lock)" 2 "Release (Unlock)";
VAL_ 553 VCU_EDS_ActiveHeating_Request 0 "Disable" 1 "Enable";
VAL_ 553 VCU_EDS_CreepFlg_FWD 0 "Disable" 1 "Enable";
VAL_ 553 VCU_EDS_HILLHoldFlg_FWD 0 "Disable" 1 "Enable";
VAL_ 553 VCU_EDS_demtrqValid_FWD 0 "Valid" 1 "Invalid";
VAL_ 560 VCU_EDS_StsModeReq_RWD 0 "default" 1 "init" 2 "standby" 3 "precharge" 4 "normal" 5 "HVReady" 11 "shut down" 12 "after run" 13 "Failure" 14 "power off" 15 "invaild";
VAL_ 560 VCU_EDS_demtrqValid_RWD 0 "Valid" 1 "Invalid";
VAL_ 560 VCU_EDS_HILLHoldFlg_RWD 0 "Disable" 1 "Enable";
VAL_ 560 VCU_EDS_CreepFlg_RWD 0 "Disable" 1 "Enable";
VAL_ 565 TowingDetected 0 "Towing not detected" 1 "Towing detected" 3 "Invalid";
VAL_ 565 TrailerDetected 0 "Trailer not detected" 1 "Trailer detected" 3 "Invalid";
